VERSION "HINBNNNYNNNNNNNNNNNNNNNNNNNNNNNNNNNYYNNNNN/4>%%%/4/'%**4NNN///"

NS_ :

BS_:

BU_: Traffic Tester RCM FSC EPAS ECB DSC CGW

BO_ 960 IP_Switch_Information: 8 CGW
 SG_ HazardSw_D_Actl : 60|2@0+ (1,0) [0|0] ""  RCM
 SG_ RearDef_B_Rq : 61|1@0+ (1,0) [0|0] "" Vector__XXX
 SG_ FrontDef_B_Rq : 62|1@0+ (1,0) [0|0] "" Vector__XXX
 SG_ PanelHeaterSwitchIn_RH : 49|3@0+ (1,0) [0|0] "" Vector__XXX
 SG_ PanelHeaterSwitchIn_LH : 52|3@0+ (1,0) [0|0] "" Vector__XXX
 SG_ SteeringHeaterSwitchIn : 55|3@0+ (1,0) [0|0] "" Vector__XXX
 SG_ SeatVentilationSwitchIn_RH : 42|3@0+ (1,0) [0|0] "" Vector__XXX
 SG_ SeatHeaterSwitchIn_RH : 45|3@0+ (1,0) [0|0] "" Vector__XXX
 SG_ SeatVentilationSwitchIn_LH : 32|3@0+ (1,0) [0|0] "" Vector__XXX
 SG_ SeatHeaterSwitchIn_LH : 35|3@0+ (1,0) [0|0] "" Vector__XXX
 SG_ ipREARmode : 37|2@0+ (1,0) [0|0] "" Vector__XXX
 SG_ ipECOmode : 39|2@0+ (1,0) [0|0] "" Vector__XXX
 SG_ ipAImode : 27|4@0+ (1,0) [0|0] "" Vector__XXX
 SG_ ipADmode : 31|4@0+ (1,0) [0|0] "" Vector__XXX
 SG_ ipACmode : 19|4@0+ (1,0) [0|0] "" Vector__XXX
 SG_ ipBlwLvl : 23|4@0+ (1,0) [0|0] "" Vector__XXX
 SG_ ipTSetPs : 15|8@0+ (0.1,12) [12|37.5] "deg.C" Vector__XXX
 SG_ ipTSetDr : 7|8@0+ (0.1,12) [12|37.5] "deg.C" Vector__XXX

BO_ 945 ABG1S01: 8 RCM
 SG_ SM3B1 : 63|8@0+ (1,0) [0|255] ""  CGW
 SG_ CDT_HV : 34|3@0+ (1,0) [0|7] ""  CGW
 SG_ CDT : 22|3@0+ (1,0) [0|7] ""  CGW

BO_ 865 ENG1D70: 8 CGW
 SG_ EDRENG04 : 31|8@0+ (1,0) [0|255] ""  RCM
 SG_ EDRENG03 : 23|8@0+ (1,0) [0|255] ""  RCM
 SG_ EDRENG02 : 15|8@0+ (1,0) [0|255] ""  RCM
 SG_ EDRENG01 : 7|8@0+ (1,0) [0|255] ""  RCM

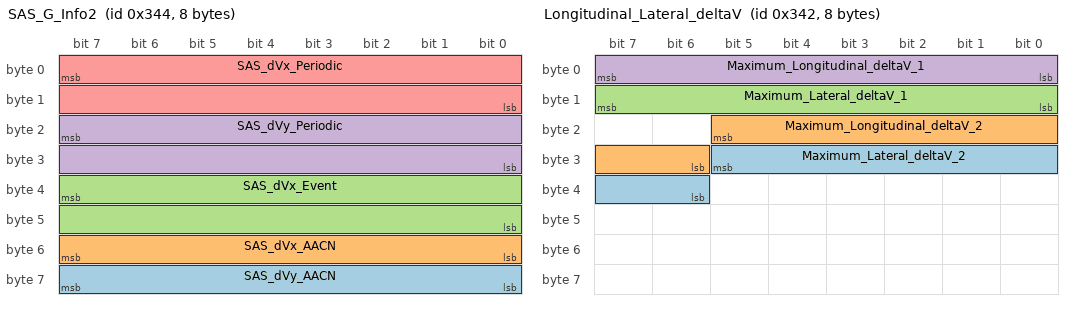
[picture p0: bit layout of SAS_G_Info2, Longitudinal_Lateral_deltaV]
BO_ 836 SAS_G_Info2: 8 RCM
 SG_ SAS_dVy_AACN : 63|8@0+ (1,-100) [-100|100] "km/h"  CGW
 SG_ SAS_dVx_AACN : 55|8@0+ (1,-100) [-100|100] "km/h"  CGW
 SG_ SAS_dVx_Event : 39|16@0+ (0.00353,-114.99681) [-114.99681|114.99681] "km/h"  CGW
 SG_ SAS_dVy_Periodic : 23|16@0+ (0.00353,-114.99681) [-114.99681|114.99681] "km/h"  CGW
 SG_ SAS_dVx_Periodic : 7|16@0+ (0.00353,-114.99681) [-114.99681|114.99681] "km/h"  CGW

BO_ 835 SAS_G_Info1: 8 RCM
 SG_ SAS_Gz : 19|14@0+ (0.0078125,-32) [-32|32] "G"  CGW
 SG_ SAS_Gy : 13|10@0+ (0.2,-96) [-96|96] "G"  CGW
 SG_ SAS_Gx : 7|10@0+ (0.2,-96) [-96|96] "G"  CGW

BO_ 834 Longitudinal_Lateral_deltaV: 8 RCM
 SG_ Maximum_Lateral_deltaV_2 : 29|8@0+ (1,-100) [-100|100] "km/h"  CGW
 SG_ Maximum_Longitudinal_deltaV_2 : 21|8@0+ (1,-100) [-100|100] "km/h"  CGW
 SG_ Maximum_Lateral_deltaV_1 : 15|8@0+ (1,-100) [-100|100] "km/h"  CGW
 SG_ Maximum_Longitudinal_deltaV_1 : 7|8@0+ (1,-100) [-100|100] "km/h"  CGW

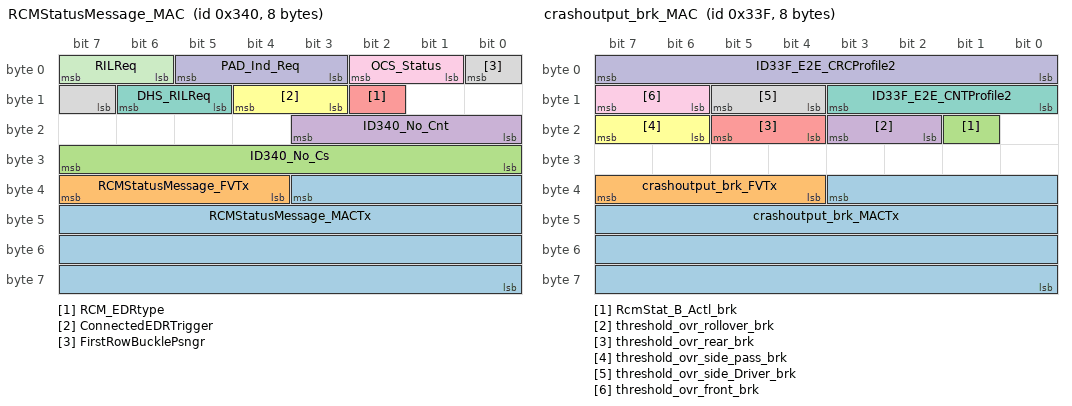
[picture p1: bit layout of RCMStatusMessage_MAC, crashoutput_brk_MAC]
BO_ 832 RCMStatusMessage_MAC: 8 RCM
 SG_ RCMStatusMessage_MACTx : 35|28@0+ (1,0) [0|268435455] ""  CGW
 SG_ RCMStatusMessage_FVTx : 39|4@0+ (1,0) [0|15] ""  CGW
 SG_ ID340_No_Cs : 31|8@0+ (1,0) [0|255] ""  CGW
 SG_ ID340_No_Cnt : 19|4@0+ (1,0) [0|15] ""  CGW
 SG_ RCM_EDRtype : 10|1@0+ (1,0) [0|0] ""  CGW
 SG_ ConnectedEDRTrigger : 12|2@0+ (1,0) [0|0] ""  CGW
 SG_ DHS_RILReq : 14|2@0+ (1,0) [0|0] ""  CGW
 SG_ FirstRowBucklePsngr : 0|2@0+ (1,0) [0|0] ""  CGW
 SG_ OCS_Status : 2|2@0+ (1,0) [0|0] ""  CGW
 SG_ PAD_Ind_Req : 5|3@0+ (1,0) [0|0] ""  CGW
 SG_ RILReq : 7|2@0+ (1,0) [0|0] ""  CGW

BO_ 831 crashoutput_brk_MAC: 8 RCM
 SG_ crashoutput_brk_MACTx : 35|28@0+ (1,0) [0|268435455] ""  DSC
 SG_ crashoutput_brk_FVTx : 39|4@0+ (1,0) [0|15] ""  DSC
 SG_ RcmStat_B_Actl_brk : 17|1@0+ (1,0) [0|0] ""  DSC
 SG_ threshold_ovr_rollover_brk : 19|2@0+ (1,0) [0|0] ""  DSC
 SG_ threshold_ovr_rear_brk : 21|2@0+ (1,0) [0|0] ""  DSC
 SG_ threshold_ovr_side_pass_brk : 23|2@0+ (1,0) [0|0] ""  DSC
 SG_ ID33F_E2E_CNTProfile2 : 11|4@0+ (1,0) [0|15] ""  DSC
 SG_ threshold_ovr_side_Driver_brk : 13|2@0+ (1,0) [0|0] ""  DSC
 SG_ threshold_ovr_front_brk : 15|2@0+ (1,0) [0|0] ""  DSC
 SG_ ID33F_E2E_CRCProfile2 : 7|8@0+ (1,0) [0|255] ""  DSC

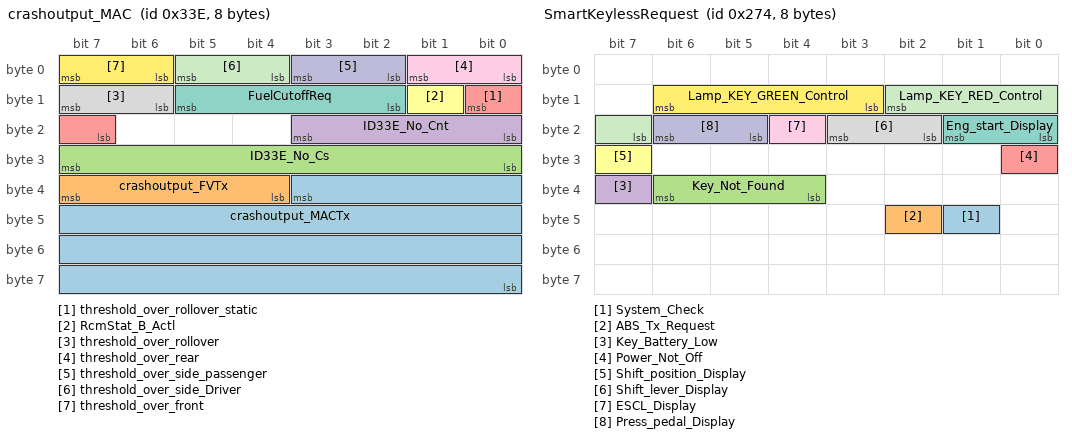
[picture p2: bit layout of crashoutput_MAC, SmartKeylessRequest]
BO_ 830 crashoutput_MAC: 8 RCM
 SG_ crashoutput_MACTx : 35|28@0+ (1,0) [0|268435455] ""  CGW
 SG_ crashoutput_FVTx : 39|4@0+ (1,0) [0|15] ""  CGW
 SG_ ID33E_No_Cs : 31|8@0+ (1,0) [0|255] ""  CGW
 SG_ ID33E_No_Cnt : 19|4@0+ (1,0) [0|15] ""  CGW
 SG_ threshold_over_rollover_static : 8|2@0+ (1,0) [0|0] ""  CGW
 SG_ RcmStat_B_Actl : 9|1@0+ (1,0) [0|0] ""  CGW
 SG_ FuelCutoffReq : 13|4@0+ (1,0) [0|0] ""  CGW
 SG_ threshold_over_rollover : 15|2@0+ (1,0) [0|0] ""  CGW
 SG_ threshold_over_rear : 1|2@0+ (1,0) [0|0] ""  CGW
 SG_ threshold_over_side_passenger : 3|2@0+ (1,0) [0|0] ""  CGW
 SG_ threshold_over_side_Driver : 5|2@0+ (1,0) [0|0] ""  CGW
 SG_ threshold_over_front : 7|2@0+ (1,0) [0|0] ""  CGW

BO_ 628 SmartKeylessRequest: 8 CGW
 SG_ System_Check : 41|1@0+ (1,0) [0|0] "" Vector__XXX
 SG_ ABS_Tx_Request : 42|1@0+ (1,0) [0|0] ""  DSC,ECB
 SG_ Key_Not_Found : 38|3@0+ (1,0) [0|0] "" Vector__XXX
 SG_ Key_Battery_Low : 39|1@0+ (1,0) [0|0] "" Vector__XXX
 SG_ Power_Not_Off : 24|1@0+ (1,0) [0|0] "" Vector__XXX
 SG_ Shift_position_Display : 31|1@0+ (1,0) [0|0] "" Vector__XXX
 SG_ Eng_start_Display : 17|2@0+ (1,0) [0|0] "" Vector__XXX
 SG_ Shift_lever_Display : 19|2@0+ (1,0) [0|0] "" Vector__XXX
 SG_ ESCL_Display : 20|1@0+ (1,0) [0|0] "" Vector__XXX
 SG_ Press_pedal_Display : 22|2@0+ (1,0) [0|0] "" Vector__XXX
 SG_ Lamp_KEY_RED_Control : 10|4@0+ (1,0) [0|0] "" Vector__XXX
 SG_ Lamp_KEY_GREEN_Control : 14|4@0+ (1,0) [0|0] "" Vector__XXX

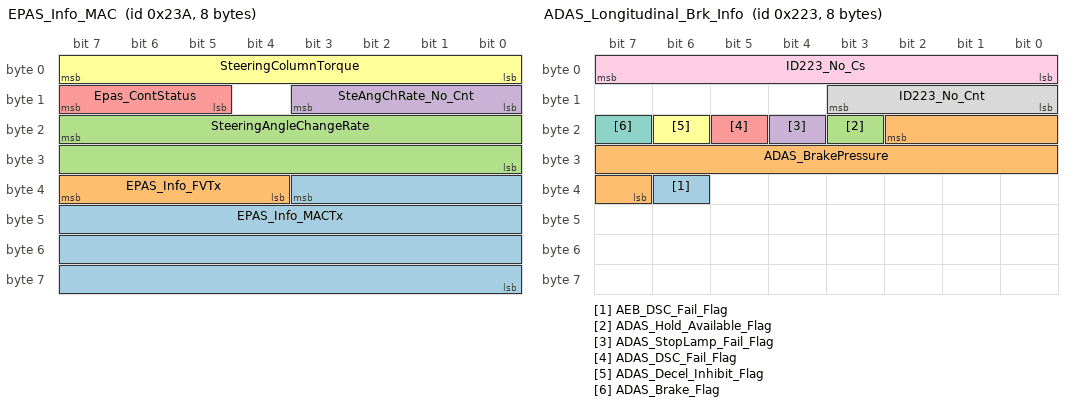
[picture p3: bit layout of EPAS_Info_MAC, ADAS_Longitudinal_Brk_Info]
BO_ 570 EPAS_Info_MAC: 8 EPAS
 SG_ EPAS_Info_MACTx : 35|28@0+ (1,0) [0|268435455] ""  CGW
 SG_ EPAS_Info_FVTx : 39|4@0+ (1,0) [0|15] ""  CGW
 SG_ SteeringAngleChangeRate : 23|16@0- (0.1,0) [-3276.8|3276.7] "deg/s"  CGW
 SG_ SteAngChRate_No_Cnt : 11|4@0+ (1,0) [0|15] ""  CGW
 SG_ Epas_ContStatus : 15|3@0+ (1,0) [0|0] ""  CGW
 SG_ SteeringColumnTorque : 7|8@0+ (0.1,-12.7) [-12.7|12.8] "Nm"  CGW

BO_ 552 TransGearData: 8 CGW
 SG_ ID228_No_Cs : 63|8@0+ (1,0) [0|255] "" Vector__XXX
 SG_ ID228_No_Cnt : 51|4@0+ (1,0) [0|15] "" Vector__XXX
 SG_ ShiftOpeWarning_D_Rq : 55|4@0+ (1,0) [0|0] "" Vector__XXX
 SG_ ShiftPos_D_Act : 43|4@0+ (1,0) [0|0] "" Vector__XXX
 SG_ TransmChangeLeverPosition : 47|4@0+ (1,0) [0|0] "" Vector__XXX
 SG_ DispAtLvrPos_ArrowReq : 32|1@0+ (1,0) [0|0] "" Vector__XXX
 SG_ ShiftPos_D_Trg : 36|4@0+ (1,0) [0|0] ""  RCM
 SG_ DispAtLvrPos_Off_Req : 37|1@0+ (1,0) [0|0] "" Vector__XXX
 SG_ AT_INDLvl_D_Rq : 39|2@0+ (1,0) [0|0] "" Vector__XXX
 SG_ AT_FailSafeLvl_D_Rq : 25|2@0+ (1,0) [0|0] "" Vector__XXX
 SG_ PwrDwn_D_Req_ByTCM : 27|2@0+ (1,0) [0|0] "" Vector__XXX
 SG_ SBW_INDLvl_D_Rq : 29|2@0+ (1,0) [0|0] "" Vector__XXX
 SG_ ParkLockWarning_D_Rq : 31|2@0+ (1,0) [0|0] "" Vector__XXX
 SG_ ShiftrPos_D_Qf : 17|2@0+ (1,0) [0|0] "" Vector__XXX
 SG_ SbwWarningLamp_B_Rq : 18|1@0+ (1,0) [0|0] "" Vector__XXX
 SG_ TransmParking_D_Act : 21|3@0+ (1,0) [0|0] "" Vector__XXX
 SG_ TrnSlaCtl_B_Rq : 22|1@0+ (1,0) [0|0] "" Vector__XXX
 SG_ TrnSlaCtlFlag : 23|1@0+ (1,0) [0|0] "" Vector__XXX
 SG_ TrnShifActv_B_Actl : 8|1@0+ (1,0) [0|0] "" Vector__XXX
 SG_ AT_OILTEMPHi_D_Rq : 10|2@0+ (1,0) [0|0] "" Vector__XXX
 SG_ TrnCnvtClu_D_Actl : 12|2@0+ (1,0) [0|0] "" Vector__XXX
 SG_ DispGearPos_FlashReq : 13|1@0+ (1,0) [0|0] "" Vector__XXX
 SG_ OD_Hold_Sport_Flash : 14|1@0+ (1,0) [0|0] "" Vector__XXX
 SG_ DispAtLvrPos_FlashReq : 15|1@0+ (1,0) [0|0] "" Vector__XXX
 SG_ DispAtLvrPos_D_Rq : 3|4@0+ (1,0) [0|0] "" Vector__XXX
 SG_ DispGearPos_D_Rq : 7|4@0+ (1,0) [0|0] "" Vector__XXX

BO_ 547 ADAS_Longitudinal_Brk_Info: 8 DSC
 SG_ AEB_DSC_Fail_Flag : 38|1@0+ (1,0) [0|0] ""  CGW
 SG_ ADAS_BrakePressure : 18|12@0+ (1,-94) [-94|4000] "Nm"  CGW
 SG_ ADAS_Hold_Available_Flag : 19|1@0+ (1,0) [0|0] ""  CGW
 SG_ ADAS_StopLamp_Fail_Flag : 20|1@0+ (1,0) [0|0] ""  CGW
 SG_ ADAS_DSC_Fail_Flag : 21|1@0+ (1,0) [0|0] ""  CGW
 SG_ ADAS_Decel_Inhibit_Flag : 22|1@0+ (1,0) [0|0] ""  CGW
 SG_ ADAS_Brake_Flag : 23|1@0+ (1,0) [0|0] ""  CGW
 SG_ ID223_No_Cnt : 11|4@0+ (1,0) [0|15] ""  CGW
 SG_ ID223_No_Cs : 7|8@0+ (1,0) [0|255] ""  CGW

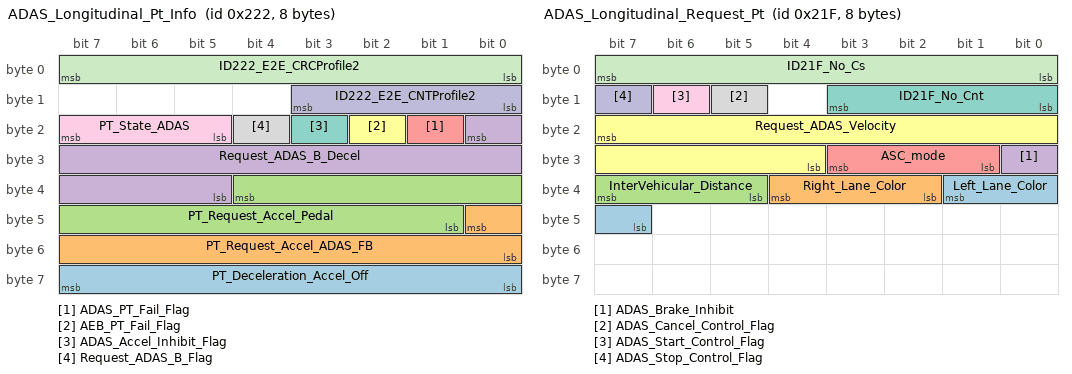
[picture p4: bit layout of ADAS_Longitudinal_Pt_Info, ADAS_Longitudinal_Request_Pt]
BO_ 546 ADAS_Longitudinal_Pt_Info: 8 DSC
 SG_ PT_Deceleration_Accel_Off : 63|8@0+ (0.02,-2.5) [-2.5|2.5] "m/sec2"  CGW
 SG_ PT_Request_Accel_ADAS_FB : 40|9@0+ (0.01,-2.5) [-2.5|2.5] "m/sec2"  CGW
 SG_ PT_Request_Accel_Pedal : 36|12@0+ (0.01,-20) [-20|20] "m/sec2"  CGW
 SG_ Request_ADAS_B_Decel : 16|12@0+ (0.005,-10) [-10|10] "m/sec2"  CGW
 SG_ ADAS_PT_Fail_Flag : 17|1@0+ (1,0) [0|0] ""  CGW
 SG_ AEB_PT_Fail_Flag : 18|1@0+ (1,0) [0|0] ""  CGW
 SG_ ADAS_Accel_Inhibit_Flag : 19|1@0+ (1,0) [0|0] ""  CGW
 SG_ Request_ADAS_B_Flag : 20|1@0+ (1,0) [0|0] ""  CGW
 SG_ PT_State_ADAS : 23|3@0+ (1,0) [0|0] ""  CGW
 SG_ ID222_E2E_CNTProfile2 : 11|4@0+ (1,0) [0|15] ""  CGW
 SG_ ID222_E2E_CRCProfile2 : 7|8@0+ (1,0) [0|255] ""  CGW

BO_ 543 ADAS_Longitudinal_Request_Pt: 8 CGW
 SG_ Left_Lane_Color : 33|3@0+ (1,0) [0|0] ""  DSC
 SG_ Right_Lane_Color : 36|3@0+ (1,0) [0|0] ""  DSC
 SG_ InterVehicular_Distance : 39|3@0+ (1,0) [0|0] ""  DSC
 SG_ ADAS_Brake_Inhibit : 24|1@0+ (1,0) [0|0] ""  DSC
 SG_ ASC_mode : 27|3@0+ (1,0) [0|0] ""  DSC
 SG_ Request_ADAS_Velocity : 23|12@0+ (0.05,0) [0|200] "km/h"  DSC
 SG_ ID21F_No_Cnt : 11|4@0+ (1,0) [0|15] ""  DSC
 SG_ ADAS_Cancel_Control_Flag : 13|1@0+ (1,0) [0|0] ""  DSC
 SG_ ADAS_Start_Control_Flag : 14|1@0+ (1,0) [0|0] ""  DSC
 SG_ ADAS_Stop_Control_Flag : 15|1@0+ (1,0) [0|0] ""  DSC
 SG_ ID21F_No_Cs : 7|8@0+ (1,0) [0|255] ""  DSC

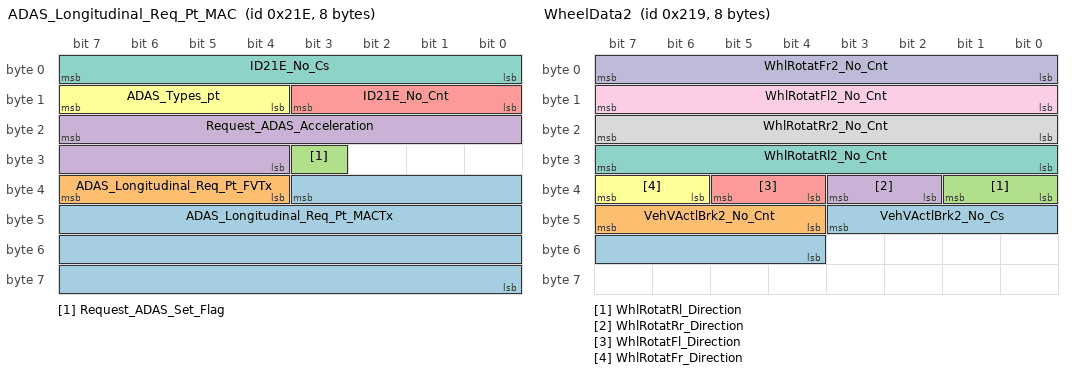
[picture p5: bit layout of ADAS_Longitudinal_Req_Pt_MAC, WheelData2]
BO_ 542 ADAS_Longitudinal_Req_Pt_MAC: 8 CGW
 SG_ ADAS_Longitudinal_Req_Pt_MACTx : 35|28@0+ (1,0) [0|268435455] ""  DSC
 SG_ ADAS_Longitudinal_Req_Pt_FVTx : 39|4@0+ (1,0) [0|15] ""  DSC
 SG_ Request_ADAS_Set_Flag : 27|1@0+ (1,0) [0|0] ""  DSC
 SG_ Request_ADAS_Acceleration : 23|12@0+ (0.005,-10) [-10|10] "m/sec2"  DSC
 SG_ ID21E_No_Cnt : 11|4@0+ (1,0) [0|15] ""  DSC
 SG_ ADAS_Types_pt : 15|4@0+ (1,0) [0|0] ""  DSC
 SG_ ID21E_No_Cs : 7|8@0+ (1,0) [0|255] ""  DSC

BO_ 537 WheelData2: 8 DSC
 SG_ VehVActlBrk2_No_Cs : 43|8@0+ (1,0) [0|255] ""  CGW
 SG_ VehVActlBrk2_No_Cnt : 47|4@0+ (1,0) [0|15] ""  CGW
 SG_ WhlRotatRl_Direction : 33|2@0+ (1,0) [0|0] ""  CGW
 SG_ WhlRotatRr_Direction : 35|2@0+ (1,0) [0|0] ""  CGW
 SG_ WhlRotatFl_Direction : 37|2@0+ (1,0) [0|0] ""  CGW
 SG_ WhlRotatFr_Direction : 39|2@0+ (1,0) [0|0] ""  CGW
 SG_ WhlRotatRl2_No_Cnt : 31|8@0+ (1,0) [0|255] ""  CGW
 SG_ WhlRotatRr2_No_Cnt : 23|8@0+ (1,0) [0|255] ""  CGW
 SG_ WhlRotatFl2_No_Cnt : 15|8@0+ (1,0) [0|255] ""  CGW
 SG_ WhlRotatFr2_No_Cnt : 7|8@0+ (1,0) [0|255] ""  CGW

BO_ 533 WheelSpeed: 8 DSC
 SG_ RRwheelSpeed : 55|16@0+ (0.01,-100) [-100|300] "km/h"  CGW,EPAS
 SG_ RLwheelSpeed : 39|16@0+ (0.01,-100) [-100|300] "km/h"  CGW,EPAS
 SG_ FRwheelSpeed : 23|16@0+ (0.01,-100) [-100|300] "km/h"  CGW,EPAS
 SG_ FLwheelSpeed : 7|16@0+ (0.01,-100) [-100|300] "km/h"  CGW,EPAS

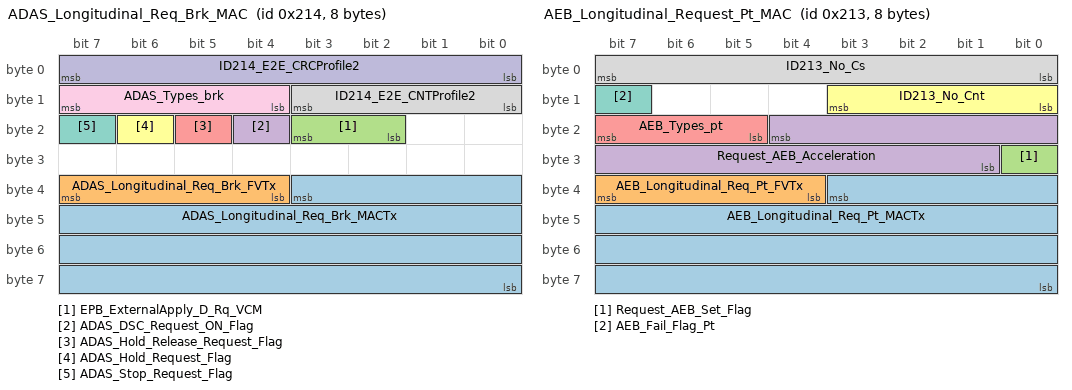
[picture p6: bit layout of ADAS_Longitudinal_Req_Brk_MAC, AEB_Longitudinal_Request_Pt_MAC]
BO_ 532 ADAS_Longitudinal_Req_Brk_MAC: 8 CGW
 SG_ ADAS_Longitudinal_Req_Brk_MACTx : 35|28@0+ (1,0) [0|268435455] ""  DSC
 SG_ ADAS_Longitudinal_Req_Brk_FVTx : 39|4@0+ (1,0) [0|15] ""  DSC
 SG_ EPB_ExternalApply_D_Rq_VCM : 19|2@0+ (1,0) [0|0] ""  DSC
 SG_ ADAS_DSC_Request_ON_Flag : 20|1@0+ (1,0) [0|0] ""  DSC
 SG_ ADAS_Hold_Release_Request_Flag : 21|1@0+ (1,0) [0|0] ""  DSC
 SG_ ADAS_Hold_Request_Flag : 22|1@0+ (1,0) [0|0] ""  DSC
 SG_ ADAS_Stop_Request_Flag : 23|1@0+ (1,0) [0|0] ""  DSC
 SG_ ID214_E2E_CNTProfile2 : 11|4@0+ (1,0) [0|15] ""  DSC
 SG_ ADAS_Types_brk : 15|4@0+ (1,0) [0|0] ""  DSC
 SG_ ID214_E2E_CRCProfile2 : 7|8@0+ (1,0) [0|255] ""  DSC

BO_ 531 AEB_Longitudinal_Request_Pt_MAC: 8 CGW
 SG_ AEB_Longitudinal_Req_Pt_MACTx : 35|28@0+ (1,0) [0|268435455] ""  DSC
 SG_ AEB_Longitudinal_Req_Pt_FVTx : 39|4@0+ (1,0) [0|15] ""  DSC
 SG_ Request_AEB_Set_Flag : 24|1@0+ (1,0) [0|0] ""  DSC,RCM
 SG_ Request_AEB_Acceleration : 20|12@0+ (0.005,-10) [-10|10] "m/sec2"  DSC,RCM
 SG_ AEB_Types_pt : 23|3@0+ (1,0) [0|0] ""  DSC,RCM
 SG_ ID213_No_Cnt : 11|4@0+ (1,0) [0|15] ""  DSC
 SG_ AEB_Fail_Flag_Pt : 15|1@0+ (1,0) [0|0] ""  DSC
 SG_ ID213_No_Cs : 7|8@0+ (1,0) [0|255] ""  DSC

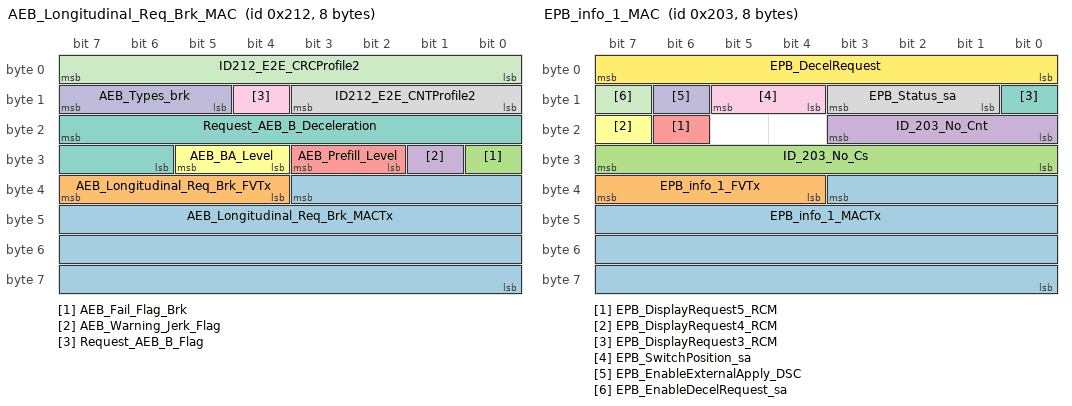
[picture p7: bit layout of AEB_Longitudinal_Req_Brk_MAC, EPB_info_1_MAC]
BO_ 530 AEB_Longitudinal_Req_Brk_MAC: 8 CGW
 SG_ AEB_Longitudinal_Req_Brk_MACTx : 35|28@0+ (1,0) [0|268435455] ""  DSC,RCM
 SG_ AEB_Longitudinal_Req_Brk_FVTx : 39|4@0+ (1,0) [0|15] ""  DSC,RCM
 SG_ AEB_Fail_Flag_Brk : 24|1@0+ (1,0) [0|0] ""  DSC,RCM
 SG_ AEB_Warning_Jerk_Flag : 25|1@0+ (1,0) [0|0] ""  DSC
 SG_ AEB_Prefill_Level : 27|2@0+ (1,0) [0|0] ""  DSC
 SG_ AEB_BA_Level : 29|2@0+ (1,0) [0|0] ""  DSC
 SG_ Request_AEB_B_Deceleration : 23|10@0+ (0.01,0) [0|10.23] "m/sec2"  DSC,RCM
 SG_ ID212_E2E_CNTProfile2 : 11|4@0+ (1,0) [0|15] ""  DSC
 SG_ Request_AEB_B_Flag : 12|1@0+ (1,0) [0|0] ""  DSC,RCM
 SG_ AEB_Types_brk : 15|3@0+ (1,0) [0|0] ""  DSC
 SG_ ID212_E2E_CRCProfile2 : 7|8@0+ (1,0) [0|255] ""  DSC

BO_ 520 DesiredTorqBrk_MAC: 8 DSC
 SG_ DesiredTorqBrk_MACTx : 35|28@0+ (1,0) [0|268435455] ""  CGW,RCM
 SG_ DesiredTorqBrk_FVTx : 39|4@0+ (1,0) [0|15] ""  CGW,RCM
 SG_ PrplWhlTqRqMn_MAC_No_Cs : 31|8@0+ (1,0) [0|255] ""  CGW,RCM
 SG_ PrplWhlTqRqMn_MAC_No_Cnt : 19|4@0+ (1,0) [0|15] ""  CGW,RCM
 SG_ AccPedalPos : 11|8@0+ (0.5,0) [0|100] "%"  CGW,RCM
 SG_ ADAS_Brake_Flag_copy : 12|1@0+ (1,0) [0|0] ""  CGW
 SG_ Abs_B_Falt : 13|1@0+ (1,0) [0|0] ""  CGW,RCM
 SG_ TsaCtlActv_B_Actl : 14|1@0+ (1,0) [0|0] ""  CGW
 SG_ RolStabCtlActv_B_Actl : 15|1@0+ (1,0) [0|0] ""  CGW
 SG_ PrplDrgCtlActv_B_Actl : 0|1@0+ (1,0) [0|0] ""  CGW
 SG_ TracCtlPtActv_B_Actl : 1|1@0+ (1,0) [0|0] ""  CGW,RCM
 SG_ TracCtlBrkActv_B_Actl : 2|1@0+ (1,0) [0|0] ""  CGW,RCM
 SG_ DSC_OnOff_status_1 : 3|1@0+ (1,0) [0|0] ""  CGW
 SG_ StabCtlBrkActv_B_Actl : 4|1@0+ (1,0) [0|0] ""  CGW,RCM
 SG_ BrkAsst_B_Actl : 5|1@0+ (1,0) [0|0] ""  CGW
 SG_ AbsActv_B_Actl : 6|1@0+ (1,0) [0|0] ""  CGW,RCM
 SG_ EbdActv_B_Actl : 7|1@0+ (1,0) [0|0] ""  CGW

BO_ 515 EPB_info_1_MAC: 8 CGW
 SG_ EPB_info_1_MACTx : 35|28@0+ (1,0) [0|268435455] ""  DSC,RCM,ECB
 SG_ EPB_info_1_FVTx : 39|4@0+ (1,0) [0|15] ""  DSC,RCM,ECB
 SG_ ID_203_No_Cs : 31|8@0+ (1,0) [0|255] ""  DSC,ECB
 SG_ ID_203_No_Cnt : 19|4@0+ (1,0) [0|15] ""  DSC,ECB
 SG_ EPB_DisplayRequest5_RCM : 22|1@0+ (1,0) [0|0] ""  RCM
 SG_ EPB_DisplayRequest4_RCM : 23|1@0+ (1,0) [0|0] ""  RCM
 SG_ EPB_DisplayRequest3_RCM : 8|1@0+ (1,0) [0|0] ""  RCM
 SG_ EPB_Status_sa : 11|3@0+ (1,0) [0|0] ""  DSC,RCM,ECB
 SG_ EPB_SwitchPosition_sa : 13|2@0+ (1,0) [0|0] ""  DSC,ECB
 SG_ EPB_EnableExternalApply_DSC : 14|1@0+ (1,0) [0|0] ""  DSC
 SG_ EPB_EnableDecelRequest_sa : 15|1@0+ (1,0) [0|0] ""  DSC
 SG_ EPB_DecelRequest : 7|8@0+ (0.048,-7.968) [-7.968|4.224] "m/s^2"  DSC

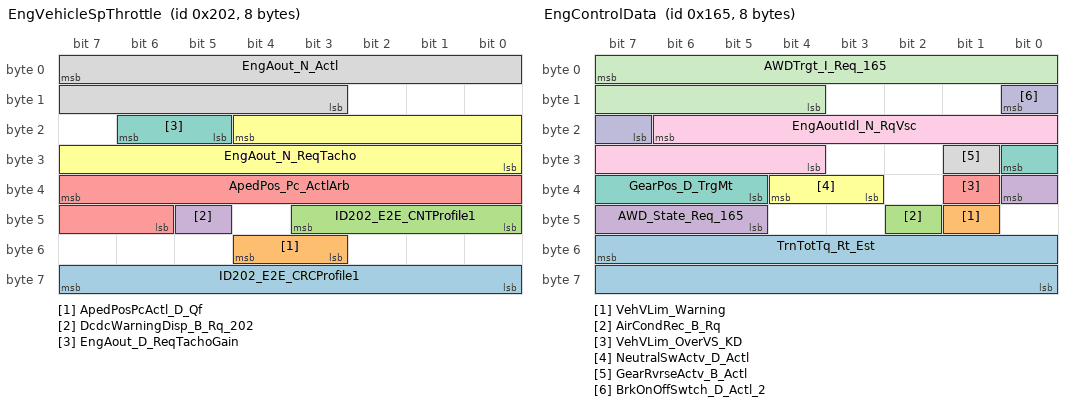
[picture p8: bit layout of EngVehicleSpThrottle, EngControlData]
BO_ 514 EngVehicleSpThrottle: 8 CGW
 SG_ ID202_E2E_CRCProfile1 : 63|8@0+ (1,0) [0|255] ""  RCM
 SG_ ApedPosPcActl_D_Qf : 52|2@0+ (1,0) [0|0] ""  RCM
 SG_ ID202_E2E_CNTProfile1 : 43|4@0+ (1,0) [0|14] "" Vector__XXX
 SG_ DcdcWarningDisp_B_Rq_202 : 45|1@0+ (1,0) [0|0] "" Vector__XXX
 SG_ ApedPos_Pc_ActlArb : 39|10@0+ (0.1,0) [0|102.3] "%"  RCM
 SG_ EngAout_N_ReqTacho : 20|13@0+ (2,0) [0|16380] "rpm" Vector__XXX
 SG_ EngAout_D_ReqTachoGain : 22|2@0+ (1,0) [0|0] "" Vector__XXX
 SG_ EngAout_N_Actl : 7|13@0+ (2,0) [0|16380] "rpm"  RCM,EPAS

BO_ 357 EngControlData: 8 CGW
 SG_ TrnTotTq_Rt_Est : 55|16@0+ (0.001,0) [0|65.533] "" Vector__XXX
 SG_ VehVLim_Warning : 41|1@0+ (1,0) [0|0] "" Vector__XXX
 SG_ AirCondRec_B_Rq : 42|1@0+ (1,0) [0|0] "" Vector__XXX
 SG_ AWD_State_Req_165 : 32|4@0+ (1,0) [0|0] "" Vector__XXX
 SG_ VehVLim_OverVS_KD : 33|1@0+ (1,0) [0|0] "" Vector__XXX
 SG_ NeutralSwActv_D_Actl : 36|2@0+ (1,0) [0|0] ""  RCM
 SG_ GearPos_D_TrgMt : 24|4@0+ (1,0) [0|0] ""  RCM
 SG_ GearRvrseActv_B_Actl : 25|1@0+ (1,0) [0|0] "" Vector__XXX
 SG_ EngAoutIdl_N_RqVsc : 22|11@0+ (2,0) [0|4094] "rpm" Vector__XXX
 SG_ BrkOnOffSwtch_D_Actl_2 : 8|2@0+ (1,0) [0|0] ""  RCM
 SG_ AWDTrgt_I_Req_165 : 7|12@0+ (0.015,0) [0|6] "A" Vector__XXX

BO_ 304 SISS_Rqst: 8 CGW
 SG_ Clutch_Stroke : 63|8@0+ (0.5,0) [0|100] "%" Vector__XXX
 SG_ EngAout_N_RqTacho : 44|13@0+ (2,0) [0|16382] "RPM" Vector__XXX
 SG_ PTiStpRdy_B_Actl : 32|1@0+ (1,0) [0|0] "" Vector__XXX
 SG_ iStpDenyBrk_B_Actl : 33|1@0+ (1,0) [0|0] "" Vector__XXX
 SG_ iStpDenyPwStr_B_Actl : 34|1@0+ (1,0) [0|0] "" Vector__XXX
 SG_ iStpKeySta_B_Actl : 35|1@0+ (1,0) [0|0] "" Vector__XXX
 SG_ iStpDenyAC_B_Actl : 36|1@0+ (1,0) [0|0] "" Vector__XXX
 SG_ iStpDenyNrange_B_Actl : 37|1@0+ (1,0) [0|0] "" Vector__XXX
 SG_ iStpDenyDPF_B_Actl : 38|1@0+ (1,0) [0|0] "" Vector__XXX
 SG_ ELM_IRCutReq : 25|1@0+ (1,0) [0|0] "" Vector__XXX
 SG_ BatteryWeakenFlag : 26|1@0+ (1,0) [0|0] "" Vector__XXX
 SG_ iStpDoorOpen_B_Actl : 27|1@0+ (1,0) [0|0] "" Vector__XXX
 SG_ SISS_EngineState : 31|4@0+ (1,0) [0|0] ""  EPAS
 SG_ SISS_IRCutReq : 16|1@0+ (1,0) [0|0] "" Vector__XXX
 SG_ SKE_Control : 18|2@0+ (1,0) [0|0] "" Vector__XXX
 SG_ SISS_Mode_for_SKE : 19|1@0+ (1,0) [0|0] "" Vector__XXX
 SG_ iStpReady_Rq : 20|1@0+ (1,0) [0|0] "" Vector__XXX
 SG_ iStpDenyBatt_B_Actl : 21|1@0+ (1,0) [0|0] "" Vector__XXX
 SG_ SlaCtl_B_Rq : 22|1@0+ (1,0) [0|0] "" Vector__XXX
 SG_ SISS_WarningLamp_R : 9|3@0+ (1,0) [0|0] "" Vector__XXX
 SG_ SISS_WarningLamp_G : 12|3@0+ (1,0) [0|0] "" Vector__XXX
 SG_ SISS_AlarmBuzzer : 15|3@0+ (1,0) [0|0] "" Vector__XXX
 SG_ SISSStatus : 0|1@0+ (1,0) [0|0] "" Vector__XXX
 SG_ SrlyUpper_Connect_Rq : 2|2@0+ (1,0) [0|0] "" Vector__XXX

BO_ 253 ECM_Status: 8 CGW
 SG_ Xev_Charge_Req_PCM : 58|3@0+ (1,0) [0|0] "" Vector__XXX
 SG_ PTGeneralWarn_Mirror : 59|1@0+ (1,0) [0|0] "" Vector__XXX
 SG_ Drive_Mode_Req_PCM : 63|4@0+ (1,0) [0|0] "" Vector__XXX
 SG_ Drive_Mode_Towing_Req_PCM : 49|2@0+ (1,0) [0|0] "" Vector__XXX
 SG_ Drive_Mode_OffRoad_Req_PCM : 51|2@0+ (1,0) [0|0] "" Vector__XXX
 SG_ Drive_Mode_Sport_Req_PCM : 53|2@0+ (1,0) [0|0] "" Vector__XXX
 SG_ Drive_Mode_Normal_Req_PCM : 55|2@0+ (1,0) [0|0] "" Vector__XXX
 SG_ ATFalseStartWarning : 40|1@0+ (1,0) [0|0] "" Vector__XXX
 SG_ BattRgenStat_B_Actl : 41|1@0+ (1,0) [0|0] "" Vector__XXX
 SG_ RegenBrkFailWarning : 42|1@0+ (1,0) [0|0] "" Vector__XXX
 SG_ BmsWarn_B_Rq : 43|1@0+ (1,0) [0|0] "" Vector__XXX
 SG_ SmtAclInh_B_Actl : 44|1@0+ (1,0) [0|0] "" Vector__XXX
 SG_ BrakeSw_Fail_Warning : 45|1@0+ (1,0) [0|0] "" Vector__XXX
 SG_ BOS_Active_B_Actl : 46|1@0+ (1,0) [0|0] "" Vector__XXX
 SG_ DriveMode_Hold_Rq_PCM : 47|1@0+ (1,0) [0|0] "" Vector__XXX
 SG_ GlobalConfgWarn_B_Rq : 32|1@0+ (1,0) [0|0] "" Vector__XXX
 SG_ CrankingTime : 37|5@0+ (1,0) [2|31] "sec" Vector__XXX
 SG_ ApedOnN_B_Rq : 38|1@0+ (1,0) [0|0] "" Vector__XXX
 SG_ IG_OFF_Delay_Request : 39|1@0+ (1,0) [0|0] "" Vector__XXX
 SG_ Crank_wait : 31|8@0+ (1,0) [0|0] "" Vector__XXX
 SG_ SilGearPosActl_D_Dsply : 19|4@0+ (1,0) [0|0] "" Vector__XXX
 SG_ Xev_Ev_Req_PCM : 22|3@0+ (1,0) [0|0] "" Vector__XXX
 SG_ VspLmtAlarm_B_Rq : 23|1@0+ (1,0) [0|0] "" Vector__XXX
 SG_ PTGeneralWarn_B_Rq : 8|1@0+ (1,0) [0|0] "" Vector__XXX
 SG_ SRLY_state : 9|1@0+ (1,0) [0|0] "" Vector__XXX
 SG_ SilGearPos_D_Dsply : 13|4@0+ (1,0) [0|0] "" Vector__XXX
 SG_ VspLmtWarn_B_Rq : 15|2@0+ (1,0) [0|0] "" Vector__XXX
 SG_ KeyState : 2|3@0+ (1,0) [0|0] "" Vector__XXX
 SG_ ShiftIndicatorLight : 4|2@0+ (1,0) [0|0] "" Vector__XXX
 SG_ PowerSourceStatus : 7|3@0+ (1,0) [0|0] ""  RCM,EPAS

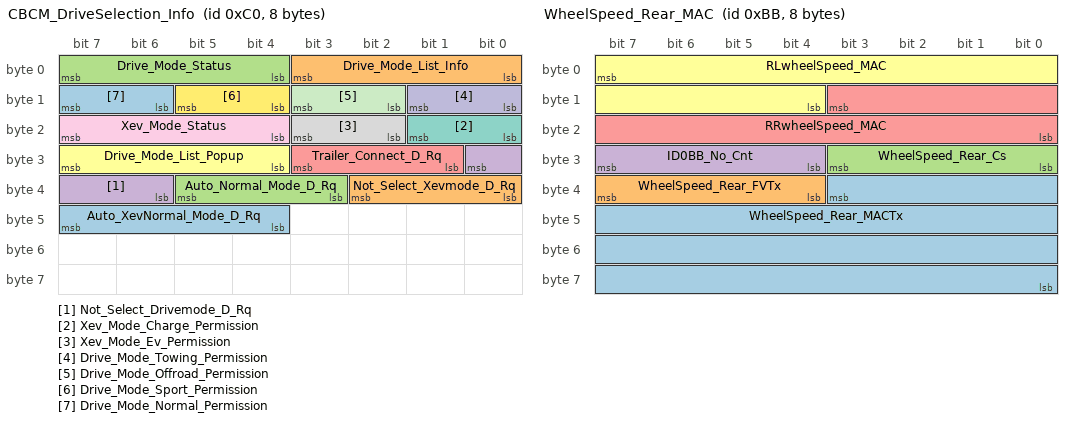
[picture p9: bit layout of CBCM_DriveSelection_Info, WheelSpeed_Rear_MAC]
BO_ 192 CBCM_DriveSelection_Info: 8 CGW
 SG_ Auto_XevNormal_Mode_D_Rq : 47|4@0+ (1,0) [0|0] "" Vector__XXX
 SG_ Not_Select_Xevmode_D_Rq : 34|3@0+ (1,0) [0|0] "" Vector__XXX
 SG_ Auto_Normal_Mode_D_Rq : 37|3@0+ (1,0) [0|0] "" Vector__XXX
 SG_ Not_Select_Drivemode_D_Rq : 24|3@0+ (1,0) [0|0] "" Vector__XXX
 SG_ Trailer_Connect_D_Rq : 27|3@0+ (1,0) [0|0] "" Vector__XXX
 SG_ Drive_Mode_List_Popup : 31|4@0+ (1,0) [0|0] "" Vector__XXX
 SG_ Xev_Mode_Charge_Permission : 17|2@0+ (1,0) [0|0] "" Vector__XXX
 SG_ Xev_Mode_Ev_Permission : 19|2@0+ (1,0) [0|0] "" Vector__XXX
 SG_ Xev_Mode_Status : 23|4@0+ (1,0) [0|0] "" Vector__XXX
 SG_ Drive_Mode_Towing_Permission : 9|2@0+ (1,0) [0|0] "" Vector__XXX
 SG_ Drive_Mode_Offroad_Permission : 11|2@0+ (1,0) [0|0] "" Vector__XXX
 SG_ Drive_Mode_Sport_Permission : 13|2@0+ (1,0) [0|0] "" Vector__XXX
 SG_ Drive_Mode_Normal_Permission : 15|2@0+ (1,0) [0|0] "" Vector__XXX
 SG_ Drive_Mode_List_Info : 3|4@0+ (1,0) [0|0] "" Vector__XXX
 SG_ Drive_Mode_Status : 7|4@0+ (1,0) [0|0] ""  DSC

BO_ 187 WheelSpeed_Rear_MAC: 8 DSC
 SG_ WheelSpeed_Rear_MACTx : 35|28@0+ (1,0) [0|268435455] ""  CGW
 SG_ WheelSpeed_Rear_FVTx : 39|4@0+ (1,0) [0|15] ""  CGW
 SG_ WheelSpeed_Rear_Cs : 27|4@0+ (1,0) [0|15] ""  CGW
 SG_ ID0BB_No_Cnt : 31|4@0+ (1,0) [0|15] ""  CGW
 SG_ RRwheelSpeed_MAC : 11|12@0+ (0.1,0) [0|300] "km/h"  CGW
 SG_ RLwheelSpeed_MAC : 7|12@0+ (0.1,0) [0|300] "km/h"  CGW

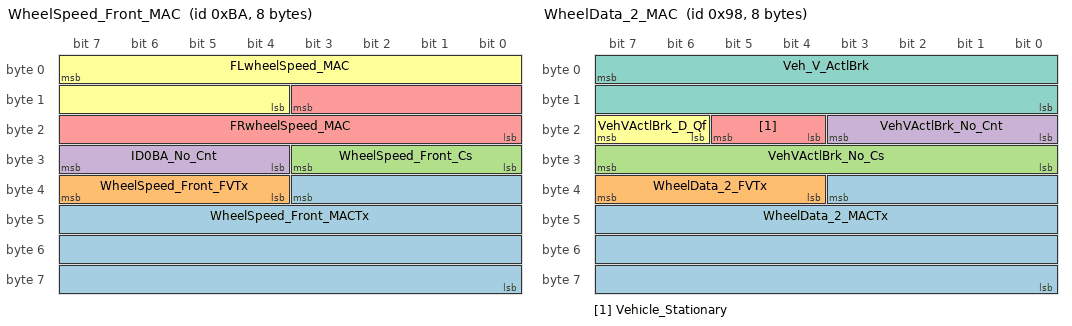
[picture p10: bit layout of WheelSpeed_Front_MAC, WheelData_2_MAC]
BO_ 186 WheelSpeed_Front_MAC: 8 DSC
 SG_ WheelSpeed_Front_MACTx : 35|28@0+ (1,0) [0|268435455] ""  CGW
 SG_ WheelSpeed_Front_FVTx : 39|4@0+ (1,0) [0|15] ""  CGW
 SG_ WheelSpeed_Front_Cs : 27|4@0+ (1,0) [0|15] ""  CGW
 SG_ ID0BA_No_Cnt : 31|4@0+ (1,0) [0|15] ""  CGW
 SG_ FRwheelSpeed_MAC : 11|12@0+ (0.1,0) [0|300] "km/h"  CGW
 SG_ FLwheelSpeed_MAC : 7|12@0+ (0.1,0) [0|300] "km/h"  CGW

BO_ 159 CBCM_IllumStatus: 8 CGW
 SG_ BpedDrvAppl_D_Actl : 59|2@0+ (1,0) [0|0] ""  DSC,ECB
 SG_ IndirectIllumination_D_Rq : 63|3@0+ (1,0) [0|0] "" Vector__XXX
 SG_ WelcomIllumination_D_Rq : 49|2@0+ (1,0) [0|0] "" Vector__XXX
 SG_ FootLamp_D_Rq : 52|3@0+ (1,0) [0|0] "" Vector__XXX
 SG_ DoorCourtesyLamp_D_Rq : 54|2@0+ (1,0) [0|0] "" Vector__XXX
 SG_ CargoLamp_D_Rq : 40|2@0+ (1,0) [0|0] "" Vector__XXX
 SG_ CBCM_Control_No_Cnt : 44|4@0+ (1,0) [0|15] ""  DSC,ECB
 SG_ DimmerCancel : 46|2@0+ (1,0) [0|0] "" Vector__XXX
 SG_ EngOff_T_Actl : 30|16@0+ (1,0) [0|65534] "" Vector__XXX
 SG_ Drive_Mode_FlashReq : 16|2@0+ (1,0) [0|0] "" Vector__XXX
 SG_ Drive_Mode_Enabled : 18|2@0+ (1,0) [0|0] "" Vector__XXX
 SG_ CarMde_D_Actl : 22|4@0+ (1,0) [0|0] "" Vector__XXX
 SG_ PanelBrightLevel_Pc_Actl : 14|8@0+ (1,0) [0|100] "%" Vector__XXX
 SG_ Reverselamp_B_Req : 1|1@0+ (1,0) [0|0] "" Vector__XXX
 SG_ IlumiMde_D_Actl : 3|2@0+ (1,0) [0|0] "" Vector__XXX
 SG_ Illum_PowerControlStatus : 4|1@0+ (1,0) [0|0] "" Vector__XXX
 SG_ AudioMute_B_Actl : 5|1@0+ (1,0) [0|0] "" Vector__XXX
 SG_ RoomFuseStat_D_Actl : 7|2@0+ (1,0) [0|0] "" Vector__XXX

BO_ 154 BCM_Information1: 8 CGW
 SG_ BCMINFO1_No_Cs : 63|8@0+ (1,0) [0|255] ""  RCM
 SG_ BCMINFO1_No_Cnt : 51|4@0+ (1,0) [0|15] ""  RCM
 SG_ SndRSP_Fail_B_Actl : 54|1@0+ (1,0) [0|0] "" Vector__XXX
 SG_ SndFSP_Fail_B_Actl : 55|1@0+ (1,0) [0|0] "" Vector__XXX
 SG_ Hazard_lamp_State_D_Actl : 43|1@0+ (1,0) [0|0] "" Vector__XXX
 SG_ DRL_Tail_Lamp_B_Rq : 44|1@0+ (1,0) [0|0] "" Vector__XXX
 SG_ TNS_Buzzer_Cntl_Req : 45|1@0+ (1,0) [0|0] "" Vector__XXX
 SG_ Turn_Snd_Cmd_Left : 46|1@0+ (1,0) [0|0] "" Vector__XXX
 SG_ Turn_Snd_Cmd_Right : 47|1@0+ (1,0) [0|0] "" Vector__XXX
 SG_ WiprGuid_B_Rq : 32|1@0+ (1,0) [0|0] "" Vector__XXX
 SG_ BurglarHorn_B_Req : 33|1@0+ (1,0) [0|0] "" Vector__XXX
 SG_ RSRmid_Indicator_Req : 35|2@0+ (1,0) [0|0] "" Vector__XXX
 SG_ RSRmid_DisplayReq : 37|2@0+ (1,0) [0|0] "" Vector__XXX
 SG_ BlwCont_B_Actl : 38|1@0+ (1,0) [0|0] "" Vector__XXX
 SG_ FrntWipr_D_Actl : 24|2@0+ (1,0) [0|0] "" Vector__XXX
 SG_ SteeringHeatCutLvl : 26|2@0+ (1,0) [0|0] "" Vector__XXX
 SG_ PtcCutLvl : 28|2@0+ (1,0) [0|0] "" Vector__XXX
 SG_ BmotCutLvl : 30|2@0+ (1,0) [0|0] "" Vector__XXX
 SG_ SeatHeatCutLvl : 16|2@0+ (1,0) [0|0] "" Vector__XXX
 SG_ RdefCutLvl : 18|2@0+ (1,0) [0|0] "" Vector__XXX
 SG_ SeatVentCutLvl : 20|2@0+ (1,0) [0|0] "" Vector__XXX
 SG_ WshrLvl_D_Actl : 22|2@0+ (1,0) [0|0] "" Vector__XXX
 SG_ TNS_IpcDsply_D_Rq : 8|2@0+ (1,0) [0|0] "" Vector__XXX
 SG_ Turn_Ind_Cmd_Left : 9|1@0+ (1,0) [0|0] "" Vector__XXX
 SG_ Turn_Ind_Cmd_Right : 10|1@0+ (1,0) [0|0] "" Vector__XXX
 SG_ Turnlamp_ESS_B_Req : 11|1@0+ (1,0) [0|0] "" Vector__XXX
 SG_ Turnlamp_KoDo_B_Req : 12|1@0+ (1,0) [0|0] "" Vector__XXX
 SG_ LightWarning_D_Rq : 15|3@0+ (1,0) [0|0] "" Vector__XXX
 SG_ ResHeatCont_B_Actl : 0|1@0+ (1,0) [0|0] "" Vector__XXX
 SG_ ResEngCont_B_Actl : 1|1@0+ (1,0) [0|0] "" Vector__XXX
 SG_ CBDA_Sleep_B_Rq : 2|1@0+ (1,0) [0|0] "" Vector__XXX
 SG_ RearWiprLo_B_Rq : 4|2@0+ (1,0) [0|0] "" Vector__XXX
 SG_ AutoWiprIND_B_Rq : 5|1@0+ (1,0) [0|0] "" Vector__XXX
 SG_ RearFogIpcDsply_B_Rq : 6|1@0+ (1,0) [0|0] "" Vector__XXX
 SG_ HiBeamIpcDsply_B_Rq : 7|1@0+ (1,0) [0|0] "" Vector__XXX

BO_ 152 WheelData_2_MAC: 8 DSC
 SG_ WheelData_2_MACTx : 35|28@0+ (1,0) [0|268435455] ""  CGW,RCM
 SG_ WheelData_2_FVTx : 39|4@0+ (1,0) [0|15] ""  CGW,RCM
 SG_ VehVActlBrk_No_Cs : 31|8@0+ (1,0) [0|255] ""  CGW
 SG_ VehVActlBrk_No_Cnt : 19|4@0+ (1,0) [0|15] ""  CGW
 SG_ Vehicle_Stationary : 21|2@0+ (1,0) [0|0] ""  CGW
 SG_ VehVActlBrk_D_Qf : 23|2@0+ (1,0) [0|0] ""  CGW,RCM,EPAS
 SG_ Veh_V_ActlBrk : 7|16@0+ (0.01,0) [0|655.35] "kph"  CGW,RCM,EPAS

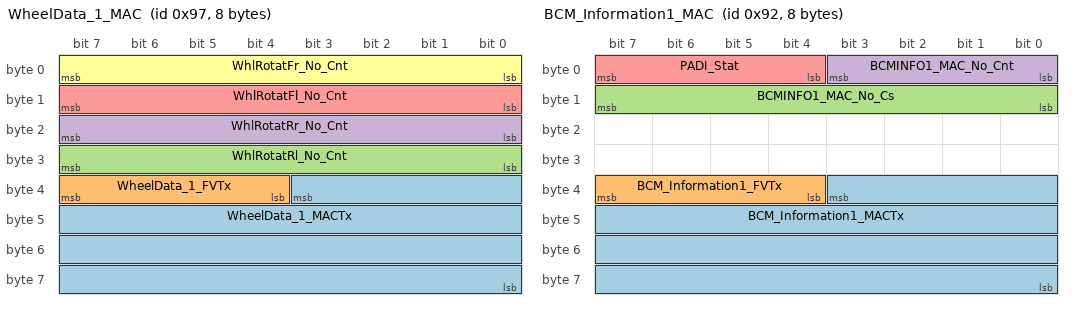
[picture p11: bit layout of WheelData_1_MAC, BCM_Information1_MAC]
BO_ 151 WheelData_1_MAC: 8 DSC
 SG_ WheelData_1_MACTx : 35|28@0+ (1,0) [0|268435455] ""  CGW
 SG_ WheelData_1_FVTx : 39|4@0+ (1,0) [0|15] ""  CGW
 SG_ WhlRotatRl_No_Cnt : 31|8@0+ (1,0) [0|255] ""  CGW
 SG_ WhlRotatRr_No_Cnt : 23|8@0+ (1,0) [0|255] ""  CGW
 SG_ WhlRotatFl_No_Cnt : 15|8@0+ (1,0) [0|255] ""  CGW
 SG_ WhlRotatFr_No_Cnt : 7|8@0+ (1,0) [0|255] ""  CGW

BO_ 150 Cruise_Multi_Switch_2_MAC: 8 CGW
 SG_ Cruise_Multi_Switch_2_MACTx : 35|28@0+ (1,0) [0|268435455] ""  DSC
 SG_ Cruise_Multi_Switch_2_FVTx : 39|4@0+ (1,0) [0|15] ""  DSC
 SG_ HECSwtchB_2_Cs : 31|8@0+ (1,0) [0|255] "" Vector__XXX
 SG_ HECSwtchB_2_Cnt : 19|4@0+ (1,0) [0|15] "" Vector__XXX
 SG_ FuelLidOpen_Rq_SW_B_Actl : 20|1@0+ (1,0) [0|0] "" Vector__XXX
 SG_ TmpLoAlrmB_Actl : 21|1@0+ (1,0) [0|0] "" Vector__XXX
 SG_ HEC_HUD_Disp_MRCC_Status : 22|1@0+ (1,0) [0|0] "" Vector__XXX
 SG_ HEC_HUD_Disp_MRCC_Status2 : 23|1@0+ (1,0) [0|0] "" Vector__XXX
 SG_ SP_DATE_No : 11|4@0+ (1,0) [0|0] "" Vector__XXX
 SG_ PsunOfSw_B_Actl : 12|1@0+ (1,0) [0|0] "" Vector__XXX
 SG_ DposDrv2_B_Actl : 13|1@0+ (1,0) [0|0] "" Vector__XXX
 SG_ DposDrv1_B_Actl : 14|1@0+ (1,0) [0|0] "" Vector__XXX
 SG_ DposSet_B_Actl : 15|1@0+ (1,0) [0|0] "" Vector__XXX
 SG_ TLO_PLG_Sw_B_Actl : 0|1@0+ (1,0) [0|0] "" Vector__XXX
 SG_ IStpRexSw_B_Actl : 1|1@0+ (1,0) [0|0] "" Vector__XXX
 SG_ DSCOfSw_B_Actl : 2|1@0+ (1,0) [0|0] ""  DSC
 SG_ PSM_OfSw_B_Actl : 3|1@0+ (1,0) [0|0] "" Vector__XXX
 SG_ TVMOfSw_B_Actl : 4|1@0+ (1,0) [0|0] "" Vector__XXX
 SG_ ADASOfSw_B_Actl : 5|1@0+ (1,0) [0|0] "" Vector__XXX
 SG_ MultiSw_D_Qf : 7|2@0+ (1,0) [0|0] "" Vector__XXX

BO_ 148 Cruise_Multi_Switch_1_MAC: 8 CGW
 SG_ Cruise_Multi_Switch_1_MACTx : 35|28@0+ (1,0) [0|268435455] ""  RCM
 SG_ Cruise_Multi_Switch_1_FVTx : 39|4@0+ (1,0) [0|15] ""  RCM
 SG_ HECSwtchB_1_Cs : 31|8@0+ (1,0) [0|255] ""  RCM
 SG_ HECSwtchB_1_Cnt : 19|4@0+ (1,0) [0|15] ""  RCM
 SG_ DHS_RIL_STAT : 22|3@0+ (1,0) [0|0] ""  RCM
 SG_ RIL_STAT : 9|3@0+ (1,0) [0|0] ""  RCM
 SG_ MntSet_Oil_HEC_Req : 10|1@0+ (1,0) [0|0] "" Vector__XXX
 SG_ TJA_Swtch_B_Actl : 11|1@0+ (1,0) [0|0] "" Vector__XXX
 SG_ LIM_Swtch_B_Actl : 12|1@0+ (1,0) [0|0] "" Vector__XXX
 SG_ MRCC_Swtch_B_Actl : 13|1@0+ (1,0) [0|0] "" Vector__XXX
 SG_ ASC_Swtch_B_Actl : 14|1@0+ (1,0) [0|0] "" Vector__XXX
 SG_ DistanceMinus_B_Actl : 15|1@0+ (1,0) [0|0] "" Vector__XXX
 SG_ DistancePlus_B_Actl : 0|1@0+ (1,0) [0|0] "" Vector__XXX
 SG_ OffSwtch_B_Actl : 1|1@0+ (1,0) [0|0] "" Vector__XXX
 SG_ ResumeSwtch_B_Actl : 2|1@0+ (1,0) [0|0] "" Vector__XXX
 SG_ SetMinusSwtch_B_Actl : 3|1@0+ (1,0) [0|0] "" Vector__XXX
 SG_ SetPlusSwtch_B_Actl : 4|1@0+ (1,0) [0|0] "" Vector__XXX
 SG_ CancelSwtch_B_Actl : 5|1@0+ (1,0) [0|0] "" Vector__XXX
 SG_ CruiseSwtch_Qf : 7|2@0+ (1,0) [0|0] "" Vector__XXX

BO_ 146 BCM_Information1_MAC: 8 CGW
 SG_ BCM_Information1_MACTx : 35|28@0+ (1,0) [0|268435455] ""  RCM
 SG_ BCM_Information1_FVTx : 39|4@0+ (1,0) [0|15] ""  RCM
 SG_ BCMINFO1_MAC_No_Cs : 15|8@0+ (1,0) [0|255] ""  RCM
 SG_ BCMINFO1_MAC_No_Cnt : 3|4@0+ (1,0) [0|15] ""  RCM
 SG_ PADI_Stat : 7|4@0+ (1,0) [0|0] ""  RCM

BO_ 145 Steering_Column_Switch: 8 CGW
 SG_ HECSwtchA_Cs : 63|8@0+ (1,0) [0|255] "" Vector__XXX
 SG_ HECSwtchA_Cnt : 51|4@0+ (1,0) [0|15] "" Vector__XXX
 SG_ AEB_HEC_Fail_Flag : 52|1@0+ (1,0) [0|0] "" Vector__XXX
 SG_ Info_Status_B_Actl : 53|1@0+ (1,0) [0|0] "" Vector__XXX
 SG_ WiprTestMode_B_Actl : 54|1@0+ (1,0) [0|0] "" Vector__XXX
 SG_ SpAlarm_B_Actl : 55|1@0+ (1,0) [0|0] "" Vector__XXX
 SG_ FrntWiprInt_V_Actl : 47|8@0+ (1,0) [0|100] "Percent" Vector__XXX
 SG_ PanelCont_D_Actl : 33|2@0+ (1,0) [0|0] "" Vector__XXX
 SG_ AvgFuelEco_Rst_HEC : 34|1@0+ (1,0) [0|0] "" Vector__XXX
 SG_ Veh_speed : 27|9@0+ (1,0) [0|511] "" Vector__XXX
 SG_ PaddleShiftDwn_D_Actl : 29|2@0+ (1,0) [0|0] "" Vector__XXX
 SG_ PaddleShiftUp_D_Actl : 31|2@0+ (1,0) [0|0] "" Vector__XXX
 SG_ RearWasherSw_B_Actl : 16|1@0+ (1,0) [0|0] "" Vector__XXX
 SG_ FrntWasherSw_B_Actl : 17|1@0+ (1,0) [0|0] "" Vector__XXX
 SG_ RearWiprStats_D_Actl : 19|2@0+ (1,0) [0|0] "" Vector__XXX
 SG_ FrntWiprStats_D_Actl : 21|2@0+ (1,0) [0|0] "" Vector__XXX
 SG_ WiprSw_D_Qf : 23|2@0+ (1,0) [0|0] "" Vector__XXX
 SG_ Veh_speed_Fault : 8|1@0+ (1,0) [0|0] "" Vector__XXX
 SG_ ALH_HBC_Sw_B_Actl : 9|1@0+ (1,0) [0|0] "" Vector__XXX
 SG_ Veh_speed_Unit : 10|1@0+ (1,0) [0|0] "" Vector__XXX
 SG_ Mfs_Turn_Stalk_SW_Status : 13|2@0+ (1,0) [0|0] ""  RCM
 SG_ HeadLghtOffSw_B_Actl : 14|1@0+ (1,0) [0|0] "" Vector__XXX
 SG_ PassngSw_B_Actl : 15|1@0+ (1,0) [0|0] "" Vector__XXX
 SG_ RearFogSw_B_Actl : 0|1@0+ (1,0) [0|0] "" Vector__XXX
 SG_ RSRmid_TmpOffReq : 2|1@0+ (1,0) [0|0] "" Vector__XXX
 SG_ HeadLghtHiSw_B_Actl : 3|1@0+ (1,0) [0|0] "" Vector__XXX
 SG_ HeadLghtLoSw_B_Actl : 4|1@0+ (1,0) [0|0] "" Vector__XXX
 SG_ TnsSw_B_Actl : 5|1@0+ (1,0) [0|0] "" Vector__XXX
 SG_ LghtSw_D_Qf : 7|2@0+ (1,0) [0|0] ""  RCM

BO_ 137 YAW_Rate_Brake_Control_3_2: 8 DSC
 SG_ YAW_Rate_Brake_Control32_No_Cs : 63|8@0+ (1,0) [0|255] ""  CGW
 SG_ YAW_Rate_Brake_Control32_No_Cnt : 51|4@0+ (1,0) [0|15] ""  CGW
 SG_ HydraulicHold_TrqReqire : 46|1@0+ (1,0) [0|0] ""  CGW
 SG_ Abs_B_Falt_Echo : 47|1@0+ (1,0) [0|0] ""  CGW
 SG_ TsaCtlActv_B_Actl_Echo : 32|1@0+ (1,0) [0|0] ""  CGW
 SG_ RolStabCtlActv_B_Actl_Echo : 33|1@0+ (1,0) [0|0] ""  CGW
 SG_ PrplDrgCtlActv_B_Actl_Echo : 34|1@0+ (1,0) [0|0] ""  CGW
 SG_ TracCtlPtActv_B_Actl_Echo : 35|1@0+ (1,0) [0|0] ""  CGW
 SG_ TracCtlBrkActv_B_Actl_Echo : 36|1@0+ (1,0) [0|0] ""  CGW
 SG_ DSC_OnOff_status_1_Echo : 37|1@0+ (1,0) [0|0] ""  CGW
 SG_ StabCtlBrkActv_B_Actl_Echo : 38|1@0+ (1,0) [0|0] ""  CGW
 SG_ BrkAsst_B_Actl_Echo : 39|1@0+ (1,0) [0|0] ""  CGW
 SG_ AbsActv_B_Actl_Echo : 24|1@0+ (1,0) [0|0] ""  CGW
 SG_ EbdActv_B_Actl_Echo : 25|1@0+ (1,0) [0|0] ""  CGW
 SG_ VehVActlBrk_D_Qf_Echo : 27|2@0+ (1,0) [0|0] ""  CGW
 SG_ Veh_V_ActlBrk_Echo : 11|16@0+ (0.01,0) [0|655.35] "kph"  CGW
 SG_ VehYawComp_W_Actl_2_Echo : 7|12@0+ (0.03663,-74.98161) [-74.98161|75.01824] "degrees/second"  CGW

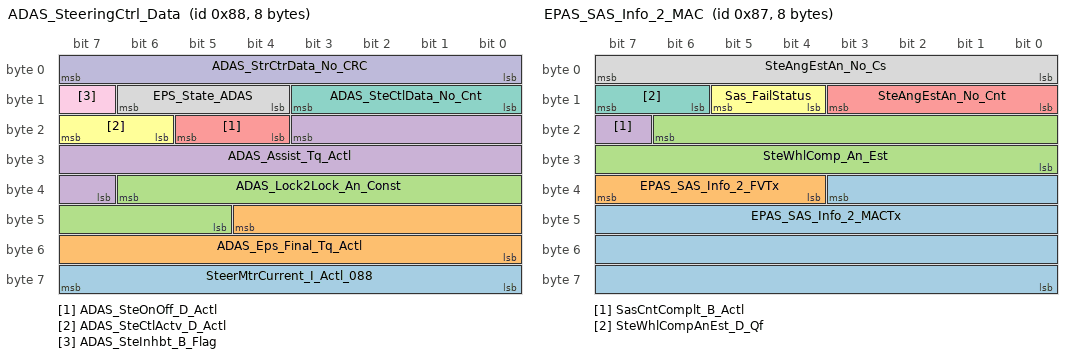
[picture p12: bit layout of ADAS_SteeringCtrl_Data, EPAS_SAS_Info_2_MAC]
BO_ 136 ADAS_SteeringCtrl_Data: 8 EPAS
 SG_ SteerMtrCurrent_I_Actl_088 : 63|8@0+ (1,-127) [-127|127] "Ampere"  CGW
 SG_ ADAS_Eps_Final_Tq_Actl : 44|13@0+ (0.05,-204.75) [-204.75|204.75] "Nm"  CGW
 SG_ ADAS_Lock2Lock_An_Const : 38|10@0+ (1,0) [0|1023] "Angle"  CGW
 SG_ ADAS_Assist_Tq_Actl : 19|13@0+ (0.05,-204.75) [-204.75|204.75] "Nm"  CGW
 SG_ ADAS_SteOnOff_D_Actl : 21|2@0+ (1,0) [0|0] ""  CGW
 SG_ ADAS_SteCtlActv_D_Actl : 23|2@0+ (1,0) [0|0] ""  CGW
 SG_ ADAS_SteCtlData_No_Cnt : 11|4@0+ (1,0) [0|15] ""  CGW
 SG_ EPS_State_ADAS : 14|3@0+ (1,0) [0|0] ""  CGW
 SG_ ADAS_SteInhbt_B_Flag : 15|1@0+ (1,0) [0|0] ""  CGW
 SG_ ADAS_StrCtrData_No_CRC : 7|8@0+ (1,0) [0|255] ""  CGW

BO_ 135 EPAS_SAS_Info_2_MAC: 8 EPAS
 SG_ EPAS_SAS_Info_2_MACTx : 35|28@0+ (1,0) [0|268435455] ""  CGW,RCM
 SG_ EPAS_SAS_Info_2_FVTx : 39|4@0+ (1,0) [0|15] ""  CGW,RCM
 SG_ SteWhlComp_An_Est : 22|15@0+ (0.1,-1600) [-1600|1676.7] "deg"  CGW,RCM
 SG_ SasCntComplt_B_Actl : 23|1@0+ (1,0) [0|0] ""  CGW
 SG_ SteAngEstAn_No_Cnt : 11|4@0+ (1,0) [0|15] ""  CGW
 SG_ Sas_FailStatus : 13|2@0+ (1,0) [0|0] ""  CGW
 SG_ SteWhlCompAnEst_D_Qf : 15|2@0+ (1,0) [0|0] ""  CGW,RCM
 SG_ SteAngEstAn_No_Cs : 7|8@0+ (1,0) [0|255] ""  CGW

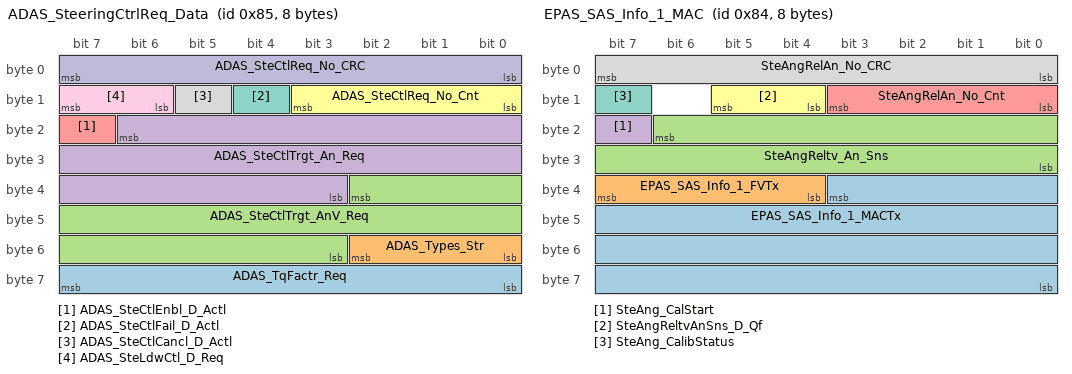
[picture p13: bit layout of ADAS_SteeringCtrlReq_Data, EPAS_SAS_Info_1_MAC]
BO_ 133 ADAS_SteeringCtrlReq_Data: 8 CGW
 SG_ ADAS_TqFactr_Req : 63|8@0+ (0.005,0) [0|1] ""  EPAS
 SG_ ADAS_Types_Str : 50|3@0+ (1,0) [0|0] ""  EPAS
 SG_ ADAS_SteCtlTrgt_AnV_Req : 34|16@0+ (0.06104,-2000.09768) [-2000.09768|2000.09768] "deg/s"  EPAS
 SG_ ADAS_SteCtlTrgt_An_Req : 22|20@0+ (0.0015,-786.4305) [-720|720] "deg"  EPAS
 SG_ ADAS_SteCtlEnbl_D_Actl : 23|1@0+ (1,0) [0|0] ""  EPAS
 SG_ ADAS_SteCtlReq_No_Cnt : 11|4@0+ (1,0) [0|15] ""  EPAS
 SG_ ADAS_SteCtlFail_D_Actl : 12|1@0+ (1,0) [0|0] ""  EPAS
 SG_ ADAS_SteCtlCancl_D_Actl : 13|1@0+ (1,0) [0|0] ""  EPAS
 SG_ ADAS_SteLdwCtl_D_Req : 15|2@0+ (1,0) [0|0] ""  EPAS
 SG_ ADAS_SteCtlReq_No_CRC : 7|8@0+ (1,0) [0|255] ""  EPAS

BO_ 132 EPAS_SAS_Info_1_MAC: 8 EPAS
 SG_ EPAS_SAS_Info_1_MACTx : 35|28@0+ (1,0) [0|268435455] ""  CGW,DSC
 SG_ EPAS_SAS_Info_1_FVTx : 39|4@0+ (1,0) [0|15] ""  CGW,DSC
 SG_ SteAngReltv_An_Sns : 22|15@0+ (0.1,-1600) [-1600|1676.7] "deg"  CGW,DSC
 SG_ SteAng_CalStart : 23|1@0+ (1,0) [0|0] ""  CGW,DSC
 SG_ SteAngRelAn_No_Cnt : 11|4@0+ (1,0) [0|15] ""  CGW,DSC
 SG_ SteAngReltvAnSns_D_Qf : 13|2@0+ (1,0) [0|0] ""  CGW,DSC
 SG_ SteAng_CalibStatus : 15|1@0+ (1,0) [0|0] ""  CGW,DSC
 SG_ SteAngRelAn_No_CRC : 7|8@0+ (1,0) [0|255] ""  CGW,DSC

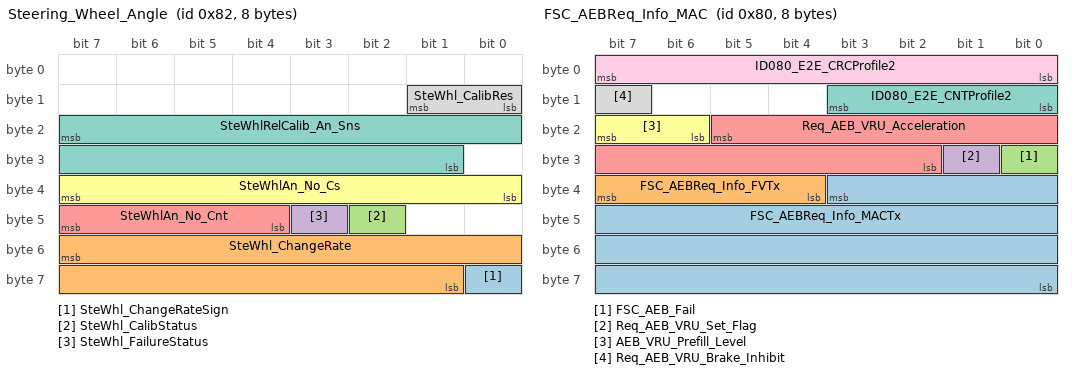
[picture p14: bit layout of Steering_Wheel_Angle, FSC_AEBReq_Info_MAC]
BO_ 130 Steering_Wheel_Angle: 8 CGW
 SG_ SteWhl_ChangeRateSign : 56|1@0+ (1,0) [0|0] "" Vector__XXX
 SG_ SteWhl_ChangeRate : 55|15@0+ (0.06104,0) [0|1999.9756] "deg/s" Vector__XXX
 SG_ SteWhl_CalibStatus : 42|1@0+ (1,0) [0|0] "" Vector__XXX
 SG_ SteWhl_FailureStatus : 43|1@0+ (1,0) [0|0] ""  EPAS
 SG_ SteWhlAn_No_Cnt : 47|4@0+ (1,0) [0|15] "Counts"  EPAS
 SG_ SteWhlAn_No_Cs : 39|8@0+ (1,0) [0|255] ""  EPAS
 SG_ SteWhlRelCalib_An_Sns : 23|15@0+ (0.1,-1600) [-1600|1676.7] "Deg"  EPAS
 SG_ SteWhl_CalibRes : 9|2@0+ (1,0) [0|0] "" Vector__XXX

BO_ 128 FSC_AEBReq_Info_MAC: 8 FSC
 SG_ FSC_AEBReq_Info_MACTx : 35|28@0+ (1,0) [0|268435455] ""  DSC,RCM
 SG_ FSC_AEBReq_Info_FVTx : 39|4@0+ (1,0) [0|15] ""  DSC,RCM
 SG_ FSC_AEB_Fail : 24|1@0+ (1,0) [0|0] ""  DSC
 SG_ Req_AEB_VRU_Set_Flag : 25|1@0+ (1,0) [0|0] ""  DSC
 SG_ Req_AEB_VRU_Acceleration : 21|12@0+ (0.005,-10) [-10|10] "m/sec2"  DSC,RCM
 SG_ AEB_VRU_Prefill_Level : 23|2@0+ (1,0) [0|0] ""  DSC
 SG_ ID080_E2E_CNTProfile2 : 11|4@0+ (1,0) [0|15] ""  DSC
 SG_ Req_AEB_VRU_Brake_Inhibit : 15|1@0+ (1,0) [0|0] ""  DSC
 SG_ ID080_E2E_CRCProfile2 : 7|8@0+ (1,0) [0|255] "" Vector__XXX

BO_ 127 FSC_AEBHmi_Info: 8 FSC
 SG_ FSC_AEBHmi_Info_No_Cs : 63|8@0+ (1,0) [0|255] ""  CGW
 SG_ FSC_AEBHmi_Info_No_Cnt : 51|4@0+ (1,0) [0|15] ""  CGW
 SG_ AEB_VRU_state : 23|4@0+ (1,0) [0|0] ""  CGW,RCM

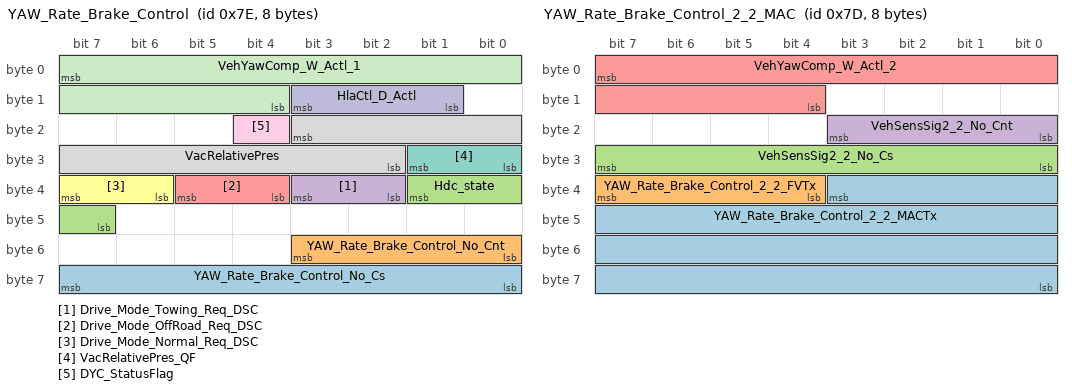
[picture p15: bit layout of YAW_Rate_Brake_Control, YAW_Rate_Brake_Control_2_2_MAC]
BO_ 126 YAW_Rate_Brake_Control: 8 DSC
 SG_ YAW_Rate_Brake_Control_No_Cs : 63|8@0+ (1,0) [0|255] ""  CGW
 SG_ YAW_Rate_Brake_Control_No_Cnt : 51|4@0+ (1,0) [0|15] ""  CGW
 SG_ Hdc_state : 33|3@0+ (1,0) [0|0] ""  CGW
 SG_ Drive_Mode_Towing_Req_DSC : 35|2@0+ (1,0) [0|0] ""  CGW
 SG_ Drive_Mode_OffRoad_Req_DSC : 37|2@0+ (1,0) [0|0] ""  CGW
 SG_ Drive_Mode_Normal_Req_DSC : 39|2@0+ (1,0) [0|0] ""  CGW
 SG_ VacRelativePres_QF : 25|2@0+ (1,0) [0|0] ""  CGW
 SG_ VacRelativePres : 19|10@0+ (0.1,-100) [-100|2.3] "Kpa"  CGW
 SG_ DYC_StatusFlag : 20|1@0+ (1,0) [0|0] ""  CGW
 SG_ HlaCtl_D_Actl : 11|3@0+ (1,0) [0|0] ""  CGW
 SG_ VehYawComp_W_Actl_1 : 7|12@0+ (0.03663,-74.98161) [-74.98161|75.01824] "degrees/second"  CGW

BO_ 125 YAW_Rate_Brake_Control_2_2_MAC: 8 DSC
 SG_ YAW_Rate_Brake_Control_2_2_MACTx : 35|28@0+ (1,0) [0|268435455] ""  CGW
 SG_ YAW_Rate_Brake_Control_2_2_FVTx : 39|4@0+ (1,0) [0|15] ""  CGW
 SG_ VehSensSig2_2_No_Cs : 31|8@0+ (1,0) [0|255] ""  CGW
 SG_ VehSensSig2_2_No_Cnt : 19|4@0+ (1,0) [0|15] ""  CGW
 SG_ VehYawComp_W_Actl_2 : 7|12@0+ (0.03663,-74.98161) [-74.98161|75.01824] "degrees/second"  CGW,EPAS

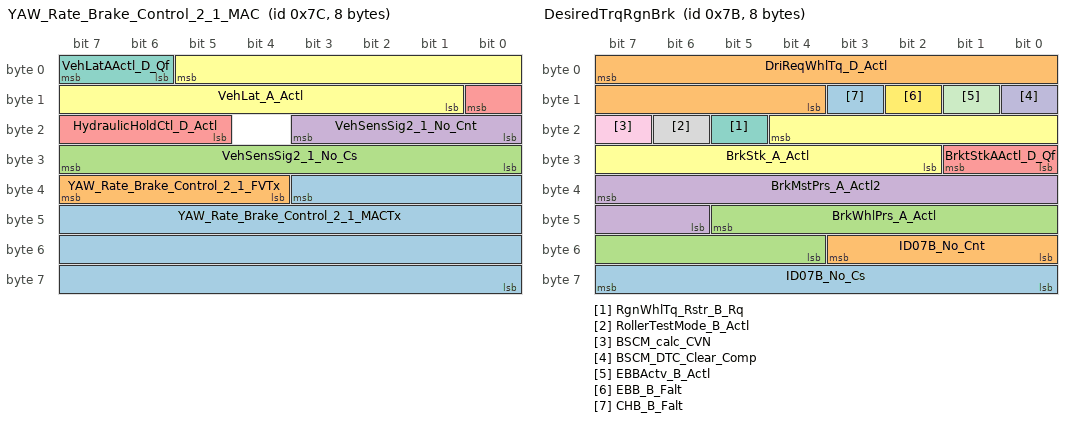
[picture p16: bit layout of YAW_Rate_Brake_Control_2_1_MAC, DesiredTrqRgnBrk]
BO_ 124 YAW_Rate_Brake_Control_2_1_MAC: 8 DSC
 SG_ YAW_Rate_Brake_Control_2_1_MACTx : 35|28@0+ (1,0) [0|268435455] ""  CGW
 SG_ YAW_Rate_Brake_Control_2_1_FVTx : 39|4@0+ (1,0) [0|15] ""  CGW
 SG_ VehSensSig2_1_No_Cs : 31|8@0+ (1,0) [0|255] ""  CGW
 SG_ VehSensSig2_1_No_Cnt : 19|4@0+ (1,0) [0|15] ""  CGW
 SG_ HydraulicHoldCtl_D_Actl : 8|4@0+ (1,0) [0|0] ""  CGW
 SG_ VehLat_A_Actl : 5|13@0+ (0.01,-40) [-40|41.91] "m/s^2"  CGW,EPAS
 SG_ VehLatAActl_D_Qf : 7|2@0+ (1,0) [0|0] ""  CGW,EPAS

BO_ 123 DesiredTrqRgnBrk: 8 DSC
 SG_ ID07B_No_Cs : 63|8@0+ (1,0) [0|255] ""  CGW
 SG_ ID07B_No_Cnt : 51|4@0+ (1,0) [0|15] ""  CGW
 SG_ BrkWhlPrs_A_Actl : 45|10@0+ (0.032768,-5) [-5|19.969216] "Mpa"  CGW
 SG_ BrkMstPrs_A_Actl2 : 39|10@0+ (0.032768,-5) [-5|19.969216] "Mpa"  CGW
 SG_ BrktStkAActl_D_Qf : 25|2@0+ (1,0) [0|0] ""  CGW
 SG_ BrkStk_A_Actl : 20|11@0+ (0.05,-20) [-20|82.35] "mm"  CGW
 SG_ RgnWhlTq_Rstr_B_Rq : 21|1@0+ (1,0) [0|0] ""  CGW
 SG_ RollerTestMode_B_Actl : 22|1@0+ (1,0) [0|0] ""  CGW
 SG_ BSCM_calc_CVN : 23|1@0+ (1,0) [0|0] ""  CGW
 SG_ BSCM_DTC_Clear_Comp : 8|1@0+ (1,0) [0|0] ""  CGW
 SG_ EBBActv_B_Actl : 9|1@0+ (1,0) [0|0] ""  CGW
 SG_ EBB_B_Falt : 10|1@0+ (1,0) [0|0] ""  CGW
 SG_ CHB_B_Falt : 11|1@0+ (1,0) [0|0] ""  CGW
 SG_ DriReqWhlTq_D_Actl : 7|12@0+ (1,-4000) [-4000|0] "Nm"  CGW

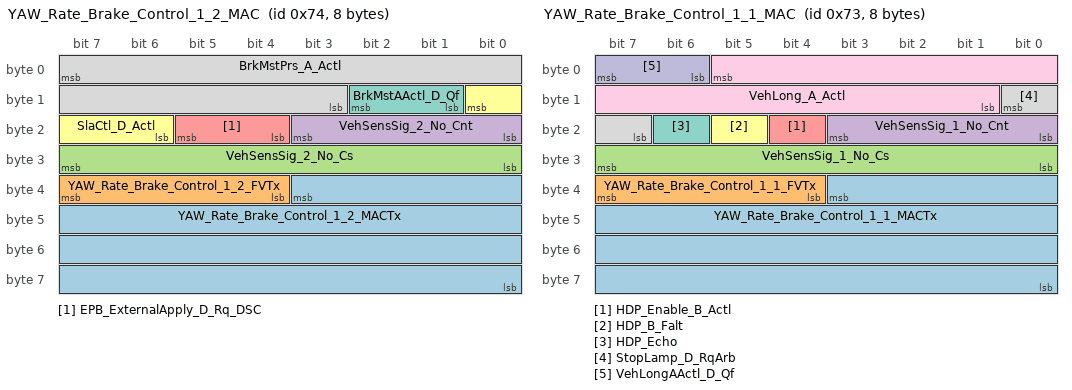
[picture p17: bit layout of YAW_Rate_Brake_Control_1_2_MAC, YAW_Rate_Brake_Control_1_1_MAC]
BO_ 116 YAW_Rate_Brake_Control_1_2_MAC: 8 DSC
 SG_ YAW_Rate_Brake_Control_1_2_MACTx : 35|28@0+ (1,0) [0|268435455] ""  CGW
 SG_ YAW_Rate_Brake_Control_1_2_FVTx : 39|4@0+ (1,0) [0|15] ""  CGW
 SG_ VehSensSig_2_No_Cs : 31|8@0+ (1,0) [0|255] ""  CGW
 SG_ VehSensSig_2_No_Cnt : 19|4@0+ (1,0) [0|15] ""  CGW
 SG_ EPB_ExternalApply_D_Rq_DSC : 21|2@0+ (1,0) [0|0] ""  CGW
 SG_ SlaCtl_D_Actl : 8|3@0+ (1,0) [0|0] ""  CGW
 SG_ BrkMstAActl_D_Qf : 10|2@0+ (1,0) [0|0] ""  CGW
 SG_ BrkMstPrs_A_Actl : 7|13@0+ (0.032768,-5) [-5|19.969216] "MPa"  CGW

BO_ 115 YAW_Rate_Brake_Control_1_1_MAC: 8 DSC
 SG_ YAW_Rate_Brake_Control_1_1_MACTx : 35|28@0+ (1,0) [0|268435455] ""  CGW
 SG_ YAW_Rate_Brake_Control_1_1_FVTx : 39|4@0+ (1,0) [0|15] ""  CGW
 SG_ VehSensSig_1_No_Cs : 31|8@0+ (1,0) [0|255] ""  CGW
 SG_ VehSensSig_1_No_Cnt : 19|4@0+ (1,0) [0|15] ""  CGW
 SG_ HDP_Enable_B_Actl : 20|1@0+ (1,0) [0|0] ""  CGW
 SG_ HDP_B_Falt : 21|1@0+ (1,0) [0|0] ""  CGW
 SG_ HDP_Echo : 22|1@0+ (1,0) [0|0] ""  CGW
 SG_ StopLamp_D_RqArb : 8|2@0+ (1,0) [0|0] ""  CGW
 SG_ VehLong_A_Actl : 5|13@0+ (0.01,-40) [-40|41.91] "m/s^2"  CGW
 SG_ VehLongAActl_D_Qf : 7|2@0+ (1,0) [0|0] ""  CGW

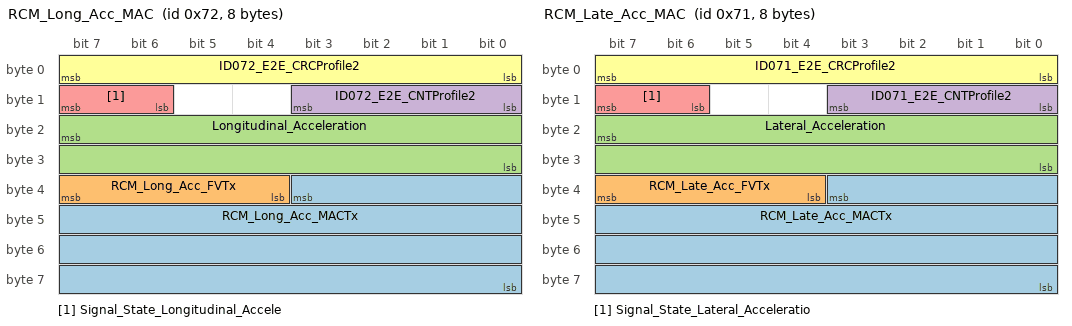
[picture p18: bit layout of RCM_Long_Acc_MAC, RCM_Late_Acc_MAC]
BO_ 114 RCM_Long_Acc_MAC: 8 RCM
 SG_ RCM_Long_Acc_MACTx : 35|28@0+ (1,0) [0|268435455] ""  CGW,DSC
 SG_ RCM_Long_Acc_FVTx : 39|4@0+ (1,0) [0|15] ""  CGW,DSC
 SG_ Longitudinal_Acceleration : 23|16@0+ (0.001,-2) [-2|2] "g"  CGW,DSC
 SG_ ID072_E2E_CNTProfile2 : 11|4@0+ (1,0) [0|15] ""  CGW,DSC
 SG_ Signal_State_Longitudinal_Accele : 15|2@0+ (1,0) [0|0] ""  CGW,DSC
 SG_ ID072_E2E_CRCProfile2 : 7|8@0+ (1,0) [0|255] ""  CGW,DSC

BO_ 113 RCM_Late_Acc_MAC: 8 RCM
 SG_ RCM_Late_Acc_MACTx : 35|28@0+ (1,0) [0|268435455] ""  CGW,DSC
 SG_ RCM_Late_Acc_FVTx : 39|4@0+ (1,0) [0|15] ""  CGW,DSC
 SG_ Lateral_Acceleration : 23|16@0+ (0.001,-2) [-2|2] "g"  CGW,DSC
 SG_ ID071_E2E_CNTProfile2 : 11|4@0+ (1,0) [0|15] ""  CGW,DSC
 SG_ Signal_State_Lateral_Acceleratio : 15|2@0+ (1,0) [0|0] ""  CGW,DSC
 SG_ ID071_E2E_CRCProfile2 : 7|8@0+ (1,0) [0|255] ""  CGW,DSC

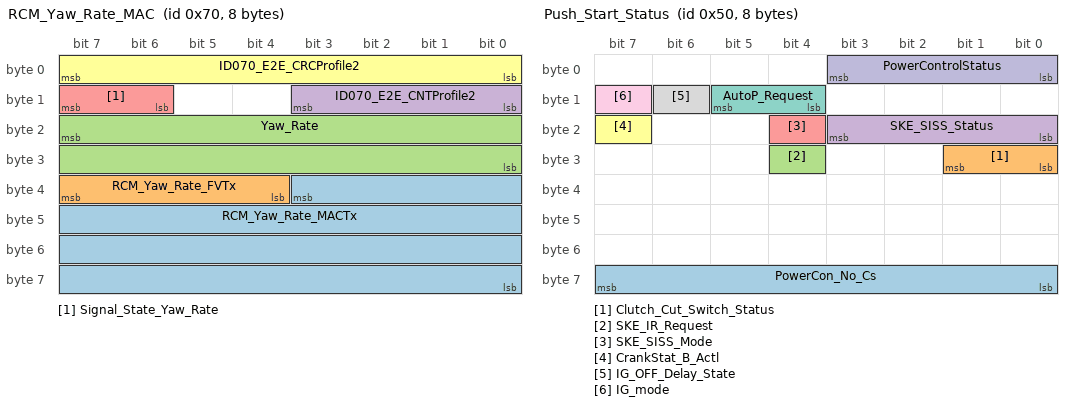
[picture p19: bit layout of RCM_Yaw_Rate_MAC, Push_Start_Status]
BO_ 112 RCM_Yaw_Rate_MAC: 8 RCM
 SG_ RCM_Yaw_Rate_MACTx : 35|28@0+ (1,0) [0|268435455] ""  CGW,DSC
 SG_ RCM_Yaw_Rate_FVTx : 39|4@0+ (1,0) [0|15] ""  CGW,DSC
 SG_ Yaw_Rate : 23|16@0+ (0.01,-180) [-180|180] "deg/sec"  CGW,DSC
 SG_ ID070_E2E_CNTProfile2 : 11|4@0+ (1,0) [0|15] ""  CGW,DSC
 SG_ Signal_State_Yaw_Rate : 15|2@0+ (1,0) [0|0] ""  CGW,DSC
 SG_ ID070_E2E_CRCProfile2 : 7|8@0+ (1,0) [0|255] ""  CGW,DSC

BO_ 80 Push_Start_Status: 8 CGW
 SG_ PowerCon_No_Cs : 63|8@0+ (1,0) [0|255] "" Vector__XXX
 SG_ Clutch_Cut_Switch_Status : 25|2@0+ (1,0) [0|0] "" Vector__XXX
 SG_ SKE_IR_Request : 28|1@0+ (1,0) [0|0] "" Vector__XXX
 SG_ SKE_SISS_Status : 19|4@0+ (1,0) [0|0] "" Vector__XXX
 SG_ SKE_SISS_Mode : 20|1@0+ (1,0) [0|0] "" Vector__XXX
 SG_ CrankStat_B_Actl : 23|1@0+ (1,0) [0|0] "" Vector__XXX
 SG_ AutoP_Request : 13|2@0+ (1,0) [0|0] ""  DSC
 SG_ IG_OFF_Delay_State : 14|1@0+ (1,0) [0|0] "" Vector__XXX
 SG_ IG_mode : 15|1@0+ (1,0) [0|0] "" Vector__XXX
 SG_ PowerControlStatus : 3|4@0+ (1,0) [0|0] ""  DSC,FSC

BO_ 74 RCMStatusMessage_2_MAC: 8 RCM
 SG_ RCMStatusMessage_2_MACTx : 35|28@0+ (1,0) [0|268435455] ""  CGW
 SG_ RCMStatusMessage_2_FVTx : 39|4@0+ (1,0) [0|15] ""  CGW
 SG_ threshold_over_fst : 7|2@0+ (1,0) [0|0] ""  CGW

BO_ 32 CGW_Sync: 8 CGW
 SG_ CGW_Sync_MACTx : 35|28@0+ (1,0) [0|268435455] ""  DSC,RCM,EPAS,FSC
 SG_ CGW_Sync_ResetCnt : 23|20@0+ (1,0) [0|1048575] ""  DSC,RCM,EPAS,FSC
 SG_ CGW_Sync_TripCnt : 7|16@0+ (1,0) [0|65535] ""  DSC,RCM,EPAS,FSC

BO_ 28 MACKVERI4: 8 CGW
 SG_ MACKVERI4_2 : 39|32@0+ (1,0) [0|4294967295] ""  DSC,RCM,EPAS,ECB,FSC
 SG_ MACKVERI4_1 : 7|32@0+ (1,0) [0|4294967295] ""  DSC,RCM,EPAS,ECB,FSC

BO_ 27 MACKVERI3: 8 CGW
 SG_ MACKVERI3_2 : 39|32@0+ (1,0) [0|4294967295] ""  DSC,RCM,EPAS,ECB,FSC
 SG_ MACKVERI3_1 : 7|32@0+ (1,0) [0|4294967295] ""  DSC,RCM,EPAS,ECB,FSC

BO_ 26 MACKVERI2: 8 CGW
 SG_ MACKVERI2_2 : 39|32@0+ (1,0) [0|4294967295] ""  DSC,RCM,EPAS,ECB,FSC
 SG_ MACKVERI2_1 : 7|32@0+ (1,0) [0|4294967295] ""  DSC,RCM,EPAS,ECB,FSC

BO_ 25 MACKVERI1: 8 CGW
 SG_ MACKVERI1_2 : 39|32@0+ (1,0) [0|4294967295] ""  DSC,RCM,EPAS,ECB,FSC
 SG_ MACKVERI1_1 : 7|32@0+ (1,0) [0|4294967295] ""  DSC,RCM,EPAS,ECB,FSC

BO_ 24 MACKID_MACKUSAGE: 8 CGW
 SG_ MACKUSAGE : 15|8@0+ (1,0) [0|255] ""  DSC,RCM,EPAS,ECB,FSC
 SG_ MACKID : 7|8@0+ (1,0) [0|255] ""  DSC,RCM,EPAS,ECB,FSC

BO_ 23 MACKSEND8: 8 CGW
 SG_ MACKSEND8_2 : 39|32@0+ (1,0) [0|4294967295] ""  DSC,RCM,EPAS,ECB,FSC
 SG_ MACKSEND8_1 : 7|32@0+ (1,0) [0|4294967295] ""  DSC,RCM,EPAS,ECB,FSC

BO_ 22 MACKSEND7: 8 CGW
 SG_ MACKSEND7_2 : 39|32@0+ (1,0) [0|4294967295] ""  DSC,RCM,EPAS,ECB,FSC
 SG_ MACKSEND7_1 : 7|32@0+ (1,0) [0|4294967295] ""  DSC,RCM,EPAS,ECB,FSC

BO_ 21 MACKSEND6: 8 CGW
 SG_ MACKSEND6_2 : 39|32@0+ (1,0) [0|4294967295] ""  DSC,RCM,EPAS,ECB,FSC
 SG_ MACKSEND6_1 : 7|32@0+ (1,0) [0|4294967295] ""  DSC,RCM,EPAS,ECB,FSC

BO_ 20 MACKSEND5: 8 CGW
 SG_ MACKSEND5_2 : 39|32@0+ (1,0) [0|4294967295] ""  DSC,RCM,EPAS,ECB,FSC
 SG_ MACKSEND5_1 : 7|32@0+ (1,0) [0|4294967295] ""  DSC,RCM,EPAS,ECB,FSC

BO_ 19 MACKSEND4: 8 CGW
 SG_ MACKSEND4_2 : 39|32@0+ (1,0) [0|4294967295] ""  DSC,RCM,EPAS,ECB,FSC
 SG_ MACKSEND4_1 : 7|32@0+ (1,0) [0|4294967295] ""  DSC,RCM,EPAS,ECB,FSC

BO_ 18 MACKSEND3: 8 CGW
 SG_ MACKSEND3_2 : 39|32@0+ (1,0) [0|4294967295] ""  DSC,RCM,EPAS,ECB,FSC
 SG_ MACKSEND3_1 : 7|32@0+ (1,0) [0|4294967295] ""  DSC,RCM,EPAS,ECB,FSC

BO_ 17 MACKSEND2: 8 CGW
 SG_ MACKSEND2_2 : 39|32@0+ (1,0) [0|4294967295] ""  DSC,RCM,EPAS,ECB,FSC
 SG_ MACKSEND2_1 : 7|32@0+ (1,0) [0|4294967295] ""  DSC,RCM,EPAS,ECB,FSC

BO_ 16 MACKSEND1: 8 CGW
 SG_ MACKSEND1_2 : 39|32@0+ (1,0) [0|4294967295] ""  DSC,RCM,EPAS,ECB,FSC
 SG_ MACKSEND1_1 : 7|32@0+ (1,0) [0|4294967295] ""  DSC,RCM,EPAS,ECB,FSC

BA_DEF_ BO_  "SCP_FreshnessValueTxLength" INT 0 512;
BA_DEF_ BO_  "SCP_FreshnessValueLength" INT 0 512;
BA_DEF_ BO_  "SCP_DataId" INT 0 65535;
BA_DEF_ BO_  "SCP_AuthInfoTxLength" INT 0 512;
BA_DEF_ BO_  "SC_Message" ENUM  "No","Yes";
BA_DEF_ BO_  "CANFD_BRS" ENUM  "0","1";
BA_DEF_ BO_  "VFrameFormat" ENUM  "StandardCAN","ExtendedCAN","reserved","reserved","reserved","reserved","reserved","reserved","reserved","reserved","reserved","reserved","reserved","reserved","StandardCAN_FD","ExtendedCAN_FD";
BA_DEF_ BO_  "DiagRequest" ENUM  "No","Yes";
BA_DEF_ BO_  "DiagResponse" ENUM  "No","Yes";
BA_DEF_ BO_  "DiagState" ENUM  "No","Yes";
BA_DEF_ BO_  "DiagConnection" INT 0 65535;
BA_DEF_ BO_  "GenMsgCycleTime" INT 0 10000;
BA_DEF_ BO_  "GenMsgCycleTimeFast" INT 0 100000;
BA_DEF_ BO_  "GenMsgDelayTime" INT 0 1000;
BA_DEF_ BO_  "GenMsgILSupport" ENUM  "No","Yes";
BA_DEF_ BO_  "GenMsgNrOfRepetition" INT 0 100;
BA_DEF_ BO_  "GenMsgSendType" ENUM  "FixedPeriodic","Event","EnabledPeriodic","NotUsed","NotUsed","EventPeriodic","NotUsed","NotUsed","NoMsgSendType";
BA_DEF_ SG_  "GenSigSendType" ENUM  "Cyclic","OnWrite","OnWriteWithRepetition","OnChange","OnChangeWithRepetition","IfActive","IfActiveWithRepetition","NoSigSendType";
BA_DEF_ SG_  "GenSigStartValue" FLOAT 0 100000000000;
BA_DEF_ SG_  "GenSigTimeoutTime_RCM" INT 0 100000;
BA_DEF_ SG_  "GenSigTimeoutTime_FSC" INT 0 100000;
BA_DEF_ SG_  "GenSigTimeoutTime_EPAS" INT 0 100000;
BA_DEF_ SG_  "GenSigTimeoutTime_ECB" INT 0 100000;
BA_DEF_ SG_  "GenSigTimeoutTime_DSC" INT 0 100000;
BA_DEF_ SG_  "GenSigTimeoutTime_CGW" INT 0 100000;
BA_DEF_ BO_  "NetworkInitialization" ENUM  "No","Yes";
BA_DEF_ SG_  "GenSigEnvVarType" ENUM  "int","float","undef";
BA_DEF_ BO_  "NmAsrMessage" ENUM  "No","Yes";
BA_DEF_ BO_  "GenMsgTxConditionIg1On" ENUM  "No","Yes";
BA_DEF_ BO_  "GenMsgTxConditionPlusBOn" ENUM  "No","Yes";
BA_DEF_ SG_  "GenSigSuprvResp_CGW" ENUM  "None","Notify","Substitute","NotifySubstitute";
BA_DEF_ SG_  "GenSigSuprvRespSubValue_CGW" INT 0 10000000000;
BA_DEF_ SG_  "GenSigInvalidValue" INT 0 10000000000;
BA_DEF_ BO_  "CANoeMsgTxTimingIgnitionSwitched" ENUM  "AccOn","IG1On","IG2On","NoMsgTxTiming";
BA_DEF_REL_ BU_SG_REL_  "SC_Verification" ENUM  "No","Yes";
BA_DEF_DEF_REL_ "SC_Verification" "Yes";
BA_DEF_DEF_  "SCP_FreshnessValueTxLength" 4;
BA_DEF_DEF_  "SCP_FreshnessValueLength" 48;
BA_DEF_DEF_  "SCP_DataId" 0;
BA_DEF_DEF_  "SCP_AuthInfoTxLength" 28;
BA_DEF_DEF_  "SC_Message" "No";
BA_DEF_DEF_  "CANFD_BRS" "1";
BA_DEF_DEF_  "VFrameFormat" "ExtendedCAN_FD";
BA_DEF_DEF_  "DiagRequest" "No";
BA_DEF_DEF_  "DiagResponse" "No";
BA_DEF_DEF_  "DiagState" "No";
BA_DEF_DEF_  "DiagConnection" 0;
BA_DEF_DEF_  "GenMsgCycleTime" 0;
BA_DEF_DEF_  "GenMsgCycleTimeFast" 0;
BA_DEF_DEF_  "GenMsgDelayTime" 20;
BA_DEF_DEF_  "GenMsgILSupport" "Yes";
BA_DEF_DEF_  "GenMsgNrOfRepetition" 0;
BA_DEF_DEF_  "GenMsgSendType" "NoMsgSendType";
BA_DEF_DEF_  "GenSigSendType" "NoSigSendType";
BA_DEF_DEF_  "GenSigStartValue" 0;
BA_DEF_DEF_  "GenSigTimeoutTime_RCM" 5000;
BA_DEF_DEF_  "GenSigTimeoutTime_FSC" 5000;
BA_DEF_DEF_  "GenSigTimeoutTime_EPAS" 5000;
BA_DEF_DEF_  "GenSigTimeoutTime_ECB" 5000;
BA_DEF_DEF_  "GenSigTimeoutTime_DSC" 5000;
BA_DEF_DEF_  "GenSigTimeoutTime_CGW" 5000;
BA_DEF_DEF_  "NetworkInitialization" "No";
BA_DEF_DEF_  "GenSigEnvVarType" "undef";
BA_DEF_DEF_  "NmAsrMessage" "No";
BA_DEF_DEF_  "GenMsgTxConditionIg1On" "No";
BA_DEF_DEF_  "GenMsgTxConditionPlusBOn" "No";
BA_DEF_DEF_  "GenSigSuprvResp_CGW" "None";
BA_DEF_DEF_  "GenSigSuprvRespSubValue_CGW" 0;
BA_DEF_DEF_  "GenSigInvalidValue" 0;
BA_DEF_DEF_  "CANoeMsgTxTimingIgnitionSwitched" "NoMsgTxTiming";
BA_ "GenMsgTxConditionPlusBOn" BO_ 960 1;
BA_ "CANFD_BRS" BO_ 960 0;
BA_ "VFrameFormat" BO_ 960 0;
BA_ "GenMsgCycleTime" BO_ 960 200;
BA_ "GenMsgSendType" BO_ 960 5;
BA_ "GenMsgTxConditionIg1On" BO_ 945 1;
BA_ "CANFD_BRS" BO_ 945 0;
BA_ "VFrameFormat" BO_ 945 0;
BA_ "GenMsgCycleTime" BO_ 945 1000;
BA_ "GenMsgSendType" BO_ 945 5;
BA_ "GenMsgTxConditionIg1On" BO_ 865 1;
BA_ "CANFD_BRS" BO_ 865 0;
BA_ "VFrameFormat" BO_ 865 0;
BA_ "GenMsgCycleTime" BO_ 865 64;
BA_ "GenMsgSendType" BO_ 865 0;
BA_ "GenMsgTxConditionIg1On" BO_ 836 1;
BA_ "CANFD_BRS" BO_ 836 0;
BA_ "VFrameFormat" BO_ 836 0;
BA_ "GenMsgDelayTime" BO_ 836 0;
BA_ "GenMsgCycleTime" BO_ 836 20;
BA_ "GenMsgSendType" BO_ 836 0;
BA_ "GenMsgTxConditionIg1On" BO_ 835 1;
BA_ "CANFD_BRS" BO_ 835 0;
BA_ "VFrameFormat" BO_ 835 0;
BA_ "GenMsgDelayTime" BO_ 835 0;
BA_ "GenMsgCycleTime" BO_ 835 20;
BA_ "GenMsgSendType" BO_ 835 0;
BA_ "GenMsgTxConditionIg1On" BO_ 834 1;
BA_ "CANFD_BRS" BO_ 834 0;
BA_ "VFrameFormat" BO_ 834 0;
BA_ "GenMsgSendType" BO_ 834 1;
BA_ "GenMsgTxConditionIg1On" BO_ 832 1;
BA_ "CANFD_BRS" BO_ 832 0;
BA_ "VFrameFormat" BO_ 832 0;
BA_ "GenMsgCycleTime" BO_ 832 100;
BA_ "SCP_DataId" BO_ 832 832;
BA_ "SC_Message" BO_ 832 1;
BA_ "GenMsgSendType" BO_ 832 5;
BA_ "GenMsgTxConditionIg1On" BO_ 831 1;
BA_ "CANFD_BRS" BO_ 831 0;
BA_ "VFrameFormat" BO_ 831 0;
BA_ "GenMsgCycleTime" BO_ 831 100;
BA_ "SCP_DataId" BO_ 831 831;
BA_ "SC_Message" BO_ 831 1;
BA_ "GenMsgSendType" BO_ 831 5;
BA_ "GenMsgTxConditionIg1On" BO_ 830 1;
BA_ "CANFD_BRS" BO_ 830 0;
BA_ "VFrameFormat" BO_ 830 0;
BA_ "GenMsgCycleTime" BO_ 830 100;
BA_ "SCP_DataId" BO_ 830 830;
BA_ "SC_Message" BO_ 830 1;
BA_ "GenMsgSendType" BO_ 830 5;
BA_ "GenMsgTxConditionPlusBOn" BO_ 628 1;
BA_ "CANFD_BRS" BO_ 628 0;
BA_ "VFrameFormat" BO_ 628 0;
BA_ "GenMsgCycleTime" BO_ 628 100;
BA_ "GenMsgSendType" BO_ 628 5;
BA_ "GenMsgTxConditionIg1On" BO_ 570 1;
BA_ "CANFD_BRS" BO_ 570 0;
BA_ "VFrameFormat" BO_ 570 0;
BA_ "GenMsgDelayTime" BO_ 570 0;
BA_ "GenMsgCycleTime" BO_ 570 12;
BA_ "SCP_DataId" BO_ 570 570;
BA_ "SC_Message" BO_ 570 1;
BA_ "GenMsgSendType" BO_ 570 0;
BA_ "GenMsgTxConditionPlusBOn" BO_ 552 1;
BA_ "CANFD_BRS" BO_ 552 0;
BA_ "VFrameFormat" BO_ 552 0;
BA_ "GenMsgDelayTime" BO_ 552 0;
BA_ "GenMsgCycleTime" BO_ 552 20;
BA_ "GenMsgSendType" BO_ 552 0;
BA_ "GenMsgTxConditionPlusBOn" BO_ 547 1;
BA_ "CANFD_BRS" BO_ 547 0;
BA_ "VFrameFormat" BO_ 547 0;
BA_ "GenMsgCycleTime" BO_ 547 50;
BA_ "GenMsgSendType" BO_ 547 0;
BA_ "GenMsgTxConditionIg1On" BO_ 546 1;
BA_ "CANFD_BRS" BO_ 546 0;
BA_ "VFrameFormat" BO_ 546 0;
BA_ "NetworkInitialization" BO_ 546 1;
BA_ "GenMsgDelayTime" BO_ 546 0;
BA_ "GenMsgCycleTime" BO_ 546 20;
BA_ "GenMsgSendType" BO_ 546 0;
BA_ "GenMsgTxConditionPlusBOn" BO_ 543 1;
BA_ "CANFD_BRS" BO_ 543 0;
BA_ "VFrameFormat" BO_ 543 0;
BA_ "GenMsgDelayTime" BO_ 543 0;
BA_ "GenMsgCycleTime" BO_ 543 20;
BA_ "GenMsgSendType" BO_ 543 0;
BA_ "GenMsgTxConditionPlusBOn" BO_ 542 1;
BA_ "CANFD_BRS" BO_ 542 0;
BA_ "VFrameFormat" BO_ 542 0;
BA_ "GenMsgDelayTime" BO_ 542 0;
BA_ "GenMsgCycleTime" BO_ 542 20;
BA_ "SCP_DataId" BO_ 542 542;
BA_ "SC_Message" BO_ 542 1;
BA_ "GenMsgSendType" BO_ 542 0;
BA_ "GenMsgTxConditionPlusBOn" BO_ 537 1;
BA_ "CANFD_BRS" BO_ 537 0;
BA_ "VFrameFormat" BO_ 537 0;
BA_ "GenMsgDelayTime" BO_ 537 0;
BA_ "GenMsgCycleTime" BO_ 537 20;
BA_ "GenMsgSendType" BO_ 537 0;
BA_ "GenMsgTxConditionPlusBOn" BO_ 533 1;
BA_ "CANFD_BRS" BO_ 533 0;
BA_ "VFrameFormat" BO_ 533 0;
BA_ "GenMsgDelayTime" BO_ 533 0;
BA_ "GenMsgCycleTime" BO_ 533 20;
BA_ "GenMsgSendType" BO_ 533 0;
BA_ "GenMsgTxConditionPlusBOn" BO_ 532 1;
BA_ "CANFD_BRS" BO_ 532 0;
BA_ "VFrameFormat" BO_ 532 0;
BA_ "GenMsgDelayTime" BO_ 532 0;
BA_ "GenMsgCycleTime" BO_ 532 20;
BA_ "SCP_DataId" BO_ 532 532;
BA_ "SC_Message" BO_ 532 1;
BA_ "GenMsgSendType" BO_ 532 0;
BA_ "GenMsgTxConditionPlusBOn" BO_ 531 1;
BA_ "CANFD_BRS" BO_ 531 0;
BA_ "VFrameFormat" BO_ 531 0;
BA_ "GenMsgDelayTime" BO_ 531 0;
BA_ "GenMsgCycleTime" BO_ 531 20;
BA_ "SCP_DataId" BO_ 531 531;
BA_ "SC_Message" BO_ 531 1;
BA_ "GenMsgSendType" BO_ 531 0;
BA_ "GenMsgTxConditionPlusBOn" BO_ 530 1;
BA_ "CANFD_BRS" BO_ 530 0;
BA_ "VFrameFormat" BO_ 530 0;
BA_ "GenMsgDelayTime" BO_ 530 0;
BA_ "GenMsgCycleTime" BO_ 530 20;
BA_ "SCP_DataId" BO_ 530 530;
BA_ "SC_Message" BO_ 530 1;
BA_ "GenMsgSendType" BO_ 530 0;
BA_ "GenMsgTxConditionPlusBOn" BO_ 520 1;
BA_ "CANFD_BRS" BO_ 520 0;
BA_ "VFrameFormat" BO_ 520 0;
BA_ "GenMsgDelayTime" BO_ 520 0;
BA_ "GenMsgCycleTime" BO_ 520 20;
BA_ "SCP_DataId" BO_ 520 520;
BA_ "SC_Message" BO_ 520 1;
BA_ "GenMsgSendType" BO_ 520 0;
BA_ "GenMsgTxConditionPlusBOn" BO_ 515 1;
BA_ "CANFD_BRS" BO_ 515 0;
BA_ "VFrameFormat" BO_ 515 0;
BA_ "SCP_DataId" BO_ 515 515;
BA_ "SC_Message" BO_ 515 1;
BA_ "GenMsgDelayTime" BO_ 515 0;
BA_ "GenMsgCycleTime" BO_ 515 100;
BA_ "GenMsgSendType" BO_ 515 0;
BA_ "GenMsgTxConditionIg1On" BO_ 514 1;
BA_ "CANFD_BRS" BO_ 514 0;
BA_ "VFrameFormat" BO_ 514 0;
BA_ "NetworkInitialization" BO_ 514 1;
BA_ "GenMsgDelayTime" BO_ 514 0;
BA_ "GenMsgCycleTime" BO_ 514 10;
BA_ "GenMsgSendType" BO_ 514 0;
BA_ "GenMsgTxConditionIg1On" BO_ 357 1;
BA_ "CANFD_BRS" BO_ 357 0;
BA_ "VFrameFormat" BO_ 357 0;
BA_ "NetworkInitialization" BO_ 357 1;
BA_ "GenMsgDelayTime" BO_ 357 0;
BA_ "GenMsgCycleTime" BO_ 357 10;
BA_ "GenMsgSendType" BO_ 357 0;
BA_ "GenMsgTxConditionIg1On" BO_ 304 1;
BA_ "CANFD_BRS" BO_ 304 0;
BA_ "VFrameFormat" BO_ 304 0;
BA_ "NetworkInitialization" BO_ 304 1;
BA_ "GenMsgDelayTime" BO_ 304 0;
BA_ "GenMsgCycleTime" BO_ 304 20;
BA_ "GenMsgSendType" BO_ 304 0;
BA_ "GenMsgTxConditionPlusBOn" BO_ 253 1;
BA_ "CANFD_BRS" BO_ 253 0;
BA_ "VFrameFormat" BO_ 253 0;
BA_ "NetworkInitialization" BO_ 253 1;
BA_ "GenMsgDelayTime" BO_ 253 0;
BA_ "GenMsgCycleTime" BO_ 253 20;
BA_ "GenMsgSendType" BO_ 253 0;
BA_ "GenMsgTxConditionIg1On" BO_ 192 1;
BA_ "CANFD_BRS" BO_ 192 0;
BA_ "VFrameFormat" BO_ 192 0;
BA_ "GenMsgCycleTime" BO_ 192 200;
BA_ "GenMsgSendType" BO_ 192 5;
BA_ "GenMsgTxConditionPlusBOn" BO_ 187 1;
BA_ "CANFD_BRS" BO_ 187 0;
BA_ "VFrameFormat" BO_ 187 0;
BA_ "GenMsgDelayTime" BO_ 187 0;
BA_ "GenMsgCycleTime" BO_ 187 10;
BA_ "SCP_DataId" BO_ 187 187;
BA_ "SC_Message" BO_ 187 1;
BA_ "GenMsgSendType" BO_ 187 0;
BA_ "GenMsgTxConditionPlusBOn" BO_ 186 1;
BA_ "CANFD_BRS" BO_ 186 0;
BA_ "VFrameFormat" BO_ 186 0;
BA_ "GenMsgDelayTime" BO_ 186 0;
BA_ "GenMsgCycleTime" BO_ 186 10;
BA_ "SCP_DataId" BO_ 186 186;
BA_ "SC_Message" BO_ 186 1;
BA_ "GenMsgSendType" BO_ 186 0;
BA_ "GenMsgTxConditionPlusBOn" BO_ 159 1;
BA_ "CANFD_BRS" BO_ 159 0;
BA_ "VFrameFormat" BO_ 159 0;
BA_ "GenMsgCycleTime" BO_ 159 200;
BA_ "GenMsgSendType" BO_ 159 5;
BA_ "GenMsgTxConditionPlusBOn" BO_ 154 1;
BA_ "CANFD_BRS" BO_ 154 0;
BA_ "VFrameFormat" BO_ 154 0;
BA_ "GenMsgCycleTime" BO_ 154 100;
BA_ "GenMsgSendType" BO_ 154 5;
BA_ "GenMsgTxConditionPlusBOn" BO_ 152 1;
BA_ "CANFD_BRS" BO_ 152 0;
BA_ "VFrameFormat" BO_ 152 0;
BA_ "GenMsgDelayTime" BO_ 152 0;
BA_ "GenMsgCycleTime" BO_ 152 20;
BA_ "SCP_DataId" BO_ 152 152;
BA_ "SC_Message" BO_ 152 1;
BA_ "GenMsgSendType" BO_ 152 0;
BA_ "GenMsgTxConditionPlusBOn" BO_ 151 1;
BA_ "CANFD_BRS" BO_ 151 0;
BA_ "VFrameFormat" BO_ 151 0;
BA_ "GenMsgDelayTime" BO_ 151 0;
BA_ "GenMsgCycleTime" BO_ 151 20;
BA_ "SCP_DataId" BO_ 151 151;
BA_ "SC_Message" BO_ 151 1;
BA_ "GenMsgSendType" BO_ 151 0;
BA_ "GenMsgTxConditionPlusBOn" BO_ 150 1;
BA_ "CANFD_BRS" BO_ 150 0;
BA_ "VFrameFormat" BO_ 150 0;
BA_ "SCP_DataId" BO_ 150 150;
BA_ "SC_Message" BO_ 150 1;
BA_ "GenMsgSendType" BO_ 150 1;
BA_ "GenMsgTxConditionPlusBOn" BO_ 148 1;
BA_ "CANFD_BRS" BO_ 148 0;
BA_ "VFrameFormat" BO_ 148 0;
BA_ "SCP_DataId" BO_ 148 148;
BA_ "SC_Message" BO_ 148 1;
BA_ "GenMsgSendType" BO_ 148 1;
BA_ "GenMsgTxConditionPlusBOn" BO_ 146 1;
BA_ "CANFD_BRS" BO_ 146 0;
BA_ "VFrameFormat" BO_ 146 0;
BA_ "GenMsgCycleTime" BO_ 146 100;
BA_ "SCP_DataId" BO_ 146 146;
BA_ "SC_Message" BO_ 146 1;
BA_ "GenMsgSendType" BO_ 146 5;
BA_ "GenMsgTxConditionPlusBOn" BO_ 145 1;
BA_ "CANFD_BRS" BO_ 145 0;
BA_ "VFrameFormat" BO_ 145 0;
BA_ "GenMsgCycleTime" BO_ 145 100;
BA_ "GenMsgSendType" BO_ 145 5;
BA_ "GenMsgTxConditionPlusBOn" BO_ 137 1;
BA_ "CANFD_BRS" BO_ 137 0;
BA_ "VFrameFormat" BO_ 137 0;
BA_ "GenMsgCycleTime" BO_ 137 100;
BA_ "GenMsgSendType" BO_ 137 0;
BA_ "GenMsgTxConditionIg1On" BO_ 136 1;
BA_ "CANFD_BRS" BO_ 136 0;
BA_ "VFrameFormat" BO_ 136 0;
BA_ "GenMsgDelayTime" BO_ 136 0;
BA_ "GenMsgCycleTime" BO_ 136 20;
BA_ "GenMsgSendType" BO_ 136 0;
BA_ "GenMsgTxConditionIg1On" BO_ 135 1;
BA_ "CANFD_BRS" BO_ 135 0;
BA_ "VFrameFormat" BO_ 135 0;
BA_ "GenMsgDelayTime" BO_ 135 0;
BA_ "GenMsgCycleTime" BO_ 135 12;
BA_ "SCP_DataId" BO_ 135 135;
BA_ "SC_Message" BO_ 135 1;
BA_ "GenMsgSendType" BO_ 135 0;
BA_ "GenMsgTxConditionPlusBOn" BO_ 133 1;
BA_ "CANFD_BRS" BO_ 133 0;
BA_ "VFrameFormat" BO_ 133 0;
BA_ "GenMsgDelayTime" BO_ 133 0;
BA_ "GenMsgCycleTime" BO_ 133 20;
BA_ "GenMsgSendType" BO_ 133 0;
BA_ "GenMsgTxConditionIg1On" BO_ 132 1;
BA_ "CANFD_BRS" BO_ 132 0;
BA_ "VFrameFormat" BO_ 132 0;
BA_ "GenMsgDelayTime" BO_ 132 0;
BA_ "GenMsgCycleTime" BO_ 132 12;
BA_ "SCP_DataId" BO_ 132 132;
BA_ "SC_Message" BO_ 132 1;
BA_ "GenMsgSendType" BO_ 132 0;
BA_ "GenMsgTxConditionIg1On" BO_ 130 1;
BA_ "CANFD_BRS" BO_ 130 0;
BA_ "VFrameFormat" BO_ 130 0;
BA_ "GenMsgDelayTime" BO_ 130 0;
BA_ "GenMsgCycleTime" BO_ 130 20;
BA_ "GenMsgSendType" BO_ 130 0;
BA_ "GenMsgTxConditionIg1On" BO_ 128 1;
BA_ "CANFD_BRS" BO_ 128 0;
BA_ "VFrameFormat" BO_ 128 0;
BA_ "GenMsgDelayTime" BO_ 128 0;
BA_ "GenMsgCycleTime" BO_ 128 20;
BA_ "SCP_DataId" BO_ 128 128;
BA_ "SC_Message" BO_ 128 1;
BA_ "GenMsgSendType" BO_ 128 0;
BA_ "GenMsgTxConditionIg1On" BO_ 127 1;
BA_ "CANFD_BRS" BO_ 127 0;
BA_ "VFrameFormat" BO_ 127 0;
BA_ "GenMsgDelayTime" BO_ 127 0;
BA_ "GenMsgCycleTime" BO_ 127 20;
BA_ "GenMsgSendType" BO_ 127 0;
BA_ "GenMsgTxConditionPlusBOn" BO_ 126 1;
BA_ "CANFD_BRS" BO_ 126 0;
BA_ "VFrameFormat" BO_ 126 0;
BA_ "GenMsgDelayTime" BO_ 126 0;
BA_ "GenMsgCycleTime" BO_ 126 20;
BA_ "GenMsgSendType" BO_ 126 0;
BA_ "GenMsgTxConditionPlusBOn" BO_ 125 1;
BA_ "CANFD_BRS" BO_ 125 0;
BA_ "VFrameFormat" BO_ 125 0;
BA_ "GenMsgDelayTime" BO_ 125 0;
BA_ "GenMsgCycleTime" BO_ 125 20;
BA_ "SCP_DataId" BO_ 125 125;
BA_ "SC_Message" BO_ 125 1;
BA_ "GenMsgSendType" BO_ 125 0;
BA_ "GenMsgTxConditionPlusBOn" BO_ 124 1;
BA_ "CANFD_BRS" BO_ 124 0;
BA_ "VFrameFormat" BO_ 124 0;
BA_ "GenMsgDelayTime" BO_ 124 0;
BA_ "GenMsgCycleTime" BO_ 124 20;
BA_ "SCP_DataId" BO_ 124 124;
BA_ "SC_Message" BO_ 124 1;
BA_ "GenMsgSendType" BO_ 124 0;
BA_ "GenMsgTxConditionPlusBOn" BO_ 123 1;
BA_ "CANFD_BRS" BO_ 123 0;
BA_ "VFrameFormat" BO_ 123 0;
BA_ "GenMsgCycleTime" BO_ 123 100;
BA_ "GenMsgSendType" BO_ 123 0;
BA_ "GenMsgTxConditionPlusBOn" BO_ 116 1;
BA_ "CANFD_BRS" BO_ 116 0;
BA_ "VFrameFormat" BO_ 116 0;
BA_ "GenMsgDelayTime" BO_ 116 0;
BA_ "GenMsgCycleTime" BO_ 116 20;
BA_ "SCP_DataId" BO_ 116 116;
BA_ "SC_Message" BO_ 116 1;
BA_ "GenMsgSendType" BO_ 116 0;
BA_ "GenMsgTxConditionPlusBOn" BO_ 115 1;
BA_ "CANFD_BRS" BO_ 115 0;
BA_ "VFrameFormat" BO_ 115 0;
BA_ "GenMsgDelayTime" BO_ 115 0;
BA_ "GenMsgCycleTime" BO_ 115 20;
BA_ "SCP_DataId" BO_ 115 115;
BA_ "SC_Message" BO_ 115 1;
BA_ "GenMsgSendType" BO_ 115 0;
BA_ "GenMsgTxConditionIg1On" BO_ 114 1;
BA_ "CANFD_BRS" BO_ 114 0;
BA_ "VFrameFormat" BO_ 114 0;
BA_ "GenMsgDelayTime" BO_ 114 0;
BA_ "GenMsgCycleTime" BO_ 114 10;
BA_ "SCP_DataId" BO_ 114 114;
BA_ "SC_Message" BO_ 114 1;
BA_ "GenMsgSendType" BO_ 114 0;
BA_ "GenMsgTxConditionIg1On" BO_ 113 1;
BA_ "CANFD_BRS" BO_ 113 0;
BA_ "VFrameFormat" BO_ 113 0;
BA_ "GenMsgDelayTime" BO_ 113 0;
BA_ "GenMsgCycleTime" BO_ 113 10;
BA_ "SCP_DataId" BO_ 113 113;
BA_ "SC_Message" BO_ 113 1;
BA_ "GenMsgSendType" BO_ 113 0;
BA_ "GenMsgTxConditionIg1On" BO_ 112 1;
BA_ "CANFD_BRS" BO_ 112 0;
BA_ "VFrameFormat" BO_ 112 0;
BA_ "GenMsgDelayTime" BO_ 112 0;
BA_ "GenMsgCycleTime" BO_ 112 10;
BA_ "SCP_DataId" BO_ 112 112;
BA_ "SC_Message" BO_ 112 1;
BA_ "GenMsgSendType" BO_ 112 0;
BA_ "GenMsgTxConditionPlusBOn" BO_ 80 1;
BA_ "CANFD_BRS" BO_ 80 0;
BA_ "VFrameFormat" BO_ 80 0;
BA_ "GenMsgCycleTime" BO_ 80 100;
BA_ "GenMsgSendType" BO_ 80 5;
BA_ "GenMsgTxConditionIg1On" BO_ 74 1;
BA_ "CANFD_BRS" BO_ 74 0;
BA_ "VFrameFormat" BO_ 74 0;
BA_ "GenMsgDelayTime" BO_ 74 10;
BA_ "SCP_DataId" BO_ 74 74;
BA_ "SC_Message" BO_ 74 1;
BA_ "GenMsgSendType" BO_ 74 1;
BA_ "GenMsgTxConditionPlusBOn" BO_ 32 1;
BA_ "CANFD_BRS" BO_ 32 0;
BA_ "VFrameFormat" BO_ 32 0;
BA_ "GenMsgCycleTime" BO_ 32 100;
BA_ "SCP_DataId" BO_ 32 32;
BA_ "SCP_FreshnessValueTxLength" BO_ 32 36;
BA_ "SCP_FreshnessValueLength" BO_ 32 40;
BA_ "SC_Message" BO_ 32 1;
BA_ "GenMsgSendType" BO_ 32 0;
BA_ "GenMsgTxConditionIg1On" BO_ 28 1;
BA_ "CANFD_BRS" BO_ 28 0;
BA_ "VFrameFormat" BO_ 28 0;
BA_ "GenMsgSendType" BO_ 28 1;
BA_ "GenMsgTxConditionIg1On" BO_ 27 1;
BA_ "CANFD_BRS" BO_ 27 0;
BA_ "VFrameFormat" BO_ 27 0;
BA_ "GenMsgSendType" BO_ 27 1;
BA_ "GenMsgTxConditionIg1On" BO_ 26 1;
BA_ "CANFD_BRS" BO_ 26 0;
BA_ "VFrameFormat" BO_ 26 0;
BA_ "GenMsgSendType" BO_ 26 1;
BA_ "GenMsgTxConditionIg1On" BO_ 25 1;
BA_ "CANFD_BRS" BO_ 25 0;
BA_ "VFrameFormat" BO_ 25 0;
BA_ "GenMsgSendType" BO_ 25 1;
BA_ "GenMsgTxConditionIg1On" BO_ 24 1;
BA_ "CANFD_BRS" BO_ 24 0;
BA_ "VFrameFormat" BO_ 24 0;
BA_ "GenMsgSendType" BO_ 24 1;
BA_ "GenMsgTxConditionIg1On" BO_ 23 1;
BA_ "CANFD_BRS" BO_ 23 0;
BA_ "VFrameFormat" BO_ 23 0;
BA_ "GenMsgSendType" BO_ 23 1;
BA_ "GenMsgTxConditionIg1On" BO_ 22 1;
BA_ "CANFD_BRS" BO_ 22 0;
BA_ "VFrameFormat" BO_ 22 0;
BA_ "GenMsgSendType" BO_ 22 1;
BA_ "GenMsgTxConditionIg1On" BO_ 21 1;
BA_ "CANFD_BRS" BO_ 21 0;
BA_ "VFrameFormat" BO_ 21 0;
BA_ "GenMsgSendType" BO_ 21 1;
BA_ "GenMsgTxConditionIg1On" BO_ 20 1;
BA_ "CANFD_BRS" BO_ 20 0;
BA_ "VFrameFormat" BO_ 20 0;
BA_ "GenMsgSendType" BO_ 20 1;
BA_ "GenMsgTxConditionIg1On" BO_ 19 1;
BA_ "CANFD_BRS" BO_ 19 0;
BA_ "VFrameFormat" BO_ 19 0;
BA_ "GenMsgSendType" BO_ 19 1;
BA_ "GenMsgTxConditionIg1On" BO_ 18 1;
BA_ "CANFD_BRS" BO_ 18 0;
BA_ "VFrameFormat" BO_ 18 0;
BA_ "GenMsgSendType" BO_ 18 1;
BA_ "GenMsgTxConditionIg1On" BO_ 17 1;
BA_ "CANFD_BRS" BO_ 17 0;
BA_ "VFrameFormat" BO_ 17 0;
BA_ "GenMsgSendType" BO_ 17 1;
BA_ "CANFD_BRS" BO_ 16 0;
BA_ "VFrameFormat" BO_ 16 0;
BA_ "GenMsgTxConditionIg1On" BO_ 16 1;
BA_ "GenMsgSendType" BO_ 16 1;
BA_ "GenSigStartValue" SG_ 960 HazardSw_D_Actl 3;
BA_ "GenSigSendType" SG_ 960 HazardSw_D_Actl 3;
BA_ "GenSigSendType" SG_ 960 RearDef_B_Rq 3;
BA_ "GenSigSendType" SG_ 960 FrontDef_B_Rq 3;
BA_ "GenSigSendType" SG_ 960 PanelHeaterSwitchIn_RH 3;
BA_ "GenSigSendType" SG_ 960 PanelHeaterSwitchIn_LH 3;
BA_ "GenSigSendType" SG_ 960 SteeringHeaterSwitchIn 3;
BA_ "GenSigSendType" SG_ 960 SeatVentilationSwitchIn_RH 3;
BA_ "GenSigSendType" SG_ 960 SeatHeaterSwitchIn_RH 3;
BA_ "GenSigSendType" SG_ 960 SeatVentilationSwitchIn_LH 3;
BA_ "GenSigSendType" SG_ 960 SeatHeaterSwitchIn_LH 3;
BA_ "GenSigSendType" SG_ 960 ipREARmode 3;
BA_ "GenSigSendType" SG_ 960 ipECOmode 3;
BA_ "GenSigSendType" SG_ 960 ipAImode 3;
BA_ "GenSigSendType" SG_ 960 ipADmode 3;
BA_ "GenSigSendType" SG_ 960 ipACmode 3;
BA_ "GenSigSendType" SG_ 960 ipBlwLvl 3;
BA_ "GenSigSendType" SG_ 960 ipTSetPs 3;
BA_ "GenSigSendType" SG_ 960 ipTSetDr 3;
BA_ "GenSigSendType" SG_ 945 CDT_HV 3;
BA_ "GenSigSendType" SG_ 945 CDT 3;
BA_ "GenSigInvalidValue" SG_ 836 SAS_dVy_AACN 255;
BA_ "GenSigStartValue" SG_ 836 SAS_dVy_AACN 254;
BA_ "GenSigInvalidValue" SG_ 836 SAS_dVx_AACN 255;
BA_ "GenSigStartValue" SG_ 836 SAS_dVx_AACN 254;
BA_ "GenSigInvalidValue" SG_ 836 SAS_dVx_Event 65535;
BA_ "GenSigStartValue" SG_ 836 SAS_dVx_Event 65534;
BA_ "GenSigInvalidValue" SG_ 836 SAS_dVy_Periodic 65535;
BA_ "GenSigStartValue" SG_ 836 SAS_dVy_Periodic 65534;
BA_ "GenSigInvalidValue" SG_ 836 SAS_dVx_Periodic 65535;
BA_ "GenSigStartValue" SG_ 836 SAS_dVx_Periodic 65534;
BA_ "GenSigInvalidValue" SG_ 835 SAS_Gz 16383;
BA_ "GenSigStartValue" SG_ 835 SAS_Gz 16382;
BA_ "GenSigInvalidValue" SG_ 835 SAS_Gy 1023;
BA_ "GenSigStartValue" SG_ 835 SAS_Gy 1022;
BA_ "GenSigInvalidValue" SG_ 835 SAS_Gx 1023;
BA_ "GenSigStartValue" SG_ 835 SAS_Gx 1022;
BA_ "GenSigInvalidValue" SG_ 834 Maximum_Lateral_deltaV_2 255;
BA_ "GenSigStartValue" SG_ 834 Maximum_Lateral_deltaV_2 254;
BA_ "GenSigSendType" SG_ 834 Maximum_Lateral_deltaV_2 1;
BA_ "GenSigInvalidValue" SG_ 834 Maximum_Longitudinal_deltaV_2 255;
BA_ "GenSigStartValue" SG_ 834 Maximum_Longitudinal_deltaV_2 254;
BA_ "GenSigSendType" SG_ 834 Maximum_Longitudinal_deltaV_2 1;
BA_ "GenSigInvalidValue" SG_ 834 Maximum_Lateral_deltaV_1 255;
BA_ "GenSigStartValue" SG_ 834 Maximum_Lateral_deltaV_1 254;
BA_ "GenSigSendType" SG_ 834 Maximum_Lateral_deltaV_1 1;
BA_ "GenSigInvalidValue" SG_ 834 Maximum_Longitudinal_deltaV_1 255;
BA_ "GenSigStartValue" SG_ 834 Maximum_Longitudinal_deltaV_1 254;
BA_ "GenSigSendType" SG_ 834 Maximum_Longitudinal_deltaV_1 1;
BA_ "GenSigSendType" SG_ 832 RCM_EDRtype 3;
BA_ "GenSigInvalidValue" SG_ 832 ConnectedEDRTrigger 2;
BA_ "GenSigSendType" SG_ 832 ConnectedEDRTrigger 3;
BA_ "GenSigSendType" SG_ 832 DHS_RILReq 3;
BA_ "GenSigStartValue" SG_ 832 FirstRowBucklePsngr 1;
BA_ "GenSigSendType" SG_ 832 FirstRowBucklePsngr 3;
BA_ "GenSigStartValue" SG_ 832 OCS_Status 1;
BA_ "GenSigSendType" SG_ 832 OCS_Status 3;
BA_ "GenSigStartValue" SG_ 832 PAD_Ind_Req 4;
BA_ "GenSigSendType" SG_ 832 PAD_Ind_Req 3;
BA_ "GenSigStartValue" SG_ 832 RILReq 1;
BA_ "GenSigSendType" SG_ 832 RILReq 3;
BA_ "GenSigSendType" SG_ 831 RcmStat_B_Actl_brk 3;
BA_ "GenSigSendType" SG_ 831 threshold_ovr_rollover_brk 3;
BA_ "GenSigSendType" SG_ 831 threshold_ovr_rear_brk 3;
BA_ "GenSigSendType" SG_ 831 threshold_ovr_side_pass_brk 3;
BA_ "GenSigSendType" SG_ 831 threshold_ovr_side_Driver_brk 3;
BA_ "GenSigSendType" SG_ 831 threshold_ovr_front_brk 3;
BA_ "GenSigSendType" SG_ 830 threshold_over_rollover_static 3;
BA_ "GenSigSendType" SG_ 830 RcmStat_B_Actl 3;
BA_ "GenSigSendType" SG_ 830 FuelCutoffReq 3;
BA_ "GenSigSendType" SG_ 830 threshold_over_rollover 3;
BA_ "GenSigSendType" SG_ 830 threshold_over_rear 3;
BA_ "GenSigSendType" SG_ 830 threshold_over_side_passenger 3;
BA_ "GenSigSendType" SG_ 830 threshold_over_side_Driver 3;
BA_ "GenSigSendType" SG_ 830 threshold_over_front 3;
BA_ "GenSigSendType" SG_ 628 System_Check 3;
BA_ "GenSigSendType" SG_ 628 ABS_Tx_Request 3;
BA_ "GenSigSendType" SG_ 628 Key_Not_Found 3;
BA_ "GenSigSendType" SG_ 628 Key_Battery_Low 3;
BA_ "GenSigSendType" SG_ 628 Power_Not_Off 3;
BA_ "GenSigSendType" SG_ 628 Shift_position_Display 3;
BA_ "GenSigSendType" SG_ 628 Eng_start_Display 3;
BA_ "GenSigSendType" SG_ 628 Shift_lever_Display 3;
BA_ "GenSigSendType" SG_ 628 ESCL_Display 3;
BA_ "GenSigSendType" SG_ 628 Press_pedal_Display 3;
BA_ "GenSigSendType" SG_ 628 Lamp_KEY_RED_Control 3;
BA_ "GenSigSendType" SG_ 628 Lamp_KEY_GREEN_Control 3;
BA_ "GenSigStartValue" SG_ 570 Epas_ContStatus 1;
BA_ "GenSigInvalidValue" SG_ 570 SteeringColumnTorque 255;
BA_ "GenSigStartValue" SG_ 570 SteeringColumnTorque 254;
BA_ "GenSigInvalidValue" SG_ 552 TransmChangeLeverPosition 15;
BA_ "GenSigStartValue" SG_ 552 TransmChangeLeverPosition 14;
BA_ "GenSigStartValue" SG_ 552 ShiftrPos_D_Qf 1;
BA_ "GenSigInvalidValue" SG_ 552 TransmParking_D_Act 7;
BA_ "GenSigInvalidValue" SG_ 552 DispAtLvrPos_D_Rq 15;
BA_ "GenSigStartValue" SG_ 552 DispAtLvrPos_D_Rq 14;
BA_ "GenSigInvalidValue" SG_ 552 DispGearPos_D_Rq 15;
BA_ "GenSigStartValue" SG_ 552 DispGearPos_D_Rq 14;
BA_ "GenSigStartValue" SG_ 546 PT_Deceleration_Accel_Off 125;
BA_ "GenSigStartValue" SG_ 546 PT_Request_Accel_ADAS_FB 250;
BA_ "GenSigStartValue" SG_ 546 PT_Request_Accel_Pedal 2000;
BA_ "GenSigStartValue" SG_ 546 Request_ADAS_B_Decel 2000;
BA_ "GenSigStartValue" SG_ 542 Request_ADAS_Acceleration 2000;
BA_ "GenSigInvalidValue" SG_ 533 RRwheelSpeed 65535;
BA_ "GenSigSuprvRespSubValue_CGW" SG_ 533 RRwheelSpeed 65535;
BA_ "GenSigSuprvResp_CGW" SG_ 533 RRwheelSpeed 2;
BA_ "GenSigTimeoutTime_CGW" SG_ 533 RRwheelSpeed 8000;
BA_ "GenSigStartValue" SG_ 533 RRwheelSpeed 65534;
BA_ "GenSigInvalidValue" SG_ 533 RLwheelSpeed 65535;
BA_ "GenSigSuprvRespSubValue_CGW" SG_ 533 RLwheelSpeed 65535;
BA_ "GenSigSuprvResp_CGW" SG_ 533 RLwheelSpeed 2;
BA_ "GenSigTimeoutTime_CGW" SG_ 533 RLwheelSpeed 8000;
BA_ "GenSigStartValue" SG_ 533 RLwheelSpeed 65534;
BA_ "GenSigInvalidValue" SG_ 533 FRwheelSpeed 65535;
BA_ "GenSigSuprvRespSubValue_CGW" SG_ 533 FRwheelSpeed 65535;
BA_ "GenSigSuprvResp_CGW" SG_ 533 FRwheelSpeed 2;
BA_ "GenSigTimeoutTime_CGW" SG_ 533 FRwheelSpeed 8000;
BA_ "GenSigStartValue" SG_ 533 FRwheelSpeed 65534;
BA_ "GenSigInvalidValue" SG_ 533 FLwheelSpeed 65535;
BA_ "GenSigSuprvRespSubValue_CGW" SG_ 533 FLwheelSpeed 65535;
BA_ "GenSigSuprvResp_CGW" SG_ 533 FLwheelSpeed 2;
BA_ "GenSigTimeoutTime_CGW" SG_ 533 FLwheelSpeed 8000;
BA_ "GenSigStartValue" SG_ 533 FLwheelSpeed 65534;
BA_ "GenSigStartValue" SG_ 531 Request_AEB_Acceleration 2000;
BA_ "GenSigInvalidValue" SG_ 520 AccPedalPos 255;
BA_ "GenSigSendType" SG_ 515 EPB_info_1_MACTx 1;
BA_ "GenSigSendType" SG_ 515 EPB_info_1_FVTx 1;
BA_ "GenSigSendType" SG_ 515 ID_203_No_Cs 1;
BA_ "GenSigSendType" SG_ 515 ID_203_No_Cnt 1;
BA_ "GenSigSendType" SG_ 515 EPB_DisplayRequest5_RCM 1;
BA_ "GenSigSendType" SG_ 515 EPB_DisplayRequest4_RCM 1;
BA_ "GenSigSendType" SG_ 515 EPB_DisplayRequest3_RCM 1;
BA_ "GenSigStartValue" SG_ 515 EPB_Status_sa 4;
BA_ "GenSigSendType" SG_ 515 EPB_Status_sa 1;
BA_ "GenSigSendType" SG_ 515 EPB_SwitchPosition_sa 1;
BA_ "GenSigStartValue" SG_ 515 EPB_EnableExternalApply_DSC 1;
BA_ "GenSigSendType" SG_ 515 EPB_EnableExternalApply_DSC 1;
BA_ "GenSigSendType" SG_ 515 EPB_EnableDecelRequest_sa 1;
BA_ "GenSigInvalidValue" SG_ 515 EPB_DecelRequest 255;
BA_ "GenSigStartValue" SG_ 515 EPB_DecelRequest 166;
BA_ "GenSigSendType" SG_ 515 EPB_DecelRequest 1;
BA_ "GenSigStartValue" SG_ 514 ApedPosPcActl_D_Qf 1;
BA_ "GenSigInvalidValue" SG_ 514 EngAout_N_ReqTacho 8191;
BA_ "GenSigInvalidValue" SG_ 514 EngAout_N_Actl 8191;
BA_ "GenSigInvalidValue" SG_ 357 TrnTotTq_Rt_Est 65535;
BA_ "GenSigInvalidValue" SG_ 357 AWDTrgt_I_Req_165 4095;
BA_ "GenSigInvalidValue" SG_ 304 Clutch_Stroke 255;
BA_ "GenSigStartValue" SG_ 304 SISS_EngineState 1;
BA_ "GenSigInvalidValue" SG_ 253 Xev_Charge_Req_PCM 7;
BA_ "GenSigStartValue" SG_ 253 Xev_Charge_Req_PCM 6;
BA_ "GenSigStartValue" SG_ 253 PTGeneralWarn_Mirror 1;
BA_ "GenSigInvalidValue" SG_ 253 Drive_Mode_Towing_Req_PCM 3;
BA_ "GenSigStartValue" SG_ 253 Drive_Mode_Towing_Req_PCM 2;
BA_ "GenSigInvalidValue" SG_ 253 Drive_Mode_OffRoad_Req_PCM 3;
BA_ "GenSigStartValue" SG_ 253 Drive_Mode_OffRoad_Req_PCM 2;
BA_ "GenSigInvalidValue" SG_ 253 Drive_Mode_Sport_Req_PCM 3;
BA_ "GenSigStartValue" SG_ 253 Drive_Mode_Sport_Req_PCM 2;
BA_ "GenSigInvalidValue" SG_ 253 Drive_Mode_Normal_Req_PCM 3;
BA_ "GenSigStartValue" SG_ 253 Drive_Mode_Normal_Req_PCM 2;
BA_ "GenSigStartValue" SG_ 253 CrankingTime 2;
BA_ "GenSigInvalidValue" SG_ 253 Xev_Ev_Req_PCM 7;
BA_ "GenSigStartValue" SG_ 253 Xev_Ev_Req_PCM 6;
BA_ "GenSigSendType" SG_ 192 Auto_XevNormal_Mode_D_Rq 3;
BA_ "GenSigSendType" SG_ 192 Not_Select_Xevmode_D_Rq 3;
BA_ "GenSigSendType" SG_ 192 Auto_Normal_Mode_D_Rq 3;
BA_ "GenSigSendType" SG_ 192 Not_Select_Drivemode_D_Rq 3;
BA_ "GenSigSendType" SG_ 192 Trailer_Connect_D_Rq 3;
BA_ "GenSigSendType" SG_ 192 Drive_Mode_List_Popup 3;
BA_ "GenSigInvalidValue" SG_ 192 Xev_Mode_Charge_Permission 3;
BA_ "GenSigStartValue" SG_ 192 Xev_Mode_Charge_Permission 2;
BA_ "GenSigSendType" SG_ 192 Xev_Mode_Charge_Permission 3;
BA_ "GenSigInvalidValue" SG_ 192 Xev_Mode_Ev_Permission 3;
BA_ "GenSigStartValue" SG_ 192 Xev_Mode_Ev_Permission 2;
BA_ "GenSigSendType" SG_ 192 Xev_Mode_Ev_Permission 3;
BA_ "GenSigInvalidValue" SG_ 192 Xev_Mode_Status 15;
BA_ "GenSigStartValue" SG_ 192 Xev_Mode_Status 14;
BA_ "GenSigSendType" SG_ 192 Xev_Mode_Status 3;
BA_ "GenSigInvalidValue" SG_ 192 Drive_Mode_Towing_Permission 3;
BA_ "GenSigStartValue" SG_ 192 Drive_Mode_Towing_Permission 2;
BA_ "GenSigSendType" SG_ 192 Drive_Mode_Towing_Permission 3;
BA_ "GenSigInvalidValue" SG_ 192 Drive_Mode_Offroad_Permission 3;
BA_ "GenSigStartValue" SG_ 192 Drive_Mode_Offroad_Permission 2;
BA_ "GenSigSendType" SG_ 192 Drive_Mode_Offroad_Permission 3;
BA_ "GenSigInvalidValue" SG_ 192 Drive_Mode_Sport_Permission 3;
BA_ "GenSigStartValue" SG_ 192 Drive_Mode_Sport_Permission 2;
BA_ "GenSigSendType" SG_ 192 Drive_Mode_Sport_Permission 3;
BA_ "GenSigInvalidValue" SG_ 192 Drive_Mode_Normal_Permission 3;
BA_ "GenSigStartValue" SG_ 192 Drive_Mode_Normal_Permission 2;
BA_ "GenSigSendType" SG_ 192 Drive_Mode_Normal_Permission 3;
BA_ "GenSigInvalidValue" SG_ 192 Drive_Mode_List_Info 15;
BA_ "GenSigStartValue" SG_ 192 Drive_Mode_List_Info 14;
BA_ "GenSigSendType" SG_ 192 Drive_Mode_List_Info 3;
BA_ "GenSigInvalidValue" SG_ 192 Drive_Mode_Status 15;
BA_ "GenSigStartValue" SG_ 192 Drive_Mode_Status 14;
BA_ "GenSigSendType" SG_ 192 Drive_Mode_Status 3;
BA_ "GenSigInvalidValue" SG_ 187 RRwheelSpeed_MAC 4095;
BA_ "GenSigStartValue" SG_ 187 RRwheelSpeed_MAC 4094;
BA_ "GenSigInvalidValue" SG_ 187 RLwheelSpeed_MAC 4095;
BA_ "GenSigStartValue" SG_ 187 RLwheelSpeed_MAC 4094;
BA_ "GenSigInvalidValue" SG_ 186 FRwheelSpeed_MAC 4095;
BA_ "GenSigStartValue" SG_ 186 FRwheelSpeed_MAC 4094;
BA_ "GenSigInvalidValue" SG_ 186 FLwheelSpeed_MAC 4095;
BA_ "GenSigStartValue" SG_ 186 FLwheelSpeed_MAC 4094;
BA_ "GenSigSendType" SG_ 159 BpedDrvAppl_D_Actl 3;
BA_ "GenSigSendType" SG_ 159 IndirectIllumination_D_Rq 3;
BA_ "GenSigSendType" SG_ 159 WelcomIllumination_D_Rq 3;
BA_ "GenSigSendType" SG_ 159 FootLamp_D_Rq 3;
BA_ "GenSigSendType" SG_ 159 DoorCourtesyLamp_D_Rq 3;
BA_ "GenSigSendType" SG_ 159 CargoLamp_D_Rq 3;
BA_ "GenSigSendType" SG_ 159 DimmerCancel 3;
BA_ "GenSigInvalidValue" SG_ 159 EngOff_T_Actl 65535;
BA_ "GenSigStartValue" SG_ 159 EngOff_T_Actl 65534;
BA_ "GenSigSendType" SG_ 159 Drive_Mode_FlashReq 3;
BA_ "GenSigSendType" SG_ 159 Drive_Mode_Enabled 3;
BA_ "GenSigSendType" SG_ 159 CarMde_D_Actl 3;
BA_ "GenSigInvalidValue" SG_ 159 PanelBrightLevel_Pc_Actl 255;
BA_ "GenSigSendType" SG_ 159 PanelBrightLevel_Pc_Actl 3;
BA_ "GenSigSendType" SG_ 159 Reverselamp_B_Req 3;
BA_ "GenSigSendType" SG_ 159 IlumiMde_D_Actl 3;
BA_ "GenSigSendType" SG_ 159 Illum_PowerControlStatus 3;
BA_ "GenSigSendType" SG_ 159 AudioMute_B_Actl 3;
BA_ "GenSigStartValue" SG_ 159 RoomFuseStat_D_Actl 3;
BA_ "GenSigSendType" SG_ 159 RoomFuseStat_D_Actl 3;
BA_ "GenSigSendType" SG_ 154 SndRSP_Fail_B_Actl 3;
BA_ "GenSigSendType" SG_ 154 SndFSP_Fail_B_Actl 3;
BA_ "GenSigSendType" SG_ 154 Hazard_lamp_State_D_Actl 3;
BA_ "GenSigSendType" SG_ 154 DRL_Tail_Lamp_B_Rq 3;
BA_ "GenSigSendType" SG_ 154 TNS_Buzzer_Cntl_Req 3;
BA_ "GenSigSendType" SG_ 154 Turn_Snd_Cmd_Left 3;
BA_ "GenSigSendType" SG_ 154 Turn_Snd_Cmd_Right 3;
BA_ "GenSigSendType" SG_ 154 WiprGuid_B_Rq 3;
BA_ "GenSigSendType" SG_ 154 BurglarHorn_B_Req 3;
BA_ "GenSigSendType" SG_ 154 RSRmid_Indicator_Req 3;
BA_ "GenSigSendType" SG_ 154 RSRmid_DisplayReq 3;
BA_ "GenSigSendType" SG_ 154 BlwCont_B_Actl 3;
BA_ "GenSigSendType" SG_ 154 FrntWipr_D_Actl 3;
BA_ "GenSigSendType" SG_ 154 SteeringHeatCutLvl 3;
BA_ "GenSigSendType" SG_ 154 PtcCutLvl 3;
BA_ "GenSigSendType" SG_ 154 BmotCutLvl 3;
BA_ "GenSigSendType" SG_ 154 SeatHeatCutLvl 3;
BA_ "GenSigSendType" SG_ 154 RdefCutLvl 3;
BA_ "GenSigSendType" SG_ 154 SeatVentCutLvl 3;
BA_ "GenSigStartValue" SG_ 154 WshrLvl_D_Actl 3;
BA_ "GenSigSendType" SG_ 154 WshrLvl_D_Actl 3;
BA_ "GenSigSendType" SG_ 154 TNS_IpcDsply_D_Rq 3;
BA_ "GenSigSendType" SG_ 154 Turn_Ind_Cmd_Left 3;
BA_ "GenSigSendType" SG_ 154 Turn_Ind_Cmd_Right 3;
BA_ "GenSigSendType" SG_ 154 ResHeatCont_B_Actl 3;
BA_ "GenSigSendType" SG_ 154 ResEngCont_B_Actl 3;
BA_ "GenSigSendType" SG_ 154 CBDA_Sleep_B_Rq 3;
BA_ "GenSigSendType" SG_ 154 RearWiprLo_B_Rq 3;
BA_ "GenSigSendType" SG_ 154 AutoWiprIND_B_Rq 3;
BA_ "GenSigSendType" SG_ 154 RearFogIpcDsply_B_Rq 3;
BA_ "GenSigSendType" SG_ 154 HiBeamIpcDsply_B_Rq 3;
BA_ "GenSigSendType" SG_ 150 Cruise_Multi_Switch_2_MACTx 3;
BA_ "GenSigSendType" SG_ 150 Cruise_Multi_Switch_2_FVTx 3;
BA_ "GenSigSendType" SG_ 150 HECSwtchB_2_Cs 1;
BA_ "GenSigSendType" SG_ 150 HECSwtchB_2_Cnt 1;
BA_ "GenSigSendType" SG_ 150 FuelLidOpen_Rq_SW_B_Actl 1;
BA_ "GenSigSendType" SG_ 150 TmpLoAlrmB_Actl 1;
BA_ "GenSigSendType" SG_ 150 HEC_HUD_Disp_MRCC_Status 1;
BA_ "GenSigSendType" SG_ 150 HEC_HUD_Disp_MRCC_Status2 1;
BA_ "GenSigInvalidValue" SG_ 150 SP_DATE_No 15;
BA_ "GenSigSendType" SG_ 150 SP_DATE_No 1;
BA_ "GenSigSendType" SG_ 150 PsunOfSw_B_Actl 1;
BA_ "GenSigSendType" SG_ 150 DposDrv2_B_Actl 1;
BA_ "GenSigSendType" SG_ 150 DposDrv1_B_Actl 1;
BA_ "GenSigSendType" SG_ 150 DposSet_B_Actl 1;
BA_ "GenSigSendType" SG_ 150 TLO_PLG_Sw_B_Actl 1;
BA_ "GenSigSendType" SG_ 150 IStpRexSw_B_Actl 1;
BA_ "GenSigSendType" SG_ 150 DSCOfSw_B_Actl 1;
BA_ "GenSigSendType" SG_ 150 PSM_OfSw_B_Actl 1;
BA_ "GenSigSendType" SG_ 150 TVMOfSw_B_Actl 1;
BA_ "GenSigSendType" SG_ 150 ADASOfSw_B_Actl 1;
BA_ "GenSigStartValue" SG_ 150 MultiSw_D_Qf 2;
BA_ "GenSigSendType" SG_ 150 MultiSw_D_Qf 1;
BA_ "GenSigSendType" SG_ 148 Cruise_Multi_Switch_1_MACTx 3;
BA_ "GenSigSendType" SG_ 148 Cruise_Multi_Switch_1_FVTx 3;
BA_ "GenSigSendType" SG_ 148 HECSwtchB_1_Cs 1;
BA_ "GenSigSendType" SG_ 148 HECSwtchB_1_Cnt 1;
BA_ "GenSigSendType" SG_ 148 DHS_RIL_STAT 1;
BA_ "GenSigStartValue" SG_ 148 RIL_STAT 1;
BA_ "GenSigSendType" SG_ 148 RIL_STAT 1;
BA_ "GenSigSendType" SG_ 148 MntSet_Oil_HEC_Req 1;
BA_ "GenSigSendType" SG_ 148 TJA_Swtch_B_Actl 1;
BA_ "GenSigSendType" SG_ 148 LIM_Swtch_B_Actl 1;
BA_ "GenSigSendType" SG_ 148 MRCC_Swtch_B_Actl 1;
BA_ "GenSigSendType" SG_ 148 ASC_Swtch_B_Actl 1;
BA_ "GenSigSendType" SG_ 148 DistanceMinus_B_Actl 1;
BA_ "GenSigSendType" SG_ 148 DistancePlus_B_Actl 1;
BA_ "GenSigSendType" SG_ 148 OffSwtch_B_Actl 1;
BA_ "GenSigSendType" SG_ 148 ResumeSwtch_B_Actl 1;
BA_ "GenSigSendType" SG_ 148 SetMinusSwtch_B_Actl 1;
BA_ "GenSigSendType" SG_ 148 SetPlusSwtch_B_Actl 1;
BA_ "GenSigSendType" SG_ 148 CancelSwtch_B_Actl 1;
BA_ "GenSigSendType" SG_ 148 CruiseSwtch_Qf 1;
BA_ "GenSigStartValue" SG_ 146 PADI_Stat 3;
BA_ "GenSigSendType" SG_ 146 PADI_Stat 3;
BA_ "GenSigSendType" SG_ 145 AEB_HEC_Fail_Flag 3;
BA_ "GenSigSendType" SG_ 145 Info_Status_B_Actl 3;
BA_ "GenSigSendType" SG_ 145 WiprTestMode_B_Actl 3;
BA_ "GenSigSendType" SG_ 145 SpAlarm_B_Actl 3;
BA_ "GenSigInvalidValue" SG_ 145 FrntWiprInt_V_Actl 255;
BA_ "GenSigStartValue" SG_ 145 FrntWiprInt_V_Actl 20;
BA_ "GenSigSendType" SG_ 145 FrntWiprInt_V_Actl 3;
BA_ "GenSigSendType" SG_ 145 PanelCont_D_Actl 3;
BA_ "GenSigSendType" SG_ 145 AvgFuelEco_Rst_HEC 3;
BA_ "GenSigSendType" SG_ 145 PaddleShiftDwn_D_Actl 3;
BA_ "GenSigSendType" SG_ 145 PaddleShiftUp_D_Actl 3;
BA_ "GenSigSendType" SG_ 145 RearWasherSw_B_Actl 3;
BA_ "GenSigSendType" SG_ 145 FrntWasherSw_B_Actl 3;
BA_ "GenSigSendType" SG_ 145 RearWiprStats_D_Actl 3;
BA_ "GenSigSendType" SG_ 145 FrntWiprStats_D_Actl 3;
BA_ "GenSigStartValue" SG_ 145 WiprSw_D_Qf 1;
BA_ "GenSigSendType" SG_ 145 ALH_HBC_Sw_B_Actl 3;
BA_ "GenSigSendType" SG_ 145 Mfs_Turn_Stalk_SW_Status 3;
BA_ "GenSigSendType" SG_ 145 PassngSw_B_Actl 3;
BA_ "GenSigSendType" SG_ 145 RearFogSw_B_Actl 3;
BA_ "GenSigSendType" SG_ 145 RSRmid_TmpOffReq 3;
BA_ "GenSigSendType" SG_ 145 HeadLghtHiSw_B_Actl 3;
BA_ "GenSigSendType" SG_ 145 HeadLghtLoSw_B_Actl 3;
BA_ "GenSigSendType" SG_ 145 TnsSw_B_Actl 3;
BA_ "GenSigStartValue" SG_ 145 LghtSw_D_Qf 1;
BA_ "GenSigInvalidValue" SG_ 137 VehYawComp_W_Actl_2_Echo 4095;
BA_ "GenSigStartValue" SG_ 137 VehYawComp_W_Actl_2_Echo 4094;
BA_ "GenSigInvalidValue" SG_ 136 SteerMtrCurrent_I_Actl_088 255;
BA_ "GenSigStartValue" SG_ 136 SteerMtrCurrent_I_Actl_088 127;
BA_ "GenSigInvalidValue" SG_ 136 ADAS_Eps_Final_Tq_Actl 8191;
BA_ "GenSigStartValue" SG_ 136 ADAS_Eps_Final_Tq_Actl 4095;
BA_ "GenSigInvalidValue" SG_ 136 ADAS_Lock2Lock_An_Const 1023;
BA_ "GenSigInvalidValue" SG_ 136 ADAS_Assist_Tq_Actl 8191;
BA_ "GenSigStartValue" SG_ 136 ADAS_Assist_Tq_Actl 4095;
BA_ "GenSigInvalidValue" SG_ 135 SteWhlComp_An_Est 32767;
BA_ "GenSigStartValue" SG_ 135 SteWhlComp_An_Est 32766;
BA_ "GenSigInvalidValue" SG_ 133 ADAS_SteCtlTrgt_AnV_Req 65535;
BA_ "GenSigStartValue" SG_ 133 ADAS_SteCtlTrgt_AnV_Req 32767;
BA_ "GenSigInvalidValue" SG_ 133 ADAS_SteCtlTrgt_An_Req 1048575;
BA_ "GenSigStartValue" SG_ 133 ADAS_SteCtlTrgt_An_Req 524287;
BA_ "GenSigInvalidValue" SG_ 132 SteAngReltv_An_Sns 32767;
BA_ "GenSigStartValue" SG_ 132 SteAngReltv_An_Sns 32766;
BA_ "GenSigStartValue" SG_ 132 SteAng_CalStart 1;
BA_ "GenSigInvalidValue" SG_ 130 SteWhlRelCalib_An_Sns 32767;
BA_ "GenSigStartValue" SG_ 130 SteWhlRelCalib_An_Sns 32766;
BA_ "GenSigStartValue" SG_ 128 Req_AEB_VRU_Acceleration 4000;
BA_ "GenSigStartValue" SG_ 126 Drive_Mode_Towing_Req_DSC 2;
BA_ "GenSigStartValue" SG_ 126 Drive_Mode_OffRoad_Req_DSC 2;
BA_ "GenSigStartValue" SG_ 126 Drive_Mode_Normal_Req_DSC 2;
BA_ "GenSigStartValue" SG_ 126 VacRelativePres 1000;
BA_ "GenSigInvalidValue" SG_ 126 VehYawComp_W_Actl_1 4095;
BA_ "GenSigStartValue" SG_ 126 VehYawComp_W_Actl_1 4094;
BA_ "GenSigInvalidValue" SG_ 125 VehYawComp_W_Actl_2 4095;
BA_ "GenSigStartValue" SG_ 125 VehYawComp_W_Actl_2 4094;
BA_ "GenSigStartValue" SG_ 124 VehLat_A_Actl 4000;
BA_ "GenSigStartValue" SG_ 124 VehLatAActl_D_Qf 1;
BA_ "GenSigInvalidValue" SG_ 123 BrkWhlPrs_A_Actl 767;
BA_ "GenSigStartValue" SG_ 123 BrkWhlPrs_A_Actl 766;
BA_ "GenSigInvalidValue" SG_ 123 BrkMstPrs_A_Actl2 767;
BA_ "GenSigStartValue" SG_ 123 BrkMstPrs_A_Actl2 766;
BA_ "GenSigStartValue" SG_ 123 BrktStkAActl_D_Qf 1;
BA_ "GenSigStartValue" SG_ 123 BrkStk_A_Actl 400;
BA_ "GenSigInvalidValue" SG_ 123 DriReqWhlTq_D_Actl 4095;
BA_ "GenSigStartValue" SG_ 123 DriReqWhlTq_D_Actl 4000;
BA_ "GenSigStartValue" SG_ 116 BrkMstAActl_D_Qf 1;
BA_ "GenSigStartValue" SG_ 116 BrkMstPrs_A_Actl 152;
BA_ "GenSigStartValue" SG_ 115 StopLamp_D_RqArb 1;
BA_ "GenSigStartValue" SG_ 115 VehLong_A_Actl 4000;
BA_ "GenSigStartValue" SG_ 115 VehLongAActl_D_Qf 1;
BA_ "GenSigSendType" SG_ 80 Clutch_Cut_Switch_Status 3;
BA_ "GenSigSendType" SG_ 80 SKE_IR_Request 3;
BA_ "GenSigInvalidValue" SG_ 80 SKE_SISS_Status 15;
BA_ "GenSigSendType" SG_ 80 SKE_SISS_Status 3;
BA_ "GenSigSendType" SG_ 80 SKE_SISS_Mode 3;
BA_ "GenSigSendType" SG_ 80 CrankStat_B_Actl 3;
BA_ "GenSigSendType" SG_ 80 AutoP_Request 3;
BA_ "GenSigSendType" SG_ 80 IG_OFF_Delay_State 3;
BA_ "GenSigSendType" SG_ 80 IG_mode 3;
BA_ "GenSigSendType" SG_ 80 PowerControlStatus 3;
BA_ "GenSigSendType" SG_ 74 RCMStatusMessage_2_MACTx 3;
BA_ "GenSigSendType" SG_ 74 RCMStatusMessage_2_FVTx 3;
BA_ "GenSigStartValue" SG_ 74 threshold_over_fst 2;
BA_ "GenSigSendType" SG_ 74 threshold_over_fst 1;
BA_ "GenSigSendType" SG_ 28 MACKVERI4_2 1;
BA_ "GenSigSendType" SG_ 28 MACKVERI4_1 1;
BA_ "GenSigSendType" SG_ 27 MACKVERI3_2 1;
BA_ "GenSigSendType" SG_ 27 MACKVERI3_1 1;
BA_ "GenSigSendType" SG_ 26 MACKVERI2_2 1;
BA_ "GenSigSendType" SG_ 26 MACKVERI2_1 1;
BA_ "GenSigSendType" SG_ 25 MACKVERI1_2 1;
BA_ "GenSigSendType" SG_ 25 MACKVERI1_1 1;
BA_ "GenSigSendType" SG_ 24 MACKUSAGE 1;
BA_ "GenSigSendType" SG_ 24 MACKID 1;
BA_ "GenSigSendType" SG_ 23 MACKSEND8_2 1;
BA_ "GenSigSendType" SG_ 23 MACKSEND8_1 1;
BA_ "GenSigSendType" SG_ 22 MACKSEND7_2 1;
BA_ "GenSigSendType" SG_ 22 MACKSEND7_1 1;
BA_ "GenSigSendType" SG_ 21 MACKSEND6_2 1;
BA_ "GenSigSendType" SG_ 21 MACKSEND6_1 1;
BA_ "GenSigSendType" SG_ 20 MACKSEND5_2 1;
BA_ "GenSigSendType" SG_ 20 MACKSEND5_1 1;
BA_ "GenSigSendType" SG_ 19 MACKSEND4_2 1;
BA_ "GenSigSendType" SG_ 19 MACKSEND4_1 1;
BA_ "GenSigSendType" SG_ 18 MACKSEND3_2 1;
BA_ "GenSigSendType" SG_ 18 MACKSEND3_1 1;
BA_ "GenSigSendType" SG_ 17 MACKSEND2_2 1;
BA_ "GenSigSendType" SG_ 17 MACKSEND2_1 1;
BA_ "GenSigSendType" SG_ 16 MACKSEND1_2 1;
BA_ "GenSigSendType" SG_ 16 MACKSEND1_1 1;
BA_REL_ "SC_Verification" BU_SG_REL_ CGW SG_ 832 RCMStatusMessage_MACTx 0;
BA_REL_ "SC_Verification" BU_SG_REL_ CGW SG_ 832 RCMStatusMessage_FVTx 0;
BA_REL_ "SC_Verification" BU_SG_REL_ DSC SG_ 831 crashoutput_brk_MACTx 0;
BA_REL_ "SC_Verification" BU_SG_REL_ DSC SG_ 831 crashoutput_brk_FVTx 0;
BA_REL_ "SC_Verification" BU_SG_REL_ CGW SG_ 830 crashoutput_MACTx 0;
BA_REL_ "SC_Verification" BU_SG_REL_ CGW SG_ 830 crashoutput_FVTx 0;
BA_REL_ "SC_Verification" BU_SG_REL_ CGW SG_ 570 EPAS_Info_MACTx 0;
BA_REL_ "SC_Verification" BU_SG_REL_ CGW SG_ 570 EPAS_Info_FVTx 0;
BA_REL_ "SC_Verification" BU_SG_REL_ DSC SG_ 542 ADAS_Longitudinal_Req_Pt_MACTx 0;
BA_REL_ "SC_Verification" BU_SG_REL_ DSC SG_ 542 ADAS_Longitudinal_Req_Pt_FVTx 0;
BA_REL_ "SC_Verification" BU_SG_REL_ DSC SG_ 532 ADAS_Longitudinal_Req_Brk_MACTx 0;
BA_REL_ "SC_Verification" BU_SG_REL_ DSC SG_ 532 ADAS_Longitudinal_Req_Brk_FVTx 0;
BA_REL_ "SC_Verification" BU_SG_REL_ DSC SG_ 531 AEB_Longitudinal_Req_Pt_MACTx 0;
BA_REL_ "SC_Verification" BU_SG_REL_ DSC SG_ 531 AEB_Longitudinal_Req_Pt_FVTx 0;
BA_REL_ "SC_Verification" BU_SG_REL_ DSC SG_ 530 AEB_Longitudinal_Req_Brk_MACTx 0;
BA_REL_ "SC_Verification" BU_SG_REL_ RCM SG_ 530 AEB_Longitudinal_Req_Brk_MACTx 0;
BA_REL_ "SC_Verification" BU_SG_REL_ DSC SG_ 530 AEB_Longitudinal_Req_Brk_FVTx 0;
BA_REL_ "SC_Verification" BU_SG_REL_ RCM SG_ 530 AEB_Longitudinal_Req_Brk_FVTx 0;
BA_REL_ "SC_Verification" BU_SG_REL_ CGW SG_ 520 DesiredTorqBrk_MACTx 0;
BA_REL_ "SC_Verification" BU_SG_REL_ RCM SG_ 520 DesiredTorqBrk_MACTx 0;
BA_REL_ "SC_Verification" BU_SG_REL_ CGW SG_ 520 DesiredTorqBrk_FVTx 0;
BA_REL_ "SC_Verification" BU_SG_REL_ RCM SG_ 520 DesiredTorqBrk_FVTx 0;
BA_REL_ "SC_Verification" BU_SG_REL_ DSC SG_ 515 EPB_info_1_MACTx 0;
BA_REL_ "SC_Verification" BU_SG_REL_ RCM SG_ 515 EPB_info_1_MACTx 0;
BA_REL_ "SC_Verification" BU_SG_REL_ ECB SG_ 515 EPB_info_1_MACTx 0;
BA_REL_ "SC_Verification" BU_SG_REL_ DSC SG_ 515 EPB_info_1_FVTx 0;
BA_REL_ "SC_Verification" BU_SG_REL_ RCM SG_ 515 EPB_info_1_FVTx 0;
BA_REL_ "SC_Verification" BU_SG_REL_ ECB SG_ 515 EPB_info_1_FVTx 0;
BA_REL_ "SC_Verification" BU_SG_REL_ CGW SG_ 187 WheelSpeed_Rear_MACTx 0;
BA_REL_ "SC_Verification" BU_SG_REL_ CGW SG_ 187 WheelSpeed_Rear_FVTx 0;
BA_REL_ "SC_Verification" BU_SG_REL_ CGW SG_ 186 WheelSpeed_Front_MACTx 0;
BA_REL_ "SC_Verification" BU_SG_REL_ CGW SG_ 186 WheelSpeed_Front_FVTx 0;
BA_REL_ "SC_Verification" BU_SG_REL_ CGW SG_ 152 WheelData_2_MACTx 0;
BA_REL_ "SC_Verification" BU_SG_REL_ RCM SG_ 152 WheelData_2_MACTx 0;
BA_REL_ "SC_Verification" BU_SG_REL_ CGW SG_ 152 WheelData_2_FVTx 0;
BA_REL_ "SC_Verification" BU_SG_REL_ RCM SG_ 152 WheelData_2_FVTx 0;
BA_REL_ "SC_Verification" BU_SG_REL_ CGW SG_ 151 WheelData_1_MACTx 0;
BA_REL_ "SC_Verification" BU_SG_REL_ CGW SG_ 151 WheelData_1_FVTx 0;
BA_REL_ "SC_Verification" BU_SG_REL_ DSC SG_ 150 Cruise_Multi_Switch_2_MACTx 0;
BA_REL_ "SC_Verification" BU_SG_REL_ DSC SG_ 150 Cruise_Multi_Switch_2_FVTx 0;
BA_REL_ "SC_Verification" BU_SG_REL_ RCM SG_ 148 Cruise_Multi_Switch_1_MACTx 0;
BA_REL_ "SC_Verification" BU_SG_REL_ RCM SG_ 148 Cruise_Multi_Switch_1_FVTx 0;
BA_REL_ "SC_Verification" BU_SG_REL_ RCM SG_ 146 BCM_Information1_MACTx 0;
BA_REL_ "SC_Verification" BU_SG_REL_ RCM SG_ 146 BCM_Information1_FVTx 0;
BA_REL_ "SC_Verification" BU_SG_REL_ CGW SG_ 135 EPAS_SAS_Info_2_MACTx 0;
BA_REL_ "SC_Verification" BU_SG_REL_ RCM SG_ 135 EPAS_SAS_Info_2_MACTx 0;
BA_REL_ "SC_Verification" BU_SG_REL_ CGW SG_ 135 EPAS_SAS_Info_2_FVTx 0;
BA_REL_ "SC_Verification" BU_SG_REL_ RCM SG_ 135 EPAS_SAS_Info_2_FVTx 0;
BA_REL_ "SC_Verification" BU_SG_REL_ CGW SG_ 132 EPAS_SAS_Info_1_MACTx 0;
BA_REL_ "SC_Verification" BU_SG_REL_ DSC SG_ 132 EPAS_SAS_Info_1_MACTx 0;
BA_REL_ "SC_Verification" BU_SG_REL_ CGW SG_ 132 EPAS_SAS_Info_1_FVTx 0;
BA_REL_ "SC_Verification" BU_SG_REL_ DSC SG_ 132 EPAS_SAS_Info_1_FVTx 0;
BA_REL_ "SC_Verification" BU_SG_REL_ DSC SG_ 128 FSC_AEBReq_Info_MACTx 0;
BA_REL_ "SC_Verification" BU_SG_REL_ RCM SG_ 128 FSC_AEBReq_Info_MACTx 0;
BA_REL_ "SC_Verification" BU_SG_REL_ DSC SG_ 128 FSC_AEBReq_Info_FVTx 0;
BA_REL_ "SC_Verification" BU_SG_REL_ RCM SG_ 128 FSC_AEBReq_Info_FVTx 0;
BA_REL_ "SC_Verification" BU_SG_REL_ CGW SG_ 125 YAW_Rate_Brake_Control_2_2_MACTx 0;
BA_REL_ "SC_Verification" BU_SG_REL_ CGW SG_ 125 YAW_Rate_Brake_Control_2_2_FVTx 0;
BA_REL_ "SC_Verification" BU_SG_REL_ CGW SG_ 124 YAW_Rate_Brake_Control_2_1_MACTx 0;
BA_REL_ "SC_Verification" BU_SG_REL_ CGW SG_ 124 YAW_Rate_Brake_Control_2_1_FVTx 0;
BA_REL_ "SC_Verification" BU_SG_REL_ CGW SG_ 116 YAW_Rate_Brake_Control_1_2_MACTx 0;
BA_REL_ "SC_Verification" BU_SG_REL_ CGW SG_ 116 YAW_Rate_Brake_Control_1_2_FVTx 0;
BA_REL_ "SC_Verification" BU_SG_REL_ CGW SG_ 115 YAW_Rate_Brake_Control_1_1_MACTx 0;
BA_REL_ "SC_Verification" BU_SG_REL_ CGW SG_ 115 YAW_Rate_Brake_Control_1_1_FVTx 0;
BA_REL_ "SC_Verification" BU_SG_REL_ CGW SG_ 114 RCM_Long_Acc_MACTx 0;
BA_REL_ "SC_Verification" BU_SG_REL_ DSC SG_ 114 RCM_Long_Acc_MACTx 0;
BA_REL_ "SC_Verification" BU_SG_REL_ CGW SG_ 114 RCM_Long_Acc_FVTx 0;
BA_REL_ "SC_Verification" BU_SG_REL_ DSC SG_ 114 RCM_Long_Acc_FVTx 0;
BA_REL_ "SC_Verification" BU_SG_REL_ CGW SG_ 113 RCM_Late_Acc_MACTx 0;
BA_REL_ "SC_Verification" BU_SG_REL_ DSC SG_ 113 RCM_Late_Acc_MACTx 0;
BA_REL_ "SC_Verification" BU_SG_REL_ CGW SG_ 113 RCM_Late_Acc_FVTx 0;
BA_REL_ "SC_Verification" BU_SG_REL_ DSC SG_ 113 RCM_Late_Acc_FVTx 0;
BA_REL_ "SC_Verification" BU_SG_REL_ CGW SG_ 112 RCM_Yaw_Rate_MACTx 0;
BA_REL_ "SC_Verification" BU_SG_REL_ DSC SG_ 112 RCM_Yaw_Rate_MACTx 0;
BA_REL_ "SC_Verification" BU_SG_REL_ CGW SG_ 112 RCM_Yaw_Rate_FVTx 0;
BA_REL_ "SC_Verification" BU_SG_REL_ DSC SG_ 112 RCM_Yaw_Rate_FVTx 0;
BA_REL_ "SC_Verification" BU_SG_REL_ CGW SG_ 74 RCMStatusMessage_2_MACTx 0;
BA_REL_ "SC_Verification" BU_SG_REL_ CGW SG_ 74 RCMStatusMessage_2_FVTx 0;
BA_REL_ "SC_Verification" BU_SG_REL_ DSC SG_ 32 CGW_Sync_MACTx 0;
BA_REL_ "SC_Verification" BU_SG_REL_ RCM SG_ 32 CGW_Sync_MACTx 0;
BA_REL_ "SC_Verification" BU_SG_REL_ EPAS SG_ 32 CGW_Sync_MACTx 0;
BA_REL_ "SC_Verification" BU_SG_REL_ FSC SG_ 32 CGW_Sync_MACTx 0;
VAL_ 960 HazardSw_D_Actl 0 "OFF" 1 "ON" 2 "Reserved" 3 "Unknown" ;
VAL_ 960 RearDef_B_Rq 0 "Rear defogger Off" 1 "Rear defogger On" ;
VAL_ 960 FrontDef_B_Rq 0 "Front defroster Off" 1 "Front defroster On" ;
VAL_ 960 PanelHeaterSwitchIn_RH 0 "Off" 1 "Low" 2 "Mid" 3 "High" 4 "Auto" ;
VAL_ 960 PanelHeaterSwitchIn_LH 0 "Off" 1 "Low" 2 "Mid" 3 "High" 4 "Auto" ;
VAL_ 960 SteeringHeaterSwitchIn 0 "Off" 1 "Low" 2 "Mid" 3 "High" 4 "Auto" ;
VAL_ 960 SeatVentilationSwitchIn_RH 0 "Off" 1 "Low" 2 "Mid" 3 "High" 4 "Auto" ;
VAL_ 960 SeatHeaterSwitchIn_RH 0 "Off" 1 "Low" 2 "Mid" 3 "High" 4 "Auto" ;
VAL_ 960 SeatVentilationSwitchIn_LH 0 "Off" 1 "Low" 2 "Mid" 3 "High" 4 "Auto" ;
VAL_ 960 SeatHeaterSwitchIn_LH 0 "Off" 1 "Low" 2 "Mid" 3 "High" 4 "Auto" ;
VAL_ 960 ipREARmode 0 "NotDefined" 1 "AUTO" 2 "REAR OFF" 3 "REAR ON" ;
VAL_ 960 ipECOmode 0 "NotDefined" 1 "AUTO" 2 "ECO OFF" 3 "ECO ON" ;
VAL_ 960 ipAImode 0 "NotDefined" 1 "AUTO" 2 "FRS" 3 "REC" 4 "REC025" 5 "REC050" 6 "REC075" ;
VAL_ 960 ipADmode 0 "NotDefined" 1 "Auto" 2 "Panel" 3 "B/L" 4 "Floor" 5 "D/F" 6 "DEF" ;
VAL_ 960 ipACmode 0 "NotDefined" 1 "AUTO" 2 "OFF" 3 "AC" 4 "AC-ECO" ;
VAL_ 960 ipBlwLvl 0 "NotDefined" 1 "AUTO" 2 "M0(OFF)" 3 "M1" 4 "M2" 5 "M3" 6 "M4" 7 "M5" 8 "M6" 9 "M7" ;
VAL_ 832 RCM_EDRtype 0 "Old_type" 1 "Standard_type" ;
VAL_ 832 ConnectedEDRTrigger 0 "Trigger off" 1 "Trigger on" 2 "Invalid" 3 "undefined" ;
VAL_ 832 DHS_RILReq 0 "RIL request=off" 1 "RIL check=on" 2 "RIL requested plant mode" 3 "RIL request=on" ;
VAL_ 832 FirstRowBucklePsngr 0 "passenger belt not used" 1 "passenger belt used" 2 "fault" 3 "reserve" ;
VAL_ 832 OCS_Status 0 "Unknown" 1 "Vacancy" 2 "Occupied" 3 "Malfunction" ;
VAL_ 832 PAD_Ind_Req 0 "AirbagOn_illum_Off_illum" 1 "AirbagOn_illum_Off_Not_illum" 2 "AirbagOn_Not_illum_Off_illum" 3 "Invalid" 4 "AirbagOn_Not_illum_Off_Not_illum" 5 "Reserved" ;
VAL_ 832 RILReq 0 "RIL Request=off" 1 "RIL check=on" 2 "RIL Requested plant mode" 3 "RILRequest=on" ;
VAL_ 831 RcmStat_B_Actl_brk 0 "Initializing" 1 "Normal" ;
VAL_ 831 threshold_ovr_rollover_brk 0 "normal(not_deploy)" 1 "faulty" 2 "threshold_over" 3 "not equiped" ;
VAL_ 831 threshold_ovr_rear_brk 0 "normal(not_deploy)" 1 "faulty" 2 "threshold_over" 3 "not equiped" ;
VAL_ 831 threshold_ovr_side_pass_brk 0 "normal(not_deploy)" 1 "faulty" 2 "threshold_over" 3 "not equiped" ;
VAL_ 831 threshold_ovr_side_Driver_brk 0 "normal(not_deploy)" 1 "faulty" 2 "threshold_over" 3 "not equiped" ;
VAL_ 831 threshold_ovr_front_brk 0 "normal(not_deploy)" 1 "faulty" 2 "threshold_over" 3 "not equiped" ;
VAL_ 830 threshold_over_rollover_static 0 "normal(not_deploy)" 1 "Faulty" 2 "Threshold_over" 3 "Not equiped" ;
VAL_ 830 RcmStat_B_Actl 0 "Initializing" 1 "Normal" ;
VAL_ 830 FuelCutoffReq 0 "Not equipped or Not cofigured" 5 "Unknown" 6 "Fuel_Enabled" 10 "Fuel_Disabled" 12 "Reserved" 15 "Invalid" ;
VAL_ 830 threshold_over_rollover 0 "normal(not_deploy)" 1 "faulty" 2 "threshold_over" 3 "not equiped" ;
VAL_ 830 threshold_over_rear 0 "normal(not_deploy)" 1 "faulty" 2 "threshold_over" 3 "not equiped" ;
VAL_ 830 threshold_over_side_passenger 0 "normal(not_deploy)" 1 "faulty" 2 "threshold_over" 3 "not equiped" ;
VAL_ 830 threshold_over_side_Driver 0 "normal(not_deploy)" 1 "faulty" 2 "threshold_over" 3 "not equiped" ;
VAL_ 830 threshold_over_front 0 "normal(not_deploy)" 1 "faulty" 2 "threshold_over" 3 "not equiped" ;
VAL_ 628 System_Check 0 "Off" 1 "Keyless System Check" ;
VAL_ 628 ABS_Tx_Request 0 "Tx Stop" 1 "Tx Continue" ;
VAL_ 628 Key_Not_Found 0 "OFF" 1 "Key not in interior" 2 "Key not in trunk" ;
VAL_ 628 Key_Battery_Low 0 "Normal" 1 "Low" ;
VAL_ 628 Power_Not_Off 0 "OFF" 1 "Power not off" ;
VAL_ 628 Shift_position_Display 0 "OFF" 1 "Shift lever is not in P" ;
VAL_ 628 Eng_start_Display 0 "OFF" 1 "Press brake and hold the key on " 2 "Press clutch and hold the key on" ;
VAL_ 628 Shift_lever_Display 0 "OFF" 1 "Shift lever to P" 2 "Shift lever to N" ;
VAL_ 628 ESCL_Display 0 "OFF" 1 "Steering Lock is not released Mo" ;
VAL_ 628 Press_pedal_Display 0 "OFF" 1 "Press brake pedal" 2 "Press clutch pedal" ;
VAL_ 628 Lamp_KEY_RED_Control 0 "Lamp OFF" 1 "Lamp ON" 2 "Lamp Time Limited Flash" 3 "Lamp Continuous Flash" ;
VAL_ 628 Lamp_KEY_GREEN_Control 0 "Lamp OFF" 1 "Lamp ON" 2 "Lamp Time Limited Flash" ;
VAL_ 570 Epas_ContStatus 0 "Normal" 1 "Initial Mode" 2 "unused" 3 "unused" 4 "unused" 5 "unused" 6 "unused" 7 "Failed" ;
VAL_ 552 ShiftOpeWarning_D_Rq 0 "No Request" 1 "Message1(Check)" 2 "Reserve" 3 "Message3(A_Pedal ON in N)" 4 "Message4(N-D/N-R Shift, Brake pl" 5 "Reserve" 6 "Reserve" 7 "Reserve" 10 "Message10(AutoP)" 11 "Message11(not AutoP lever to N)" 12 "Message12(not AutoP)" 13 "Message13(Shift into P)" 15 "Reserve" ;
VAL_ 552 ShiftPos_D_Act 0 "Initial Value" 1 "1st" 2 "2nd" 3 "3rd" 4 "4th" 5 "5th" 6 "6th" 7 "7th" 8 "8th" 9 "9th" 10 "Reserve" 11 "Neutral" 12 "Reverse" 13 "Park" 14 "Unknown Hex" 15 "Invalid Hex" ;
VAL_ 552 TransmChangeLeverPosition 0 "between 2 positions" 1 "P" 2 "R" 3 "N" 4 "D" 5 "M" 6 "Reserve" 7 "not used" 14 "Initial" 15 "Invalid" ;
VAL_ 552 DispAtLvrPos_ArrowReq 0 "No" 1 "Yes" ;
VAL_ 552 ShiftPos_D_Trg 0 "Initial Value" 1 "1st" 2 "2nd" 3 "3rd" 4 "4th" 5 "5th" 6 "6th" 7 "7th" 8 "8th" 9 "9th" 10 "Reserve" 11 "Neutral" 12 "Reverse" 13 "Park" 14 "Unknown Hex" 15 "Invalid Hex" ;
VAL_ 552 DispAtLvrPos_Off_Req 0 "No" 1 "Yes" ;
VAL_ 552 AT_INDLvl_D_Rq 0 "Off" 1 "Level1(MostSevere)" 2 "Level2(Severe)" 3 "Level3(NotSevere)" ;
VAL_ 552 AT_FailSafeLvl_D_Rq 0 "Off" 1 "not Reverse" 2 "Reserve" 3 "Reserve" ;
VAL_ 552 PwrDwn_D_Req_ByTCM 0 "No Request" 1 "Message A" 2 "Message B" 3 "Message C" ;
VAL_ 552 SBW_INDLvl_D_Rq 0 "No Request" 1 "Level1(MostSevere)" 2 "Level2(Severe)" 3 "Level3(NotSevere)" ;
VAL_ 552 ParkLockWarning_D_Rq 0 "No Request" 1 "Message1(No Parking)" 2 "Reserve" 3 "Reserve" ;
VAL_ 552 ShiftrPos_D_Qf 0 "Faulty" 1 "No data exists" 2 "Not within specifications" 3 "OK" ;
VAL_ 552 SbwWarningLamp_B_Rq 0 "No" 1 "Yes" ;
VAL_ 552 TransmParking_D_Act 0 "Initial" 1 "Park" 2 "not Park" 3 "between P and notP" 4 "Reserve" 7 "Invalid" ;
VAL_ 552 TrnSlaCtl_B_Rq 0 "No" 1 "Yes" ;
VAL_ 552 TrnSlaCtlFlag 0 "No" 1 "Yes" ;
VAL_ 552 TrnShifActv_B_Actl 0 "No" 1 "Yes" ;
VAL_ 552 AT_OILTEMPHi_D_Rq 0 "No Request" 1 "Level1(Speed)" 2 "Level2(Stop)" 3 "Level3(Brake)" ;
VAL_ 552 TrnCnvtClu_D_Actl 0 "No Lock Up" 1 "Lock Up Slip" 2 "Lock Up Fixed" 3 "Fault or Unknown" ;
VAL_ 552 DispGearPos_FlashReq 0 "Off" 1 "On" ;
VAL_ 552 OD_Hold_Sport_Flash 0 "Off" 1 "On" ;
VAL_ 552 DispAtLvrPos_FlashReq 0 "Off" 1 "On" ;
VAL_ 552 DispAtLvrPos_D_Rq 0 "turn off(b2p)" 1 "P" 2 "R" 3 "N" 4 "D" 5 "DM" 6 "M" 7 "Reserve" 8 "Reserve" 14 "Initial/Unknown" 15 "Invalid" ;
VAL_ 552 DispGearPos_D_Rq 0 "turn off" 1 "1st" 2 "2nd" 3 "3rd" 4 "4th" 5 "5th" 6 "6th" 7 "7th" 8 "8th" 9 "9th" 10 "10th" 11 "11th" 12 "12th" 13 "Reserve" 14 "Initial /Unknown" 15 "Invalid" ;
VAL_ 547 AEB_DSC_Fail_Flag 0 "Off" 1 "On" ;
VAL_ 547 ADAS_Hold_Available_Flag 0 "Not Available" 1 "Available" ;
VAL_ 547 ADAS_StopLamp_Fail_Flag 0 "Off" 1 "On" ;
VAL_ 547 ADAS_DSC_Fail_Flag 0 "Off" 1 "On" ;
VAL_ 547 ADAS_Decel_Inhibit_Flag 0 "Off" 1 "On" ;
VAL_ 547 ADAS_Brake_Flag 0 "Off" 1 "On" ;
VAL_ 546 ADAS_PT_Fail_Flag 0 "Off" 1 "On" ;
VAL_ 546 AEB_PT_Fail_Flag 0 "Off" 1 "On" ;
VAL_ 546 ADAS_Accel_Inhibit_Flag 0 "Off" 1 "On" ;
VAL_ 546 Request_ADAS_B_Flag 0 "Off" 1 "On" ;
VAL_ 546 PT_State_ADAS 0 "Pedal" 1 "Cruise" 2 "Cruise_OR" 3 "Limiter" 4 "Limiter(Emergency)" ;
VAL_ 543 Left_Lane_Color 0 "not detected" 1 "white" 2 "yellow" 3 "blue" 4 "undecided" ;
VAL_ 543 Right_Lane_Color 0 "not detected" 1 "white" 2 "yellow" 3 "blue" 4 "undecided" ;
VAL_ 543 InterVehicular_Distance 0 "not detected" 1 "long" 2 "middle" 3 "short" 4 "very short" ;
VAL_ 543 ADAS_Brake_Inhibit 0 "Off" 1 "On" ;
VAL_ 543 ASC_mode 0 "Off" 1 "VS_CONTROL" 2 "ACCEL" 3 "DECEL" 4 "TAP UP" 5 "TAP DOWN" 6 "RESUME HIGH" 7 "RESUME LOW" ;
VAL_ 543 ADAS_Cancel_Control_Flag 0 "Not Cancel Control" 1 "Cancel Control" ;
VAL_ 543 ADAS_Start_Control_Flag 0 "No Request" 1 "Start Control" ;
VAL_ 543 ADAS_Stop_Control_Flag 0 "No Request" 1 "Stop Control" ;
VAL_ 542 Request_ADAS_Set_Flag 0 "Off" 1 "On" ;
VAL_ 542 ADAS_Types_pt 0 "Normal" 1 "ASC" 2 "MRCC" 3 "TJA(MRCC+LKA)" 4 "EDA" 10 "MSA/ISA" 11 "DSA" ;
VAL_ 537 WhlRotatRl_Direction 0 "Unknown" 1 "Forward" 2 "Backward" 3 "Fault" ;
VAL_ 537 WhlRotatRr_Direction 0 "Unknown" 1 "Forward" 2 "Backward" 3 "Fault" ;
VAL_ 537 WhlRotatFl_Direction 0 "Unknown" 1 "Forward" 2 "Backward" 3 "Fault" ;
VAL_ 537 WhlRotatFr_Direction 0 "Unknown" 1 "Forward" 2 "Backward" 3 "Fault" ;
VAL_ 532 EPB_ExternalApply_D_Rq_VCM 0 "No request" 1 "not used" 2 "not used" 3 "Request" ;
VAL_ 532 ADAS_DSC_Request_ON_Flag 0 "No Request" 1 "DSC On Request" ;
VAL_ 532 ADAS_Hold_Release_Request_Flag 0 "No Request" 1 "Hold Release Request" ;
VAL_ 532 ADAS_Hold_Request_Flag 0 "No Request" 1 "Hold Request" ;
VAL_ 532 ADAS_Stop_Request_Flag 0 "No Request" 1 "Soft Stop Control" ;
VAL_ 532 ADAS_Types_brk 0 "Normal" 1 "ASC" 2 "MRCC" 3 "TJA(MRCC+LKA)" 4 "EDA" 10 "MSA/ISA" 11 "DSA" ;
VAL_ 531 Request_AEB_Set_Flag 0 "Off" 1 "On" ;
VAL_ 531 AEB_Types_pt 0 "Normal" 1 "AEB" 2 "R-AEB" ;
VAL_ 531 AEB_Fail_Flag_Pt 0 "Not Fail" 1 "Fail" ;
VAL_ 530 AEB_Fail_Flag_Brk 0 "Not Fail" 1 "Fail" ;
VAL_ 530 AEB_Warning_Jerk_Flag 0 "Off" 1 "On" ;
VAL_ 530 AEB_Prefill_Level 0 "Normal" 1 "Level_1" 2 "Level_2" 3 "Level_3" ;
VAL_ 530 AEB_BA_Level 0 "Normal" 1 "Level_1" 2 "Level_2" 3 "Level_3" ;
VAL_ 530 Request_AEB_B_Flag 0 "Off" 1 "On" ;
VAL_ 530 AEB_Types_brk 0 "Normal" 1 "AEB" 2 "R-AEB" ;
VAL_ 520 ADAS_Brake_Flag_copy 0 "Off" 1 "On" ;
VAL_ 520 Abs_B_Falt 0 "No" 1 "Yes" ;
VAL_ 520 TsaCtlActv_B_Actl 0 "No" 1 "Yes" ;
VAL_ 520 RolStabCtlActv_B_Actl 0 "No" 1 "Yes" ;
VAL_ 520 PrplDrgCtlActv_B_Actl 0 "Inactive" 1 "Active" ;
VAL_ 520 TracCtlPtActv_B_Actl 0 "No" 1 "Yes" ;
VAL_ 520 TracCtlBrkActv_B_Actl 0 "No" 1 "Yes" ;
VAL_ 520 DSC_OnOff_status_1 0 "ON" 1 "OFF" ;
VAL_ 520 StabCtlBrkActv_B_Actl 0 "No" 1 "Yes" ;
VAL_ 520 BrkAsst_B_Actl 0 "No" 1 "Yes" ;
VAL_ 520 AbsActv_B_Actl 0 "No" 1 "Yes" ;
VAL_ 520 EbdActv_B_Actl 0 "No" 1 "Yes" ;
VAL_ 515 EPB_DisplayRequest5_RCM 0 "EPB is in maitenance mode OFF" 1 "EPB is in maitenance mode ON" ;
VAL_ 515 EPB_DisplayRequest4_RCM 0 "P brake is not available OFF" 1 "P brake is not available ON" ;
VAL_ 515 EPB_DisplayRequest3_RCM 0 "System inspection rq OFF" 1 "System inspection rq ON" ;
VAL_ 515 EPB_Status_sa 0 "Released" 1 "Applied" 2 "In operation (applying/releasing" 3 "Waiting for operating" 4 "Unknown" ;
VAL_ 515 EPB_SwitchPosition_sa 0 "No request" 1 "Release request" 2 "Apply request" 3 "Error" ;
VAL_ 515 EPB_EnableExternalApply_DSC 0 "Not enable" 1 "Enable" ;
VAL_ 515 EPB_EnableDecelRequest_sa 0 "Not enable" 1 "Enable" ;
VAL_ 514 ApedPosPcActl_D_Qf 0 "Faulty" 1 "NoDataExist" 2 "NotWithinSpecification" 3 "OK" ;
VAL_ 514 DcdcWarningDisp_B_Rq_202 0 "Off" 1 "On" ;
VAL_ 514 EngAout_D_ReqTachoGain 0 "Normal" 1 "gain_1" 2 "gain_2" 3 "gain_3" ;
VAL_ 357 VehVLim_Warning 0 "Off" 1 "On" ;
VAL_ 357 AirCondRec_B_Rq 0 "OFF" 1 "ON" ;
VAL_ 357 AWD_State_Req_165 0 "Stop" 1 "MODE2" 2 "MODE3" 3 "System_Start" 4 "System_Stop" 5 "OFF" 6 "MODE6" 7 "MODE7" 8 "MODE8" 9 "MODE9" 10 "MODE10" 11 "MODE11" 12 "MODE12" 13 "MODE13" 14 "MODE14" 15 "MODE15" ;
VAL_ 357 VehVLim_OverVS_KD 0 "not Over Speed Condition with K/" 1 "Over Speed Condition with K/D" ;
VAL_ 357 NeutralSwActv_D_Actl 0 "Unknown, default value" 1 "not Neutral" 2 "Neutral" 3 "Invalid" ;
VAL_ 357 GearPos_D_TrgMt 0 "Park/Neutral" 1 "1st" 2 "2nd" 3 "3rd" 4 "4th" 5 "5th" 6 "6th" 7 "7th" 8 "8th" 14 "Reverse" 15 "Unknown" ;
VAL_ 357 GearRvrseActv_B_Actl 0 "Off" 1 "On" ;
VAL_ 357 BrkOnOffSwtch_D_Actl_2 0 "not allowed" 1 "driver not braking" 2 "driver braking" 3 "not allowed" ;
VAL_ 304 PTiStpRdy_B_Actl 0 "Not ready" 1 "Ready" ;
VAL_ 304 iStpDenyBrk_B_Actl 0 "OFF" 1 "ON" ;
VAL_ 304 iStpDenyPwStr_B_Actl 0 "OFF" 1 "ON" ;
VAL_ 304 iStpKeySta_B_Actl 0 "OFF" 1 "ON" ;
VAL_ 304 iStpDenyAC_B_Actl 0 "OFF" 1 "ON" ;
VAL_ 304 iStpDenyNrange_B_Actl 0 "OFF" 1 "ON" ;
VAL_ 304 iStpDenyDPF_B_Actl 0 "OFF" 1 "ON" ;
VAL_ 304 ELM_IRCutReq 0 "No" 1 "Yes" ;
VAL_ 304 BatteryWeakenFlag 0 "OFF" 1 "ON" ;
VAL_ 304 iStpDoorOpen_B_Actl 0 "No" 1 "Yes" ;
VAL_ 304 SISS_EngineState 1 "Ready" 2 "Key Cranking" 3 "Engine Running" 5 "ISS engine stop condition have b" 6 "ISS engine stopping" 7 "ISS engine stopped" 8 "ISS engine restart ready" 9 "ISS engine restarting" 10 "ISS engine running" ;
VAL_ 304 SISS_IRCutReq 0 "No" 1 "Yes" ;
VAL_ 304 SKE_Control 0 "Not_Request" 1 "Request_IS" 2 "Request_IR" ;
VAL_ 304 SISS_Mode_for_SKE 0 "OFF" 1 "ON" ;
VAL_ 304 iStpReady_Rq 0 "Not Ready" 1 "Ready" ;
VAL_ 304 iStpDenyBatt_B_Actl 0 "OFF" 1 "ON" ;
VAL_ 304 SlaCtl_B_Rq 0 "Not Request for SLA Activation" 1 "Request for SLA Activation" ;
VAL_ 304 SISS_WarningLamp_R 0 "OFF" 1 "Pattern1" 2 "Pattern2" 3 "Pattern3" 4 "Pattern4" 5 "Pattern5" ;
VAL_ 304 SISS_WarningLamp_G 0 "OFF" 1 "Pattern1" 2 "Pattern2" 3 "Pattern3" 4 "Pattern4" 5 "Pattern5" ;
VAL_ 304 SISS_AlarmBuzzer 0 "OFF" 1 "Pattern1" 2 "Pattern2" 3 "Pattern3" 4 "Pattern4" ;
VAL_ 304 SISSStatus 0 "Normal Status" 1 "Idle Stop Enst Status" ;
VAL_ 304 SrlyUpper_Connect_Rq 0 "Unknown,default" 1 "Disconnect Request" 2 "Connect Request" ;
VAL_ 253 Xev_Charge_Req_PCM 0 "NG" 1 "OK" 2 "NG_ACC" 3 "reserved" 6 "Not Determined" 7 "Invalid" ;
VAL_ 253 PTGeneralWarn_Mirror 0 "ON" 1 "OFF" ;
VAL_ 253 Drive_Mode_Req_PCM 0 "Normal(NG)/Sports(NG)/3rd(NG)/4t" 1 "Normal(OK)/Sports(NG)/3rd(NG)/4t" 2 "Normal(NG)/Sports(OK)/3rd(NG)/4t" 3 "Normal(OK)/Sports(OK)/3rd(NG)/4t" 4 "Normal(NG)/Sports(NG)/3rd(OK)/4t" 5 "Normal(OK)/Sports(NG)/3rd(OK)/4t" 6 "Normal(NG)/Sports(OK)/3rd(OK)/4t" 7 "Normal(OK)/Sports(OK)/3rd(OK)/4t" 8 "Normal(NG)/Sports(NG)/3rd(NG)/4t" 9 "Normal(OK)/Sports(NG)/3rd(NG)/4t" 10 "Normal(NG)/Sports(OK)/3rd(NG)/4t" 11 "Normal(OK)/Sports(OK)/3rd(NG)/4t" 12 "Normal(NG)/Sports(NG)/3rd(OK)/4t" 13 "Normal(OK)/Sports(NG)/3rd(OK)/4t" 14 "Normal(NG)/Sports(OK)/3rd(OK)/4t" 15 "Normal(OK)/Sports(OK)/3rd(OK)/4t" ;
VAL_ 253 Drive_Mode_Towing_Req_PCM 0 "NG" 1 "OK" 2 "Not Determined" 3 "Invalid" ;
VAL_ 253 Drive_Mode_OffRoad_Req_PCM 0 "NG" 1 "OK" 2 "Not Determined" 3 "Invalid" ;
VAL_ 253 Drive_Mode_Sport_Req_PCM 0 "NG" 1 "OK" 2 "Not Determined" 3 "Invalid" ;
VAL_ 253 Drive_Mode_Normal_Req_PCM 0 "NG" 1 "OK" 2 "Not Determined" 3 "Invalid" ;
VAL_ 253 ATFalseStartWarning 0 "Off" 1 "On" ;
VAL_ 253 BattRgenStat_B_Actl 0 "OFF" 1 "ON" ;
VAL_ 253 RegenBrkFailWarning 0 "OFF" 1 "ON" ;
VAL_ 253 BmsWarn_B_Rq 0 "OFF" 1 "ON" ;
VAL_ 253 SmtAclInh_B_Actl 0 "OFF" 1 "ON" ;
VAL_ 253 BrakeSw_Fail_Warning 0 "Brake switch Normal" 1 "Brake switch Failure" ;
VAL_ 253 BOS_Active_B_Actl 0 "NotActivated" 1 "Activated" ;
VAL_ 253 DriveMode_Hold_Rq_PCM 0 "OFF" 1 "ON" ;
VAL_ 253 GlobalConfgWarn_B_Rq 0 "OFF" 1 "ON" ;
VAL_ 253 ApedOnN_B_Rq 0 "OFF" 1 "ON" ;
VAL_ 253 IG_OFF_Delay_Request 0 "OFF" 1 "ON" ;
VAL_ 253 Crank_wait 0 "No wait, default" 1 "Wait to crank" ;
VAL_ 253 SilGearPosActl_D_Dsply 0 "Off" 1 "1st" 2 "2nd" 3 "3rd" 4 "4th" 5 "5th" 6 "6th" 7 "7th" 8 "8th" 9 "Circuit Check at IG ON" ;
VAL_ 253 Xev_Ev_Req_PCM 0 "NG" 1 "OK" 2 "NG_ACC" 3 "reserved" 6 "Not Determined" 7 "Invalid" ;
VAL_ 253 VspLmtAlarm_B_Rq 0 "OFF" 1 "ON" ;
VAL_ 253 PTGeneralWarn_B_Rq 0 "OFF" 1 "ON" ;
VAL_ 253 SRLY_state 0 "OFF(inactive), default" 1 "ON(active)" ;
VAL_ 253 SilGearPos_D_Dsply 0 "Off" 1 "1st" 2 "2nd" 3 "3rd" 4 "4th" 5 "5th" 6 "6th" 7 "7th" 8 "8th" 9 "Circuit Check at IG ON" ;
VAL_ 253 VspLmtWarn_B_Rq 0 "OFF" 1 "vsplmtwarn1" 2 "vsplmtwarn2" 3 "Not defined" ;
VAL_ 253 KeyState 0 "Unknown-default(From Igon to com" 1 "Disable_Crank" 2 "Enable_Crank (including iSTOP/En" 3 "Running" 4 "Invalid" 5 "Invalid" 6 "Shutdown(PCM== Igoff condition)" 7 "Invalid" ;
VAL_ 253 ShiftIndicatorLight 0 "Off" 1 "Up Shift" 2 "Down Shift" 3 "Circuit Check at IG ON" ;
VAL_ 253 PowerSourceStatus 0 "Off" 1 "Standby" 2 "Startup" 3 "Ready-ON" 4 "Inhibit" ;
VAL_ 192 Auto_XevNormal_Mode_D_Rq 0 "OFF" 1 "Ev_Mode_Malfunction" 2 "Ev_Mode_ACC" 3 "EV_Cancel_General" 4 "Charge_Mode_Malfunction" 5 "Charge_Mode_ACC" 6 "Charge_Cancel_General" 7 "reserved" ;
VAL_ 192 Not_Select_Xevmode_D_Rq 0 "OFF" 1 "ALL_Mode_Malfunction" 2 "Mode_ACC" 3 "ALL_Mode_Temporarily" 4 "CHARGE_Mode_Malfunction" 5 "CHARGE_Mode_Temporarily" 6 "reserved" 7 "reserved" ;
VAL_ 192 Auto_Normal_Mode_D_Rq 0 "OFF" 1 "ALL_Mode_Malfunction" 2 "Sport_Mode_ACC" 3 "Cancel_General" 4 "reserved" 5 "reserved" 6 "reserved" 7 "reserved" ;
VAL_ 192 Not_Select_Drivemode_D_Rq 0 "OFF" 1 "ALL_Mode_Malfunction" 2 "Sport_Mode_ACC" 3 "ALL_Mode_Temporarily" 4 "Towing_Mode_Not_Detect" 5 "reserved" 6 "reserved" 7 "reserved" ;
VAL_ 192 Trailer_Connect_D_Rq 0 "OFF" 1 "Trailer Connected" 2 "ADAS Partially_Towing Mode" 3 "ADAS Partially" 4 "ADAS Rear_Towing Mode" 5 "ADAS Rear" 6 "reserved" 7 "reserved" ;
VAL_ 192 Drive_Mode_List_Popup 0 "Off" 1 "List_Popup" 2 "Limit_Upper" 3 "Limit_Lower" 4 "List_Popup_Normal" 5 "List_Popup_Sport" 6 "List_Popup_Offroad" 7 "List_Popup_Towing" 8 "List_Popup_EV" 9 "reserved" 10 "reserved" 11 "reserved" 12 "reserved" 13 "reserved" 14 "reserved" 15 "Invalid" ;
VAL_ 192 Xev_Mode_Charge_Permission 0 "OK" 1 "NG" 2 "Not_Determined" 3 "Invalid" ;
VAL_ 192 Xev_Mode_Ev_Permission 0 "OK" 1 "NG" 2 "Not_Determined" 3 "Invalid" ;
VAL_ 192 Xev_Mode_Status 0 "Normal mode" 1 "Ev mode" 2 "Charge mode" 3 "reserved" 14 "Not_Determined" 15 "Invalid" ;
VAL_ 192 Drive_Mode_Towing_Permission 0 "OK" 1 "NG" 2 "Not_Determined" 3 "Invalid" ;
VAL_ 192 Drive_Mode_Offroad_Permission 0 "OK" 1 "NG" 2 "Not_Determined" 3 "Invalid" ;
VAL_ 192 Drive_Mode_Sport_Permission 0 "OK" 1 "NG" 2 "Not_Determined" 3 "Invalid" ;
VAL_ 192 Drive_Mode_Normal_Permission 0 "OK" 1 "NG" 2 "Not_Determined" 3 "Invalid" ;
VAL_ 192 Drive_Mode_List_Info 0 "NORMAL/NONE" 1 "SPORT_NORMAL" 2 "SPORT_NORMAL_OFFROAD" 3 "TOWING_SPORT_NORMAL_OFFROAD" 4 "NORMAL+OFFROAD" 5 "TOWING_NORMAL+OFFROAD" 6 "CHARGE_NORMAL_EV" 7 "TOWING_SPORT_NORMAL_EV_OFFROAD" 8 "SPORT_NORMAL_EV_OFFROAD" 9 "reserved" 10 "reserved" 11 "reserved" 12 "reserved" 13 "reserved" 14 "Not_Determined" 15 "Invalid" ;
VAL_ 192 Drive_Mode_Status 0 "Normal mode" 1 "Sport mode" 2 "Offroad mode" 3 "Towing mode" 4 "EV mode" 5 "reserved" 6 "reserved" 7 "reserved" 8 "reserved" 9 "reserved" 10 "reserved" 11 "reserved" 12 "reserved" 13 "reserved" 14 "Not_Determined" 15 "Invalid" ;
VAL_ 159 BpedDrvAppl_D_Actl 0 "not allowed" 1 "driver not braking" 2 "driver braking" 3 "not allowed" ;
VAL_ 159 IndirectIllumination_D_Rq 0 "Unknown" 1 "0%Fade out" 2 "100%Fade in" 3 "KINDIRECTILLUMRATE_DARK% Fade" 4 "KINDIRECTILLUMRATE_MEDIUM% Fade" 5 "KINDIRECTILLUMRATE_BLIGHT% Fade" ;
VAL_ 159 WelcomIllumination_D_Rq 0 "Unknown" 1 "0%Fade out" 2 "100%Fade in" 3 "KWELCOMLLUMRATE% Fade" ;
VAL_ 159 FootLamp_D_Rq 0 "Unknown" 1 "0%Fade out" 2 "100%Fade in" 3 "KFOOTLAMPRATE_DARK%Fade" 4 "KFOOTLAMPRATE_MEDIUM% Fade" 5 "KFOOTLAMPRATE_BLIGHT% Fade" ;
VAL_ 159 DoorCourtesyLamp_D_Rq 0 "Unknown" 1 "0%Fade out" 2 "100%Fade in" ;
VAL_ 159 CargoLamp_D_Rq 0 "Unknown" 1 "0%Fade out" 2 "100%Fade in" ;
VAL_ 159 DimmerCancel 0 "Unknown" 1 "OFF" 2 "ON" ;
VAL_ 159 Drive_Mode_FlashReq 0 "Off" 1 "3times_Start(400msOn/Off)" 2 "On" ;
VAL_ 159 Drive_Mode_Enabled 0 "Normal mode" 1 "Sports mode" 2 "3rd mode" 3 "4th mode" ;
VAL_ 159 CarMde_D_Actl 0 "Normal" 1 "Factory" 2 "Not Used" 3 "Transport" 4 "Not Used" 5 "Not Used" ;
VAL_ 159 Reverselamp_B_Req 0 "OFF" 1 "ON" ;
VAL_ 159 IlumiMde_D_Actl 0 "Unknown" 1 "OFF, daylight mode" 2 "ON, night mode" ;
VAL_ 159 Illum_PowerControlStatus 0 "OFF" 1 "ON" ;
VAL_ 159 AudioMute_B_Actl 0 "Off" 1 "On" ;
VAL_ 159 RoomFuseStat_D_Actl 0 "Without Room Fuse" 1 "With Room Fuse" 2 "Unused" 3 "Unknown" ;
VAL_ 154 SndRSP_Fail_B_Actl 0 "Off" 1 "On" ;
VAL_ 154 SndFSP_Fail_B_Actl 0 "Off" 1 "On" ;
VAL_ 154 Hazard_lamp_State_D_Actl 0 "Manual Hazard Off" 1 "Manual Hazard On" ;
VAL_ 154 DRL_Tail_Lamp_B_Rq 0 "Off" 1 "On" ;
VAL_ 154 TNS_Buzzer_Cntl_Req 0 "Off" 1 "On" ;
VAL_ 154 Turn_Snd_Cmd_Left 0 "Off" 1 "On" ;
VAL_ 154 Turn_Snd_Cmd_Right 0 "Off" 1 "On" ;
VAL_ 154 WiprGuid_B_Rq 0 "Off" 1 "On" ;
VAL_ 154 BurglarHorn_B_Req 0 "Off" 1 "On" ;
VAL_ 154 RSRmid_Indicator_Req 0 "OFF" 1 "ON at IG On" 2 "ON at IG On Extension" 3 "ON at IG Off" ;
VAL_ 154 RSRmid_DisplayReq 0 "Not Request" 1 "Request Arming" 2 "Request Alert" 3 "Request Completed" ;
VAL_ 154 BlwCont_B_Actl 0 "Blow Motor Relay OFF" 1 "Blow Motor Relay ON" ;
VAL_ 154 FrntWipr_D_Actl 0 "OFF" 1 "Front Wiper Lo ON" 2 "Front Wiper Hi ON" ;
VAL_ 154 SteeringHeatCutLvl 0 "NoRequest" 1 "CutRequestWithIndicatorOn" 2 "CutRequestWithIndicatorOff" 3 "Reserved" ;
VAL_ 154 PtcCutLvl 0 "NoRequest" 1 "CutRequestWithIndicatorOn" 2 "CutRequestWithIndicatorOff" 3 "Reserved" ;
VAL_ 154 BmotCutLvl 0 "NoRequest" 1 "CutRequestWithIndicatorOn" 2 "CutRequestWithIndicatorOff" 3 "Reserved" ;
VAL_ 154 SeatHeatCutLvl 0 "NoRequest" 1 "CutRequestWithIndicatorOn" 2 "CutRequestWithIndicatorOff" 3 "Reserved" ;
VAL_ 154 RdefCutLvl 0 "NoRequest" 1 "CutRequestWithIndicatorOn" 2 "CutRequestWithIndicatorOff" 3 "Reserved" ;
VAL_ 154 SeatVentCutLvl 0 "NoRequest" 1 "CutRequestWithIndicatorOn" 2 "CutRequestWithIndicatorOff" 3 "Reserved" ;
VAL_ 154 WshrLvl_D_Actl 0 "Unknown" 1 "Normal" 2 "Low" 3 "Invalid" ;
VAL_ 154 TNS_IpcDsply_D_Rq 0 "OFF" 1 "Green ON" 2 "Reserved (Yellow ON)" 3 "Reserved" ;
VAL_ 154 Turn_Ind_Cmd_Left 0 "OFF" 1 "ON" ;
VAL_ 154 Turn_Ind_Cmd_Right 0 "OFF" 1 "ON" ;
VAL_ 154 Turnlamp_ESS_B_Req 0 "OFF" 1 "ON" ;
VAL_ 154 Turnlamp_KoDo_B_Req 0 "OFF" 1 "ON" ;
VAL_ 154 LightWarning_D_Rq 0 "OFF" 1 "System check" 2 "Flashing 2Hz" 3 "Flashing 3 times" 7 "Yellow ON (Fail)" ;
VAL_ 154 ResHeatCont_B_Actl 0 "No request" 1 "Requested" ;
VAL_ 154 ResEngCont_B_Actl 0 "Remote Start Off" 1 "Remote Start On" ;
VAL_ 154 CBDA_Sleep_B_Rq 0 "uC Sleep mode" 1 "uC Wakeup mode" ;
VAL_ 154 RearWiprLo_B_Rq 0 "Off" 1 "Rear Wiper Lo On" 2 "Stop" ;
VAL_ 154 AutoWiprIND_B_Rq 0 "OFF" 1 "ON" ;
VAL_ 154 RearFogIpcDsply_B_Rq 0 "OFF" 1 "Yellow ON" ;
VAL_ 154 HiBeamIpcDsply_B_Rq 0 "No Request" 1 "On Request" ;
VAL_ 152 Vehicle_Stationary 0 "Not stationary" 1 "Stationary" 2 "Unknown" 3 "Fault" ;
VAL_ 152 VehVActlBrk_D_Qf 0 "Faulty" 1 "No_Data_Exists" 2 "Not_Within_Specifications" 3 "OK" ;
VAL_ 150 FuelLidOpen_Rq_SW_B_Actl 0 "No Request" 1 "Open Request" ;
VAL_ 150 TmpLoAlrmB_Actl 0 "Off" 1 "On" ;
VAL_ 150 HEC_HUD_Disp_MRCC_Status 0 "Not Allowed" 1 "Allowed" ;
VAL_ 150 HEC_HUD_Disp_MRCC_Status2 0 "Not Allowed" 1 "Allowed" ;
VAL_ 150 SP_DATE_No 0 "SP No_1" 1 "SP No_2" 2 "SP No_3" 3 "SP No_4" 4 "SP No_5" 5 "SP No_6" 6 "SP No_7" 7 "SP No_8" 8 "SP No_9" 9 "SP No_10" 10 "SP No_11" 11 "SP No_12" 12 "SP No_13" 13 "SP No_14" 14 "SP No_15" 15 "Invalid" ;
VAL_ 150 PsunOfSw_B_Actl 0 "Off" 1 "On" ;
VAL_ 150 DposDrv2_B_Actl 0 "Off" 1 "On" ;
VAL_ 150 DposDrv1_B_Actl 0 "Off" 1 "On" ;
VAL_ 150 DposSet_B_Actl 0 "Off" 1 "On" ;
VAL_ 150 TLO_PLG_Sw_B_Actl 0 "Off" 1 "On" ;
VAL_ 150 IStpRexSw_B_Actl 0 "Off" 1 "On" ;
VAL_ 150 DSCOfSw_B_Actl 0 "Off" 1 "On" ;
VAL_ 150 PSM_OfSw_B_Actl 0 "Off" 1 "On" ;
VAL_ 150 TVMOfSw_B_Actl 0 "Off" 1 "On" ;
VAL_ 150 ADASOfSw_B_Actl 0 "Off" 1 "On" ;
VAL_ 150 MultiSw_D_Qf 0 "Faulty" 1 "Undefined" 2 "Not within Specification" 3 "OK" ;
VAL_ 148 DHS_RIL_STAT 0 "Off" 1 "On" 2 "Plant_Mode" 3 "Fault" 4 "Unknown" 5 "Reserved" ;
VAL_ 148 RIL_STAT 0 "Off" 1 "On" 2 "Plant_Mode" 3 "Fault" 4 "Unknown" 5 "Reserved" 6 "Invalid value" ;
VAL_ 148 MntSet_Oil_HEC_Req 0 "Off" 1 "On" ;
VAL_ 148 TJA_Swtch_B_Actl 0 "Off" 1 "On" ;
VAL_ 148 LIM_Swtch_B_Actl 0 "Off" 1 "On" ;
VAL_ 148 MRCC_Swtch_B_Actl 0 "Off" 1 "On" ;
VAL_ 148 ASC_Swtch_B_Actl 0 "Off" 1 "On" ;
VAL_ 148 DistanceMinus_B_Actl 0 "Off" 1 "On" ;
VAL_ 148 DistancePlus_B_Actl 0 "Off" 1 "On" ;
VAL_ 148 OffSwtch_B_Actl 0 "Off" 1 "On" ;
VAL_ 148 ResumeSwtch_B_Actl 0 "Off" 1 "On" ;
VAL_ 148 SetMinusSwtch_B_Actl 0 "Off" 1 "On" ;
VAL_ 148 SetPlusSwtch_B_Actl 0 "Off" 1 "On" ;
VAL_ 148 CancelSwtch_B_Actl 0 "Off" 1 "On" ;
VAL_ 148 CruiseSwtch_Qf 0 "Invalid" 1 "Not Used" 2 "Not within Specification" 3 "OK" ;
VAL_ 146 PADI_Stat 0 "AirbagOn_illum_Off_illum" 1 "AirbagOn_illum_Off_Not_illum" 2 "AirbagOn_Not_illum_Off_illum" 3 "AirbagOn_Not_illum_Off_Not_illum" 4 "AirbagOn_Fault" 5 "AirbagOff_Fault" 6 "BothIndicatorFault" 7 "Invalid Value" 8 "Unknown" 9 "Reserved" ;
VAL_ 145 AEB_HEC_Fail_Flag 0 "Off" 1 "On" ;
VAL_ 145 Info_Status_B_Actl 0 "Off" 1 "On" ;
VAL_ 145 WiprTestMode_B_Actl 0 "Off" 1 "On" ;
VAL_ 145 SpAlarm_B_Actl 0 "Off" 1 "On" ;
VAL_ 145 PanelCont_D_Actl 0 "Off" 1 "PlusSW_depressed" 2 "MinusSW_depressed" 3 "BothSW_depressed" ;
VAL_ 145 AvgFuelEco_Rst_HEC 0 "Off" 1 "On" ;
VAL_ 145 PaddleShiftDwn_D_Actl 0 "Off" 1 "On" 2 "Reserved" 3 "Unknown" ;
VAL_ 145 PaddleShiftUp_D_Actl 0 "Off" 1 "On" 2 "Reserved" 3 "Unknown" ;
VAL_ 145 RearWasherSw_B_Actl 0 "Off" 1 "On" ;
VAL_ 145 FrntWasherSw_B_Actl 0 "Off" 1 "On" ;
VAL_ 145 RearWiprStats_D_Actl 0 "Off" 1 "RearWiperLo" 2 "Not defined" 3 "WiperINT" ;
VAL_ 145 FrntWiprStats_D_Actl 0 "OFF" 1 "FrontWiper On Lo" 2 "FrontWiper On Hi" 3 "FrontWiperINT Auto On" ;
VAL_ 145 WiprSw_D_Qf 0 "Faulty" 1 "Undefined" 2 "Not within Specification" 3 "OK" ;
VAL_ 145 Veh_speed_Fault 0 "Good Value" 1 "Faulty Value" ;
VAL_ 145 ALH_HBC_Sw_B_Actl 0 "OFF" 1 "ON" ;
VAL_ 145 Veh_speed_Unit 0 "km/h" 1 "mph" ;
VAL_ 145 Mfs_Turn_Stalk_SW_Status 0 "Turn OFF" 1 "Turn Right ON" 2 "Turn Left ON" 3 "Unknown" ;
VAL_ 145 HeadLghtOffSw_B_Actl 0 "Off" 1 "On" ;
VAL_ 145 PassngSw_B_Actl 0 "Off" 1 "On" ;
VAL_ 145 RearFogSw_B_Actl 0 "Off" 1 "On" ;
VAL_ 145 RSRmid_TmpOffReq 0 "Not Request" 1 "Request Set" ;
VAL_ 145 HeadLghtHiSw_B_Actl 0 "Off" 1 "On" ;
VAL_ 145 HeadLghtLoSw_B_Actl 0 "Off" 1 "On" ;
VAL_ 145 TnsSw_B_Actl 0 "Off" 1 "On" ;
VAL_ 145 LghtSw_D_Qf 0 "Faulty" 1 "Undefined/NotConfig" 2 "Not within Specification" 3 "OK" ;
VAL_ 137 HydraulicHold_TrqReqire 0 "Not Require" 1 "Require" ;
VAL_ 137 Abs_B_Falt_Echo 0 "No" 1 "Yes" ;
VAL_ 137 TsaCtlActv_B_Actl_Echo 0 "No" 1 "Yes" ;
VAL_ 137 RolStabCtlActv_B_Actl_Echo 0 "No" 1 "Yes" ;
VAL_ 137 PrplDrgCtlActv_B_Actl_Echo 0 "Inactive" 1 "Active" ;
VAL_ 137 TracCtlPtActv_B_Actl_Echo 0 "No" 1 "Yes" ;
VAL_ 137 TracCtlBrkActv_B_Actl_Echo 0 "No" 1 "Yes" ;
VAL_ 137 DSC_OnOff_status_1_Echo 0 "ON" 1 "OFF" ;
VAL_ 137 StabCtlBrkActv_B_Actl_Echo 0 "No" 1 "Yes" ;
VAL_ 137 BrkAsst_B_Actl_Echo 0 "No" 1 "Yes" ;
VAL_ 137 AbsActv_B_Actl_Echo 0 "No" 1 "Yes" ;
VAL_ 137 EbdActv_B_Actl_Echo 0 "No" 1 "Yes" ;
VAL_ 137 VehVActlBrk_D_Qf_Echo 0 "Faulty" 1 "No_Data_Exists" 2 "Not_Within_Specifications" 3 "OK" ;
VAL_ 136 ADAS_SteOnOff_D_Actl 0 "ON" 1 "OFF" 2 "OFF (Steering Hold Alert)" ;
VAL_ 136 ADAS_SteCtlActv_D_Actl 0 "Normal State" 1 "Standby" 2 "System Fail" ;
VAL_ 136 EPS_State_ADAS 0 "Normal" 1 "ADAS Control" 2 "Drv OverRide (Stay Drv Ctl)" 3 "Drv OverRide (Rtn ADAS Ctl)" ;
VAL_ 136 ADAS_SteInhbt_B_Flag 0 "Off" 1 "On" ;
VAL_ 135 SasCntComplt_B_Actl 0 "Calculating" 1 "Calculation Completed" ;
VAL_ 135 Sas_FailStatus 0 "Normal" 1 "Misassembly_Fault" 2 "Sas_Signal_Fault" 3 "Reserved" ;
VAL_ 135 SteWhlCompAnEst_D_Qf 0 "Before the absl Angle detection " 1 "Absl Angle Low Accuracy" 2 "Absl Angle High Accuracy" 3 "fail" ;
VAL_ 133 ADAS_Types_Str 0 "Normal" 1 "LKA" 2 "TJA" 3 "APS" 4 "ELK" 5 "LDP" 6 "BSP" 7 "EDA" ;
VAL_ 133 ADAS_SteCtlEnbl_D_Actl 0 "EPS Control Stop" 1 "EPS Control Enable" ;
VAL_ 133 ADAS_SteCtlFail_D_Actl 0 "Normal" 1 "System Fail" ;
VAL_ 133 ADAS_SteCtlCancl_D_Actl 0 "Normal" 1 "Stop" ;
VAL_ 133 ADAS_SteLdwCtl_D_Req 0 "No control" 1 "Left Departure Warning" 2 "Right Departure Warning" ;
VAL_ 132 SteAng_CalStart 0 "After CalculationStarted" 1 "CalStart or Calculation error or" ;
VAL_ 132 SteAngReltvAnSns_D_Qf 0 "Normal" 1 "Fault" 2 "Failed" 3 "Reserved" ;
VAL_ 132 SteAng_CalibStatus 0 "Not Initialization" 1 "Initialization Completed" ;
VAL_ 130 SteWhl_ChangeRateSign 0 "Left Turn" 1 "Right Turn" ;
VAL_ 130 SteWhl_CalibStatus 0 "Not Calib" 1 "Calib OK" ;
VAL_ 130 SteWhl_FailureStatus 0 "OK" 1 "Fail" ;
VAL_ 130 SteWhl_CalibRes 0 "Off" 1 "Accepted" 2 "Not Accepted" ;
VAL_ 128 FSC_AEB_Fail 0 "No Failure" 1 "Failure" ;
VAL_ 128 Req_AEB_VRU_Set_Flag 0 "OFF" 1 "ON" ;
VAL_ 128 AEB_VRU_Prefill_Level 0 "OFF" 1 "Level 1" 2 "Level 2" 3 "Level 3" ;
VAL_ 128 Req_AEB_VRU_Brake_Inhibit 0 "Permit" 1 "Inhibit" ;
VAL_ 127 AEB_VRU_state 0 "Not adopted" 1 "OFF" 2 "inactive" 3 "active" 4 "control" 5 "Notification" 13 "Temporary failure" 14 "Initialize" 15 "Failure" ;
VAL_ 126 Hdc_state 0 "off" 1 "standby" 2 "active" 3 "ramp out" 4 "cooling down" 5 "disable" 6 "reserved" ;
VAL_ 126 Drive_Mode_Towing_Req_DSC 0 "NG" 1 "OK" 2 "Not Determined" 3 "Invalid" ;
VAL_ 126 Drive_Mode_OffRoad_Req_DSC 0 "NG" 1 "OK" 2 "Not Determined" 3 "Invalid" ;
VAL_ 126 Drive_Mode_Normal_Req_DSC 0 "NG" 1 "OK" 2 "Not Determined" 3 "Invalid" ;
VAL_ 126 VacRelativePres_QF 0 "Faulty" 1 "No Data Exists" 2 "Not Within Specifications" 3 "OK" ;
VAL_ 126 DYC_StatusFlag 0 "Off" 1 "On" ;
VAL_ 126 HlaCtl_D_Actl 0 "not configured" 1 "Hold" 2 "Release" 3 "Passive" 4 "Fail" ;
VAL_ 124 HydraulicHoldCtl_D_Actl 0 "not configured" 1 "Not standby" 2 "Standby" 3 "Hold" 4 "Pressurize" 5 "Drive off" 6 "Release" 7 "Fail" ;
VAL_ 124 VehLatAActl_D_Qf 0 "Faulty" 1 "No data exists" 2 "Not within specifications" 3 "OK" ;
VAL_ 123 BrktStkAActl_D_Qf 0 "Faulty" 1 "No data exists" 2 "Not within specifications" 3 "OK" ;
VAL_ 123 RgnWhlTq_Rstr_B_Rq 0 "No" 1 "Yes" ;
VAL_ 123 RollerTestMode_B_Actl 0 "Not Activated" 1 "Activated" ;
VAL_ 123 BSCM_calc_CVN 0 "Not Calculating" 1 "Calculating CVN" ;
VAL_ 123 BSCM_DTC_Clear_Comp 0 "Not Complete" 1 "Complete" ;
VAL_ 123 EBBActv_B_Actl 0 "OFF" 1 "ON" ;
VAL_ 123 EBB_B_Falt 0 "No" 1 "Yes" ;
VAL_ 123 CHB_B_Falt 0 "No" 1 "Yes" ;
VAL_ 116 EPB_ExternalApply_D_Rq_DSC 0 "No request" 1 "not used" 2 "not used" 3 "Request" ;
VAL_ 116 SlaCtl_D_Actl 0 "not configured" 1 "Pressurize" 2 "Hold" 3 "Release" 4 "Passive" 5 "Fail" ;
VAL_ 116 BrkMstAActl_D_Qf 0 "Faulty" 1 "No data exists" 2 "Not within specifications" 3 "OK" ;
VAL_ 115 HDP_Enable_B_Actl 0 "Disable" 1 "Enable" ;
VAL_ 115 HDP_B_Falt 0 "No" 1 "Yes" ;
VAL_ 115 HDP_Echo 0 "Not active" 1 "Active" ;
VAL_ 115 StopLamp_D_RqArb 0 "Unknown" 1 "OFF" 2 "ON" 3 "Unknown" ;
VAL_ 115 VehLongAActl_D_Qf 0 "Faulty" 1 "No data exists" 2 "Not within specifications" 3 "OK" ;
VAL_ 114 Signal_State_Longitudinal_Accele 0 "Valid" 1 "Invalid" 2 "Potentially Invalid" 3 "Invalid Initialize" ;
VAL_ 113 Signal_State_Lateral_Acceleratio 0 "Valid" 1 "Invalid" 2 "Potentially Invalid" 3 "Invalid Initialize" ;
VAL_ 112 Signal_State_Yaw_Rate 0 "Valid" 1 "Invalid" 2 "Potentially Invalid" 3 "Invalid Initialize" ;
VAL_ 80 Clutch_Cut_Switch_Status 0 "Unknown" 1 "Off" 2 "On" 3 "Invalid" ;
VAL_ 80 SKE_IR_Request 0 "Idle" 1 "IR Request" ;
VAL_ 80 SKE_SISS_Status 0 "Idle" 1 "IS Wait" 2 "IS Enable" 3 "IS Disable" 4 "IR Wait" 5 "IR Disable" 6 "IR Crank" 15 "Invalid" ;
VAL_ 80 SKE_SISS_Mode 0 "Idle" 1 "SISS mode" ;
VAL_ 80 CrankStat_B_Actl 0 "Off" 1 "On" ;
VAL_ 80 AutoP_Request 0 "Not Request" 1 "AutoP Request" 2 "Reserved" 3 "Reserved" ;
VAL_ 80 IG_OFF_Delay_State 0 "OFF" 1 "ON" ;
VAL_ 80 IG_mode 0 "Normal" 1 "Service" ;
VAL_ 80 PowerControlStatus 0 "OFF" 1 "ACC" 2 "ON" 3 "CRANK" ;
VAL_ 74 threshold_over_fst 1 "Collision_yes" 2 "Collision_no(initial value confi" ;
